VERSION ""

NS_ :

BS_:

BU_: WCM4 WCM3 WCM2 WCM VPM VLM VKM VICM VECM VDM VCU_RTOS_ETH VCU_ENTRY_ETH VCU_AGVM_ETH VCU UVM UPM TIM TEST_TOOL_1 TCP_ETH TCP TCM TCCM SRR_SRR_ETH SRR_SRR SRR_SLR_ETH SRR_SLR SRR_RR SRR_RF_ETH SRR_RF SRR_LR_CR SRR_LF_ETH SRR_LF SIB SDM SCL SBZA_R SBZA_L SBM SAM_RR SAM_RF SAM_LR SAM_LF SAM_BH SADS RadioLow_ETH RadioLow RSI_RTOS_ETH RSI RDCM PTM PLCM PFCM PDR_ETH PDR PCM PA ODS2 ODS NVM MTCM_R MTCM_L MSM_RR MSM_P MSM_LR MSM_D MSB2 MSB1 MRCM_R MRCM_L MFC LRR_RR_ETH LRR_LR_ETH LRR_CF_ETH LRR LRL_CF_ETH LIB_48V LIB1 IPC_INT IPC_GP IPC ICS_Info ICCM HVAC_FP_R HVAC_FP_F HUD_CAN HDLM FPI_RTOS_ETH FPI FOPM FCM_LC FCM EPSb EPS_1 EPSRAb EPSRAa EPS EOCM_HC_Superset EOCM_HCP2 EOCM ELM ECP_X1 ECP_S2 ECP_S ECP_MC ECP_H3 ECP_H2 ECP_H1 ECP_E ECM EBCM DMS DEFC DCM CSM_ETH CSM_AV CSM CGM_OTA_ETH CGM BSM_MH BSM_HEV BSM BCM ARS ARB APA AOS AMP ALC AHS AHL_AFL ADIMb ADIMa ACP2_MCU

BO_ 69 PDU_8065: 20 FCM_LC
 SG_ AdpLgtHstLnLtCrv : 7|16@0- (9.77e-07,0) [-0.0320143|0.0320134] "1/m" Vector__XXX
 SG_ AdpLgtHstLnLtCrvDrvt : 23|16@0- (3.73e-09,0) [-0.000122225|0.000122221] "1/m^2" Vector__XXX
 SG_ AdpLgtHstLnRtCrv : 39|16@0- (9.77e-07,0) [-0.0320143|0.0320134] "1/m" Vector__XXX
 SG_ AdpLgtHstLnRtCrvDrvt : 55|16@0- (3.73e-09,0) [-0.000122225|0.000122221] "1/m^2" Vector__XXX
 SG_ AdpLgtHstLnLtOfst : 71|13@0- (0.003906,0) [-15.999|15.9951] "m" Vector__XXX
 SG_ AdpLgtHstLnRtOfst : 74|13@0- (0.003906,0) [-15.999|15.9951] "m" Vector__XXX
 SG_ AdpLgtHstLnLtHdg : 93|10@0- (0.000977,0) [-0.500224|0.499247] "rad" Vector__XXX
 SG_ AdpLgtHstLnRtHdg : 99|10@0- (0.000977,0) [-0.500224|0.499247] "rad" Vector__XXX
 SG_ AdpLgtHstLnLtVwRngLngDist : 105|7@0+ (1,0) [0|127] "m" Vector__XXX
 SG_ AdpLgtHstLnLtVwStrtLngDist : 114|7@0+ (1,0) [0|127] "m" Vector__XXX
 SG_ AdpLgtHstLnRtVwRngLngDist : 123|7@0+ (1,0) [0|127] "m" Vector__XXX
 SG_ AdpLgtHstLnRtVwStrtLngDist : 132|7@0+ (1,0) [0|127] "m" Vector__XXX
 SG_ AdpLgtHstLnLtWdth : 141|6@0+ (0.01,0) [0|0.63] "m" Vector__XXX
 SG_ AdpLgtHstLnLtTyp : 145|3@0+ (1,0) [0|7] "" Vector__XXX
 SG_ AdpLgtHstLnRtWdth : 151|6@0+ (0.01,0) [0|0.63] "m" Vector__XXX
 SG_ AdpLgtHstLnRtQlty : 153|2@0+ (1,0) [0|3] "" Vector__XXX
 SG_ AdpLgtHstLnLtQlty : 155|2@0+ (1,0) [0|3] "" Vector__XXX
 SG_ AdpLgtHstLnRtTyp : 158|3@0+ (1,0) [0|7] "" Vector__XXX

BO_ 225 PDU_8066: 48 FCM_LC
 SG_ ALOI3_RngTk10 : 7|16@0+ (0.02,0) [0|1310.7] "m" Vector__XXX
 SG_ ALOI3_RngTk11 : 23|16@0+ (0.02,0) [0|1310.7] "m" Vector__XXX
 SG_ ALOI3_RngTk12 : 39|16@0+ (0.02,0) [0|1310.7] "m" Vector__XXX
 SG_ ALOI3_RngTk9 : 55|16@0+ (0.02,0) [0|1310.7] "m" Vector__XXX
 SG_ ALOI3_AcqTmStm : 71|11@0+ (1,0) [0|2047] "ms" Vector__XXX
 SG_ ALOI3_AzmRateTk10 : 76|11@0+ (0.125,-128) [-128|127.875] "deg/s" Vector__XXX
 SG_ ALOI3_AzmRateTk11 : 81|11@0+ (0.125,-128) [-128|127.875] "deg/s" Vector__XXX
 SG_ ALOI3_AzmRateTk12 : 102|11@0+ (0.125,-128) [-128|127.875] "deg/s" Vector__XXX
 SG_ ALOI3_AzmRateTk9 : 107|11@0+ (0.125,-128) [-128|127.875] "deg/s" Vector__XXX
 SG_ ALOI3_AzmTk10 : 112|11@0+ (0.05,-51.2) [-51.2|51.15] "deg" Vector__XXX
 SG_ ALOI3_AzmTk11 : 133|11@0+ (0.05,-51.2) [-51.2|51.15] "deg" Vector__XXX
 SG_ ALOI3_AzmTk12 : 138|11@0+ (0.05,-51.2) [-51.2|51.15] "deg" Vector__XXX
 SG_ ALOI3_AzmTk9 : 159|11@0+ (0.05,-51.2) [-51.2|51.15] "deg" Vector__XXX
 SG_ ALOI3_WdthTk10 : 164|11@0+ (0.1,0) [0|204.7] "deg" Vector__XXX
 SG_ ALOI3_WdthTk11 : 169|11@0+ (0.1,0) [0|204.7] "deg" Vector__XXX
 SG_ ALOI3_WdthTk12 : 190|11@0+ (0.1,0) [0|204.7] "deg" Vector__XXX
 SG_ ALOI3_WdthTk9 : 195|11@0+ (0.1,0) [0|204.7] "deg" Vector__XXX
 SG_ ALOI3_RdSigGlrngTk10 : 200|7@0+ (1,0) [0|127] "%" Vector__XXX
 SG_ ALOI3_RdSigGlrngTk11 : 209|7@0+ (1,0) [0|127] "%" Vector__XXX
 SG_ ALOI3_RdSigGlrngTk12 : 218|7@0+ (1,0) [0|127] "%" Vector__XXX
 SG_ ALOI3_RdSigGlrngTk9 : 227|7@0+ (1,0) [0|127] "%" Vector__XXX
 SG_ ALOI3_IDTk10 : 236|6@0+ (1,0) [0|63] "" Vector__XXX
 SG_ ALOI3_IDTk12 : 240|6@0+ (1,0) [0|63] "" Vector__XXX
 SG_ ALOI3_IDTk11 : 246|6@0+ (1,0) [0|63] "" Vector__XXX
 SG_ ALOI3_IDTk9 : 250|6@0+ (1,0) [0|63] "" Vector__XXX
 SG_ ALOI3_VertPstnTk10 : 260|6@0+ (0.25,-3) [-3|12.75] "deg" Vector__XXX
 SG_ ALOI3_VertPstnTk12 : 264|6@0+ (0.25,-3) [-3|12.75] "deg" Vector__XXX
 SG_ ALOI3_VertPstnTk11 : 270|6@0+ (0.25,-3) [-3|12.75] "deg" Vector__XXX
 SG_ ALOI3_VertPstnTk9 : 274|6@0+ (0.25,-3) [-3|12.75] "deg" Vector__XXX
 SG_ ALOI3_TypTk11 : 280|4@0+ (1,0) [0|12] "" Vector__XXX
 SG_ ALOI3_TypTk10 : 284|4@0+ (1,0) [0|12] "" Vector__XXX
 SG_ ALOI3_TypTk9 : 288|4@0+ (1,0) [0|12] "" Vector__XXX
 SG_ ALOI3_TypTk12 : 292|4@0+ (1,0) [0|12] "" Vector__XXX
 SG_ ALOI3_DirTk11 : 297|3@0+ (1,0) [0|4] "" Vector__XXX
 SG_ ALOI3_DirTk10 : 300|3@0+ (1,0) [0|4] "" Vector__XXX
 SG_ ALOI3_ARC : 304|2@0+ (1,0) [0|3] "" Vector__XXX
 SG_ ALOI3_DirTk9 : 307|3@0+ (1,0) [0|4] "" Vector__XXX
 SG_ ALOI3_DirTk12 : 310|3@0+ (1,0) [0|4] "" Vector__XXX
 SG_ ALOI3_CnfdTk9 : 312|2@0+ (1,0) [0|3] "" Vector__XXX
 SG_ ALOI3_CnfdTk12 : 314|2@0+ (1,0) [0|3] "" Vector__XXX
 SG_ ALOI3_CnfdTk11 : 316|2@0+ (1,0) [0|3] "" Vector__XXX
 SG_ ALOI3_CnfdTk10 : 318|2@0+ (1,0) [0|3] "" Vector__XXX
 SG_ ALOI3_MeasStsTk9 : 320|2@0+ (1,0) [0|3] "" Vector__XXX
 SG_ ALOI3_MeasStsTk12 : 322|2@0+ (1,0) [0|3] "" Vector__XXX
 SG_ ALOI3_MeasStsTk11 : 324|2@0+ (1,0) [0|3] "" Vector__XXX
 SG_ ALOI3_MeasStsTk10 : 326|2@0+ (1,0) [0|3] "" Vector__XXX
 SG_ ALOI3_RltvLnTk9 : 328|2@0+ (1,0) [0|3] "" Vector__XXX
 SG_ ALOI3_RltvLnTk12 : 330|2@0+ (1,0) [0|3] "" Vector__XXX
 SG_ ALOI3_RltvLnTk11 : 332|2@0+ (1,0) [0|3] "" Vector__XXX
 SG_ ALOI3_RltvLnTk10 : 334|2@0+ (1,0) [0|3] "" Vector__XXX
 SG_ TrfcSgnMemFtrSts : 337|2@0+ (1,0) [0|2] "" Vector__XXX
 SG_ ALOI3_RngTk9_Inv : 338|1@0+ (1,0) [0|1] "" Vector__XXX
 SG_ ALOI3_RngTk12_Inv : 339|1@0+ (1,0) [0|1] "" Vector__XXX
 SG_ ALOI3_RngTk11_Inv : 340|1@0+ (1,0) [0|1] "" Vector__XXX
 SG_ ALOI3_RngTk10_Inv : 341|1@0+ (1,0) [0|1] "" Vector__XXX
 SG_ ALOI3_AcqTmStm_Inv : 342|1@0+ (1,0) [0|1] "" Vector__XXX

BO_ 1444 PDU_9064: 2 CGM
 SG_ VehIdNmDig1 : 7|8@0+ (1,0) [0|255] "" HDLM

BO_ 963 NodeStatus_CAN8_PDU01: 8 CGM
 SG_ NodeStsADIMb_CAN_9_LcFA : 0|1@0+ (1,0) [0|1] "" EOCM_HCP2,FCM_LC,HDLM,LRR,SRR_LF,SRR_LR_CR,SRR_RF,SRR_RR,SRR_SLR,SRR_SRR,UPM
 SG_ NodeStsADIMb_CAN_3_LcFA : 1|1@0+ (1,0) [0|1] "" EOCM_HCP2,FCM_LC,HDLM,LRR,SRR_LF,SRR_LR_CR,SRR_RF,SRR_RR,SRR_SLR,SRR_SRR,UPM
 SG_ NodeStsADIMb_CAN_2_LcFA : 2|1@0+ (1,0) [0|1] "" EOCM_HCP2,FCM_LC,HDLM,LRR,SRR_LF,SRR_LR_CR,SRR_RF,SRR_RR,SRR_SLR,SRR_SRR,UPM
 SG_ NodeStsADIMb_CAN_10_LcFA : 3|1@0+ (1,0) [0|1] "" EOCM_HCP2,FCM_LC,HDLM,LRR,SRR_LF,SRR_LR_CR,SRR_RF,SRR_RR,SRR_SLR,SRR_SRR,UPM
 SG_ NodeStsADIMa_CAN_9_LcFA : 4|1@0+ (1,0) [0|1] "" EOCM_HCP2,FCM_LC,HDLM,LRR,SRR_LF,SRR_LR_CR,SRR_RF,SRR_RR,SRR_SLR,SRR_SRR,UPM
 SG_ NodeStsADIMa_CAN_3_LcFA : 5|1@0+ (1,0) [0|1] "" EOCM_HCP2,FCM_LC,HDLM,LRR,SRR_LF,SRR_LR_CR,SRR_RF,SRR_RR,SRR_SLR,SRR_SRR,UPM
 SG_ NodeStsADIMa_CAN_2_LcFA : 6|1@0+ (1,0) [0|1] "" EOCM_HCP2,FCM_LC,HDLM,LRR,SRR_LF,SRR_LR_CR,SRR_RF,SRR_RR,SRR_SLR,SRR_SRR,UPM
 SG_ NodeStsADIMa_CAN_10_LcFA : 7|1@0+ (1,0) [0|1] "" EOCM_HCP2,FCM_LC,HDLM,LRR,SRR_LF,SRR_LR_CR,SRR_RF,SRR_RR,SRR_SLR,SRR_SRR,UPM
 SG_ NodeStsAPA_CAN_1_LcFA : 8|1@0+ (1,0) [0|1] "" EOCM_HCP2,FCM_LC,HDLM,LRR,SRR_LF,SRR_LR_CR,SRR_RF,SRR_RR,SRR_SLR,SRR_SRR,UPM
 SG_ NodeStsAOS_LcFA : 10|1@0+ (1,0) [0|1] "" EOCM_HCP2,FCM_LC,HDLM,LRR,SRR_LF,SRR_LR_CR,SRR_RF,SRR_RR,SRR_SLR,SRR_SRR,UPM
 SG_ NodeStsAMP_LcFA : 11|1@0+ (1,0) [0|1] "" EOCM_HCP2,FCM_LC,HDLM,LRR,SRR_LF,SRR_LR_CR,SRR_RF,SRR_RR,SRR_SLR,SRR_SRR,UPM
 SG_ NodeStsALC_LcFA : 12|1@0+ (1,0) [0|1] "" EOCM_HCP2,FCM_LC,HDLM,LRR,SRR_LF,SRR_LR_CR,SRR_RF,SRR_RR,SRR_SLR,SRR_SRR,UPM
 SG_ NodeStsAHS_LcFA : 13|1@0+ (1,0) [0|1] "" EOCM_HCP2,FCM_LC,HDLM,LRR,SRR_LF,SRR_LR_CR,SRR_RF,SRR_RR,SRR_SLR,SRR_SRR,UPM
 SG_ NodeStsAHL_AFL_CAN_2_LcFA : 14|1@0+ (1,0) [0|1] "" EOCM_HCP2,FCM_LC,HDLM,LRR,SRR_LF,SRR_LR_CR,SRR_RF,SRR_RR,SRR_SLR,SRR_SRR,UPM
 SG_ NodeStsBSM_MH_LcFA : 17|1@0+ (1,0) [0|1] "" EOCM_HCP2,FCM_LC,HDLM,LRR,SRR_LF,SRR_LR_CR,SRR_RF,SRR_RR,SRR_SLR,SRR_SRR,UPM
 SG_ NodeStsBSM_CAN_3_LcFA : 18|1@0+ (1,0) [0|1] "" EOCM_HCP2,FCM_LC,HDLM,LRR,SRR_LF,SRR_LR_CR,SRR_RF,SRR_RR,SRR_SLR,SRR_SRR,UPM
 SG_ NodeStsBSM_CAN_2_LcFA : 19|1@0+ (1,0) [0|1] "" EOCM_HCP2,FCM_LC,HDLM,LRR,SRR_LF,SRR_LR_CR,SRR_RF,SRR_RR,SRR_SLR,SRR_SRR,UPM
 SG_ NodeStsBCM_LcFA : 20|1@0+ (1,0) [0|1] "" EOCM_HCP2,FCM_LC,HDLM,LRR,SRR_LF,SRR_LR_CR,SRR_RF,SRR_RR,SRR_SLR,SRR_SRR,UPM
 SG_ NodeStsARS_LcFA : 21|1@0+ (1,0) [0|1] "" EOCM_HCP2,FCM_LC,HDLM,LRR,SRR_LF,SRR_LR_CR,SRR_RF,SRR_RR,SRR_SLR,SRR_SRR,UPM
 SG_ NodeStsARB_LcFA : 22|1@0+ (1,0) [0|1] "" EOCM_HCP2,FCM_LC,HDLM,LRR,SRR_LF,SRR_LR_CR,SRR_RF,SRR_RR,SRR_SLR,SRR_SRR,UPM
 SG_ NodeStsAPA_CAN_2_LcFA : 23|1@0+ (1,0) [0|1] "" EOCM_HCP2,FCM_LC,HDLM,LRR,SRR_LF,SRR_LR_CR,SRR_RF,SRR_RR,SRR_SLR,SRR_SRR,UPM
 SG_ NodeStsEBCM_AV_CAN_2_LcFA : 24|1@0+ (1,0) [0|1] "" EOCM_HCP2,FCM_LC,HDLM,LRR,SRR_LF,SRR_LR_CR,SRR_RF,SRR_RR,SRR_SLR,SRR_SRR,UPM
 SG_ NodeStsDMS_LcFA : 25|1@0+ (1,0) [0|1] "" EOCM_HCP2,FCM_LC,HDLM,LRR,SRR_LF,SRR_LR_CR,SRR_RF,SRR_RR,SRR_SLR,SRR_SRR,UPM
 SG_ NodeStsDEFC_LcFA : 26|1@0+ (1,0) [0|1] "" EOCM_HCP2,FCM_LC,HDLM,LRR,SRR_LF,SRR_LR_CR,SRR_RF,SRR_RR,SRR_SLR,SRR_SRR,UPM
 SG_ NodeStsDCM_LcFA : 27|1@0+ (1,0) [0|1] "" EOCM_HCP2,FCM_LC,HDLM,LRR,SRR_LF,SRR_LR_CR,SRR_RF,SRR_RR,SRR_SLR,SRR_SRR,UPM
 SG_ NodeStsCSM_CAN_5_LcFA : 28|1@0+ (1,0) [0|1] "" EOCM_HCP2,FCM_LC,HDLM,LRR,SRR_LF,SRR_LR_CR,SRR_RF,SRR_RR,SRR_SLR,SRR_SRR,UPM
 SG_ NodeStsECP_E_CAN_9_LcFA : 32|1@0+ (1,0) [0|1] "" EOCM_HCP2,FCM_LC,HDLM,LRR,SRR_LF,SRR_LR_CR,SRR_RF,SRR_RR,SRR_SLR,SRR_SRR,UPM
 SG_ NodeStsECP_E_CAN_2_LcFA : 33|1@0+ (1,0) [0|1] "" EOCM_HCP2,FCM_LC,HDLM,LRR,SRR_LF,SRR_LR_CR,SRR_RF,SRR_RR,SRR_SLR,SRR_SRR,UPM
 SG_ NodeStsECM_CAN_3_LcFA : 34|1@0+ (1,0) [0|1] "" EOCM_HCP2,FCM_LC,HDLM,LRR,SRR_LF,SRR_LR_CR,SRR_RF,SRR_RR,SRR_SLR,SRR_SRR,UPM
 SG_ NodeStsECM_CAN_2_LcFA : 35|1@0+ (1,0) [0|1] "" EOCM_HCP2,FCM_LC,HDLM,LRR,SRR_LF,SRR_LR_CR,SRR_RF,SRR_RR,SRR_SLR,SRR_SRR,UPM
 SG_ NodeStsEBCM_CAN_3_LcFA : 37|1@0+ (1,0) [0|1] "" EOCM_HCP2,FCM_LC,HDLM,LRR,SRR_LF,SRR_LR_CR,SRR_RF,SRR_RR,SRR_SLR,SRR_SRR,UPM
 SG_ NodeStsEBCM_CAN_2_LcFA : 38|1@0+ (1,0) [0|1] "" EOCM_HCP2,FCM_LC,HDLM,LRR,SRR_LF,SRR_LR_CR,SRR_RF,SRR_RR,SRR_SLR,SRR_SRR,UPM
 SG_ NodeStsEBCM_AV_CAN_3_LcFA : 39|1@0+ (1,0) [0|1] "" EOCM_HCP2,FCM_LC,HDLM,LRR,SRR_LF,SRR_LR_CR,SRR_RF,SRR_RR,SRR_SLR,SRR_SRR,UPM
 SG_ NodeStsEOCM_CAN_3_LcFA : 40|1@0+ (1,0) [0|1] "" EOCM_HCP2,FCM_LC,HDLM,LRR,SRR_LF,SRR_LR_CR,SRR_RF,SRR_RR,SRR_SLR,SRR_SRR,UPM
 SG_ NodeStsEOCM_CAN_2_LcFA : 41|1@0+ (1,0) [0|1] "" EOCM_HCP2,FCM_LC,HDLM,LRR,SRR_LF,SRR_LR_CR,SRR_RF,SRR_RR,SRR_SLR,SRR_SRR,UPM
 SG_ NodeStsELM_LcFA : 42|1@0+ (1,0) [0|1] "" EOCM_HCP2,FCM_LC,HDLM,LRR,SRR_LF,SRR_LR_CR,SRR_RF,SRR_RR,SRR_SLR,SRR_SRR,UPM
 SG_ NodeStsECP_X1_CAN_3_LcFA : 43|1@0+ (1,0) [0|1] "" EOCM_HCP2,FCM_LC,HDLM,LRR,SRR_LF,SRR_LR_CR,SRR_RF,SRR_RR,SRR_SLR,SRR_SRR,UPM
 SG_ NodeStsECP_X1_CAN_2_LcFA : 44|1@0+ (1,0) [0|1] "" EOCM_HCP2,FCM_LC,HDLM,LRR,SRR_LF,SRR_LR_CR,SRR_RF,SRR_RR,SRR_SLR,SRR_SRR,UPM
 SG_ NodeStsECP_S_CAN_9_LcFA : 45|1@0+ (1,0) [0|1] "" EOCM_HCP2,FCM_LC,HDLM,LRR,SRR_LF,SRR_LR_CR,SRR_RF,SRR_RR,SRR_SLR,SRR_SRR,UPM
 SG_ NodeStsECP_S_CAN_2_LcFA : 46|1@0+ (1,0) [0|1] "" EOCM_HCP2,FCM_LC,HDLM,LRR,SRR_LF,SRR_LR_CR,SRR_RF,SRR_RR,SRR_SLR,SRR_SRR,UPM
 SG_ NodeStsECP_MC_LcFA : 47|1@0+ (1,0) [0|1] "" EOCM_HCP2,FCM_LC,HDLM,LRR,SRR_LF,SRR_LR_CR,SRR_RF,SRR_RR,SRR_SLR,SRR_SRR,UPM
 SG_ NodeStsEPSRAa_LcFA : 48|1@0+ (1,0) [0|1] "" EOCM_HCP2,FCM_LC,HDLM,LRR,SRR_LF,SRR_LR_CR,SRR_RF,SRR_RR,SRR_SLR,SRR_SRR,UPM
 SG_ NodeStsEPS_LcFA : 49|1@0+ (1,0) [0|1] "" EOCM_HCP2,FCM_LC,HDLM,LRR,SRR_LF,SRR_LR_CR,SRR_RF,SRR_RR,SRR_SLR,SRR_SRR,UPM
 SG_ NodeStsEPS_1_LcFA : 50|1@0+ (1,0) [0|1] "" EOCM_HCP2,FCM_LC,HDLM,LRR,SRR_LF,SRR_LR_CR,SRR_RF,SRR_RR,SRR_SLR,SRR_SRR,UPM
 SG_ NodeStsEOCM_HCP2_LcFA : 51|1@0+ (1,0) [0|1] "" FCM_LC,HDLM,LRR,SRR_LF,SRR_LR_CR,SRR_RF,SRR_RR,SRR_SLR,SRR_SRR,UPM
 SG_ NodeStsEOCM_HCP1_CAN_8_LcFA : 52|1@0+ (1,0) [0|1] "" EOCM_HCP2,FCM_LC,HDLM,LRR,SRR_LF,SRR_LR_CR,SRR_RF,SRR_RR,SRR_SLR,SRR_SRR,UPM
 SG_ NodeStsEOCM_HCP1_CAN_3_LcFA : 53|1@0+ (1,0) [0|1] "" EOCM_HCP2,FCM_LC,HDLM,LRR,SRR_LF,SRR_LR_CR,SRR_RF,SRR_RR,SRR_SLR,SRR_SRR,UPM
 SG_ NodeStsEOCM_HCP1_CAN_2_LcFA : 54|1@0+ (1,0) [0|1] "" EOCM_HCP2,FCM_LC,HDLM,LRR,SRR_LF,SRR_LR_CR,SRR_RF,SRR_RR,SRR_SLR,SRR_SRR,UPM
 SG_ NodeStsEOCM_CAN_8_LcFA : 55|1@0+ (1,0) [0|1] "" EOCM_HCP2,FCM_LC,HDLM,LRR,SRR_LF,SRR_LR_CR,SRR_RF,SRR_RR,SRR_SLR,SRR_SRR,UPM
 SG_ NodeStsHVAC_FP_F_LcFA : 56|1@0+ (1,0) [0|1] "" EOCM_HCP2,FCM_LC,HDLM,LRR,SRR_LF,SRR_LR_CR,SRR_RF,SRR_RR,SRR_SLR,SRR_SRR,UPM
 SG_ NodeStsHUD_CAN_LcFA : 57|1@0+ (1,0) [0|1] "" EOCM_HCP2,FCM_LC,HDLM,LRR,SRR_LF,SRR_LR_CR,SRR_RF,SRR_RR,SRR_SLR,SRR_SRR,UPM
 SG_ NodeStsHDLM_LcFA : 58|1@0+ (1,0) [0|1] "" EOCM_HCP2,FCM_LC,LRR,SRR_LF,SRR_LR_CR,SRR_RF,SRR_RR,SRR_SLR,SRR_SRR,UPM
 SG_ NodeStsFOPM_CAN_3_LcFA : 59|1@0+ (1,0) [0|1] "" EOCM_HCP2,FCM_LC,HDLM,LRR,SRR_LF,SRR_LR_CR,SRR_RF,SRR_RR,SRR_SLR,SRR_SRR,UPM
 SG_ NodeStsFOPM_CAN_2_LcFA : 60|1@0+ (1,0) [0|1] "" EOCM_HCP2,FCM_LC,HDLM,LRR,SRR_LF,SRR_LR_CR,SRR_RF,SRR_RR,SRR_SLR,SRR_SRR,UPM
 SG_ NodeStsFCM_LcFA : 61|1@0+ (1,0) [0|1] "" EOCM_HCP2,FCM_LC,HDLM,LRR,SRR_LF,SRR_LR_CR,SRR_RF,SRR_RR,SRR_SLR,SRR_SRR,UPM
 SG_ NodeStsFCM_LC_LcFA : 62|1@0+ (1,0) [0|1] "" EOCM_HCP2,HDLM,LRR,SRR_LF,SRR_LR_CR,SRR_RF,SRR_RR,SRR_SLR,SRR_SRR,UPM
 SG_ NodeStsEPSRAb_LcFA : 63|1@0+ (1,0) [0|1] "" EOCM_HCP2,FCM_LC,HDLM,LRR,SRR_LF,SRR_LR_CR,SRR_RF,SRR_RR,SRR_SLR,SRR_SRR,UPM

BO_ 964 NodeStatus_CAN8_PDU02: 8 CGM
 SG_ NodeStsMFC_LcFA : 0|1@0+ (1,0) [0|1] "" EOCM_HCP2,FCM_LC,HDLM,LRR,SRR_LF,SRR_LR_CR,SRR_RF,SRR_RR,SRR_SLR,SRR_SRR,UPM
 SG_ NodeStsLRR_LcFA : 1|1@0+ (1,0) [0|1] "" EOCM_HCP2,FCM_LC,HDLM,SRR_LF,SRR_LR_CR,SRR_RF,SRR_RR,SRR_SLR,SRR_SRR,UPM
 SG_ NodeStsLIB1_LcFA : 3|1@0+ (1,0) [0|1] "" EOCM_HCP2,FCM_LC,HDLM,LRR,SRR_LF,SRR_LR_CR,SRR_RF,SRR_RR,SRR_SLR,SRR_SRR,UPM
 SG_ NodeStsIPC_CAN_5_LcFA : 4|1@0+ (1,0) [0|1] "" EOCM_HCP2,FCM_LC,HDLM,LRR,SRR_LF,SRR_LR_CR,SRR_RF,SRR_RR,SRR_SLR,SRR_SRR,UPM
 SG_ NodeStsICS_Info_LcFA : 5|1@0+ (1,0) [0|1] "" EOCM_HCP2,FCM_LC,HDLM,LRR,SRR_LF,SRR_LR_CR,SRR_RF,SRR_RR,SRR_SLR,SRR_SRR,UPM
 SG_ NodeStsICCM_CAN_3_LcFA : 6|1@0+ (1,0) [0|1] "" EOCM_HCP2,FCM_LC,HDLM,LRR,SRR_LF,SRR_LR_CR,SRR_RF,SRR_RR,SRR_SLR,SRR_SRR,UPM
 SG_ NodeStsHVAC_FP_R_LcFA : 7|1@0+ (1,0) [0|1] "" EOCM_HCP2,FCM_LC,HDLM,LRR,SRR_LF,SRR_LR_CR,SRR_RF,SRR_RR,SRR_SLR,SRR_SRR,UPM
 SG_ NodeStsMSM_RR_LcFA : 8|1@0+ (1,0) [0|1] "" EOCM_HCP2,FCM_LC,HDLM,LRR,SRR_LF,SRR_LR_CR,SRR_RF,SRR_RR,SRR_SLR,SRR_SRR,UPM
 SG_ NodeStsMSM_P_LcFA : 9|1@0+ (1,0) [0|1] "" EOCM_HCP2,FCM_LC,HDLM,LRR,SRR_LF,SRR_LR_CR,SRR_RF,SRR_RR,SRR_SLR,SRR_SRR,UPM
 SG_ NodeStsMSM_LR_LcFA : 10|1@0+ (1,0) [0|1] "" EOCM_HCP2,FCM_LC,HDLM,LRR,SRR_LF,SRR_LR_CR,SRR_RF,SRR_RR,SRR_SLR,SRR_SRR,UPM
 SG_ NodeStsMSM_D_LcFA : 11|1@0+ (1,0) [0|1] "" EOCM_HCP2,FCM_LC,HDLM,LRR,SRR_LF,SRR_LR_CR,SRR_RF,SRR_RR,SRR_SLR,SRR_SRR,UPM
 SG_ NodeStsMSB2_LcFA : 12|1@0+ (1,0) [0|1] "" EOCM_HCP2,FCM_LC,HDLM,LRR,SRR_LF,SRR_LR_CR,SRR_RF,SRR_RR,SRR_SLR,SRR_SRR,UPM
 SG_ NodeStsMSB1_LcFA : 13|1@0+ (1,0) [0|1] "" EOCM_HCP2,FCM_LC,HDLM,LRR,SRR_LF,SRR_LR_CR,SRR_RF,SRR_RR,SRR_SLR,SRR_SRR,UPM
 SG_ NodeStsMRCM_R_LcFA : 14|1@0+ (1,0) [0|1] "" EOCM_HCP2,FCM_LC,HDLM,LRR,SRR_LF,SRR_LR_CR,SRR_RF,SRR_RR,SRR_SLR,SRR_SRR,UPM
 SG_ NodeStsMRCM_L_LcFA : 15|1@0+ (1,0) [0|1] "" EOCM_HCP2,FCM_LC,HDLM,LRR,SRR_LF,SRR_LR_CR,SRR_RF,SRR_RR,SRR_SLR,SRR_SRR,UPM
 SG_ NodeStsRDCM_LcFA : 16|1@0+ (1,0) [0|1] "" EOCM_HCP2,FCM_LC,HDLM,LRR,SRR_LF,SRR_LR_CR,SRR_RF,SRR_RR,SRR_SLR,SRR_SRR,UPM
 SG_ NodeStsRadioLow_LcFA : 17|1@0+ (1,0) [0|1] "" EOCM_HCP2,FCM_LC,HDLM,LRR,SRR_LF,SRR_LR_CR,SRR_RF,SRR_RR,SRR_SLR,SRR_SRR,UPM
 SG_ NodeStsPTM_LcFA : 18|1@0+ (1,0) [0|1] "" EOCM_HCP2,FCM_LC,HDLM,LRR,SRR_LF,SRR_LR_CR,SRR_RF,SRR_RR,SRR_SLR,SRR_SRR,UPM
 SG_ NodeStsPDR_LcFA : 19|1@0+ (1,0) [0|1] "" EOCM_HCP2,FCM_LC,HDLM,LRR,SRR_LF,SRR_LR_CR,SRR_RF,SRR_RR,SRR_SLR,SRR_SRR,UPM
 SG_ NodeStsPA_LcFA : 20|1@0+ (1,0) [0|1] "" EOCM_HCP2,FCM_LC,HDLM,LRR,SRR_LF,SRR_LR_CR,SRR_RF,SRR_RR,SRR_SLR,SRR_SRR,UPM
 SG_ NodeStsNVM_LcFA : 21|1@0+ (1,0) [0|1] "" EOCM_HCP2,FCM_LC,HDLM,LRR,SRR_LF,SRR_LR_CR,SRR_RF,SRR_RR,SRR_SLR,SRR_SRR,UPM
 SG_ NodeStsMTCM_R_LcFA : 22|1@0+ (1,0) [0|1] "" EOCM_HCP2,FCM_LC,HDLM,LRR,SRR_LF,SRR_LR_CR,SRR_RF,SRR_RR,SRR_SLR,SRR_SRR,UPM
 SG_ NodeStsMTCM_L_LcFA : 23|1@0+ (1,0) [0|1] "" EOCM_HCP2,FCM_LC,HDLM,LRR,SRR_LF,SRR_LR_CR,SRR_RF,SRR_RR,SRR_SLR,SRR_SRR,UPM
 SG_ NodeStsSBM_CAN_3_LcFA : 25|1@0+ (1,0) [0|1] "" EOCM_HCP2,FCM_LC,HDLM,LRR,SRR_LF,SRR_LR_CR,SRR_RF,SRR_RR,SRR_SLR,SRR_SRR,UPM
 SG_ NodeStsSAM_RR_LcFA : 26|1@0+ (1,0) [0|1] "" EOCM_HCP2,FCM_LC,HDLM,LRR,SRR_LF,SRR_LR_CR,SRR_RF,SRR_RR,SRR_SLR,SRR_SRR,UPM
 SG_ NodeStsSAM_RF_LcFA : 27|1@0+ (1,0) [0|1] "" EOCM_HCP2,FCM_LC,HDLM,LRR,SRR_LF,SRR_LR_CR,SRR_RF,SRR_RR,SRR_SLR,SRR_SRR,UPM
 SG_ NodeStsSAM_LR_LcFA : 28|1@0+ (1,0) [0|1] "" EOCM_HCP2,FCM_LC,HDLM,LRR,SRR_LF,SRR_LR_CR,SRR_RF,SRR_RR,SRR_SLR,SRR_SRR,UPM
 SG_ NodeStsSAM_LF_LcFA : 29|1@0+ (1,0) [0|1] "" EOCM_HCP2,FCM_LC,HDLM,LRR,SRR_LF,SRR_LR_CR,SRR_RF,SRR_RR,SRR_SLR,SRR_SRR,UPM
 SG_ NodeStsSADS_LcFA : 30|1@0+ (1,0) [0|1] "" EOCM_HCP2,FCM_LC,HDLM,LRR,SRR_LF,SRR_LR_CR,SRR_RF,SRR_RR,SRR_SLR,SRR_SRR,UPM
 SG_ NodeStsSRR_RF_LcFA : 32|1@0+ (1,0) [0|1] "" EOCM_HCP2,FCM_LC,HDLM,LRR,SRR_LF,SRR_LR_CR,SRR_RR,SRR_SLR,SRR_SRR,UPM
 SG_ NodeStsSRR_LR_CR_LcFA : 33|1@0+ (1,0) [0|1] "" EOCM_HCP2,FCM_LC,HDLM,LRR,SRR_LF,SRR_RF,SRR_RR,SRR_SLR,SRR_SRR,UPM
 SG_ NodeStsSRR_LF_LcFA : 34|1@0+ (1,0) [0|1] "" EOCM_HCP2,FCM_LC,HDLM,LRR,SRR_LR_CR,SRR_RF,SRR_RR,SRR_SLR,SRR_SRR,UPM
 SG_ NodeStsSIB_LcFA : 35|1@0+ (1,0) [0|1] "" EOCM_HCP2,FCM_LC,HDLM,LRR,SRR_LF,SRR_LR_CR,SRR_RF,SRR_RR,SRR_SLR,SRR_SRR,UPM
 SG_ NodeStsSDM_LcFA : 36|1@0+ (1,0) [0|1] "" EOCM_HCP2,FCM_LC,HDLM,LRR,SRR_LF,SRR_LR_CR,SRR_RF,SRR_RR,SRR_SLR,SRR_SRR,UPM
 SG_ NodeStsSCL_LcFA : 37|1@0+ (1,0) [0|1] "" EOCM_HCP2,FCM_LC,HDLM,LRR,SRR_LF,SRR_LR_CR,SRR_RF,SRR_RR,SRR_SLR,SRR_SRR,UPM
 SG_ NodeStsSBZA_R_LcFA : 38|1@0+ (1,0) [0|1] "" ACP2_MCU,EOCM_HCP2,FCM_LC,HDLM,LRR,SRR_LF,SRR_LR_CR,SRR_RF,SRR_RR,SRR_SLR,SRR_SRR,UPM
 SG_ NodeStsSBZA_L_LcFA : 39|1@0+ (1,0) [0|1] "" ACP2_MCU,EOCM_HCP2,FCM_LC,HDLM,LRR,SRR_LF,SRR_LR_CR,SRR_RF,SRR_RR,SRR_SLR,SRR_SRR,UPM
 SG_ NodeStsTCP_CAN_5_LcFA : 40|1@0+ (1,0) [0|1] "" EOCM_HCP2,FCM_LC,HDLM,LRR,SRR_LF,SRR_LR_CR,SRR_RF,SRR_RR,SRR_SLR,SRR_SRR,UPM
 SG_ NodeStsTCM_CAN_2_LcFA : 41|1@0+ (1,0) [0|1] "" EOCM_HCP2,FCM_LC,HDLM,LRR,SRR_LF,SRR_LR_CR,SRR_RF,SRR_RR,SRR_SLR,SRR_SRR,UPM
 SG_ NodeStsTCCM_LcFA : 43|1@0+ (1,0) [0|1] "" EOCM_HCP2,FCM_LC,HDLM,LRR,SRR_LF,SRR_LR_CR,SRR_RF,SRR_RR,SRR_SLR,SRR_SRR,UPM
 SG_ NodeStsSRR_SRR_LcFA : 45|1@0+ (1,0) [0|1] "" EOCM_HCP2,FCM_LC,HDLM,LRR,SRR_LF,SRR_LR_CR,SRR_RF,SRR_RR,SRR_SLR,UPM
 SG_ NodeStsSRR_SLR_LcFA : 46|1@0+ (1,0) [0|1] "" EOCM_HCP2,FCM_LC,HDLM,LRR,SRR_LF,SRR_LR_CR,SRR_RF,SRR_RR,SRR_SRR,UPM
 SG_ NodeStsSRR_RR_LcFA : 47|1@0+ (1,0) [0|1] "" EOCM_HCP2,FCM_LC,HDLM,LRR,SRR_LF,SRR_LR_CR,SRR_RF,SRR_SLR,SRR_SRR,UPM
 SG_ NodeStsWCM_LcFA : 48|1@0+ (1,0) [0|1] "" EOCM_HCP2,FCM_LC,HDLM,LRR,SRR_LF,SRR_LR_CR,SRR_RF,SRR_RR,SRR_SLR,SRR_SRR,UPM
 SG_ NodeStsVPM_LcFA : 49|1@0+ (1,0) [0|1] "" EOCM_HCP2,FCM_LC,HDLM,LRR,SRR_LF,SRR_LR_CR,SRR_RF,SRR_RR,SRR_SLR,SRR_SRR,UPM
 SG_ NodeStsVLM_LcFA : 50|1@0+ (1,0) [0|1] "" EOCM_HCP2,FCM_LC,HDLM,LRR,SRR_LF,SRR_LR_CR,SRR_RF,SRR_RR,SRR_SLR,SRR_SRR,UPM
 SG_ NodeStsVKM_LcFA : 51|1@0+ (1,0) [0|1] "" EOCM_HCP2,FCM_LC,HDLM,LRR,SRR_LF,SRR_LR_CR,SRR_RF,SRR_RR,SRR_SLR,SRR_SRR,UPM
 SG_ NodeStsVICM_CAN_9_LcFA : 52|1@0+ (1,0) [0|1] "" EOCM_HCP2,FCM_LC,HDLM,LRR,SRR_LF,SRR_LR_CR,SRR_RF,SRR_RR,SRR_SLR,SRR_SRR,UPM
 SG_ NodeStsVICM_CAN_2_LcFA : 53|1@0+ (1,0) [0|1] "" EOCM_HCP2,FCM_LC,HDLM,LRR,SRR_LF,SRR_LR_CR,SRR_RF,SRR_RR,SRR_SLR,SRR_SRR,UPM
 SG_ NodeStsVCU_CAN_5_LcFA : 54|1@0+ (1,0) [0|1] "" EOCM_HCP2,FCM_LC,HDLM,LRR,SRR_LF,SRR_LR_CR,SRR_RF,SRR_RR,SRR_SLR,SRR_SRR,UPM
 SG_ NodeStsTIM_LcFA : 55|1@0+ (1,0) [0|1] "" EOCM_HCP2,FCM_LC,HDLM,LRR,SRR_LF,SRR_LR_CR,SRR_RF,SRR_RR,SRR_SLR,SRR_SRR,UPM
 SG_ NodeStsECP_S2_CAN_2_LcFA : 56|1@0+ (1,0) [0|1] "" EOCM_HCP2,FCM_LC,HDLM,LRR,SRR_LF,SRR_LR_CR,SRR_RF,SRR_RR,SRR_SLR,SRR_SRR,UPM
 SG_ NodeStsPFCM_LcFA : 57|1@0+ (1,0) [0|1] "" EOCM_HCP2,FCM_LC,HDLM,LRR,SRR_LF,SRR_LR_CR,SRR_RF,SRR_RR,SRR_SLR,SRR_SRR,UPM
 SG_ NodeStsVDM_CAN_2_LcFA : 58|1@0+ (1,0) [0|1] "" EOCM_HCP2,FCM_LC,HDLM,LRR,SRR_LF,SRR_LR_CR,SRR_RF,SRR_RR,SRR_SLR,SRR_SRR,UPM
 SG_ NodeStsPCM_CAN_3_LcFA : 60|1@0+ (1,0) [0|1] "" EOCM_HCP2,FCM_LC,HDLM,LRR,SRR_LF,SRR_LR_CR,SRR_RF,SRR_RR,SRR_SLR,SRR_SRR,UPM
 SG_ NodeStsPCM_CAN_2_LcFA : 61|1@0+ (1,0) [0|1] "" EOCM_HCP2,FCM_LC,HDLM,LRR,SRR_LF,SRR_LR_CR,SRR_RF,SRR_RR,SRR_SLR,SRR_SRR,UPM
 SG_ NodeStsSDM_AV_LcFA : 62|1@0+ (1,0) [0|1] "" EOCM_HCP2,FCM_LC,HDLM,LRR,SRR_LF,SRR_LR_CR,SRR_RF,SRR_RR,SRR_SLR,SRR_SRR,UPM

BO_ 962 NodeStatus_CAN8_PDU03: 8 CGM
 SG_ NodeStsACP4_MCU_CAN_2_LcFA : 0|1@0+ (1,0) [0|1] "" EOCM_HCP2,FCM_LC,HDLM,LRR,SRR_LF,SRR_LR_CR,SRR_RF,SRR_RR,SRR_SLR,SRR_SRR,UPM
 SG_ NodeStsACP2_MCU_CAN_8_LcFA : 1|1@0+ (1,0) [0|1] "" EOCM_HCP2,FCM_LC,HDLM,LRR,SRR_LF,SRR_LR_CR,SRR_RF,SRR_RR,SRR_SLR,SRR_SRR,UPM
 SG_ NodeStsACP2_MCU_CAN_2_LcFA : 2|1@0+ (1,0) [0|1] "" EOCM_HCP2,FCM_LC,HDLM,LRR,SRR_LF,SRR_LR_CR,SRR_RF,SRR_RR,SRR_SLR,SRR_SRR,UPM
 SG_ NodeStsVECM_CAN_2_LcFA : 3|1@0+ (1,0) [0|1] "" EOCM_HCP2,FCM_LC,HDLM,LRR,SRR_LF,SRR_LR_CR,SRR_RF,SRR_RR,SRR_SLR,SRR_SRR,UPM
 SG_ NodeStsVDM_CAN_9_LcFA : 4|1@0+ (1,0) [0|1] "" EOCM_HCP2,FCM_LC,HDLM,LRR,SRR_LF,SRR_LR_CR,SRR_RF,SRR_RR,SRR_SLR,SRR_SRR,UPM
 SG_ NodeStsUVM_CAN_1_LcFA : 5|1@0+ (1,0) [0|1] "" EOCM_HCP2,FCM_LC,HDLM,LRR,SRR_LF,SRR_LR_CR,SRR_RF,SRR_RR,SRR_SLR,SRR_SRR,UPM
 SG_ NodeStsUPM_LcFA : 6|1@0+ (1,0) [0|1] "" EOCM_HCP2,FCM_LC,HDLM,LRR,SRR_LF,SRR_LR_CR,SRR_RF,SRR_RR,SRR_SLR,SRR_SRR
 SG_ NodeStsEPSb_LcFA : 7|1@0+ (1,0) [0|1] "" EOCM_HCP2,FCM_LC,HDLM,LRR,SRR_LF,SRR_LR_CR,SRR_RF,SRR_RR,SRR_SLR,SRR_SRR,UPM
 SG_ NodeStsSBM_CAN_10_LcFA : 8|1@0+ (1,0) [0|1] "" EOCM_HCP2,FCM_LC,HDLM,LRR,SRR_LF,SRR_LR_CR,SRR_RF,SRR_RR,SRR_SLR,SRR_SRR,UPM
 SG_ NodeStsVECM_CAN_9_LcFA : 9|1@0+ (1,0) [0|1] "" EOCM_HCP2,FCM_LC,HDLM,LRR,SRR_LF,SRR_LR_CR,SRR_RF,SRR_RR,SRR_SLR,SRR_SRR,UPM
 SG_ NodeStsECP_S2_CAN_9_LcFA : 11|1@0+ (1,0) [0|1] "" EOCM_HCP2,FCM_LC,HDLM,LRR,SRR_LF,SRR_LR_CR,SRR_RF,SRR_RR,SRR_SLR,SRR_SRR,UPM
 SG_ NodeStsCSM_AV_CAN_5_LcFA : 12|1@0+ (1,0) [0|1] "" EOCM_HCP2,FCM_LC,HDLM,LRR,SRR_LF,SRR_LR_CR,SRR_RF,SRR_RR,SRR_SLR,SRR_SRR,UPM
 SG_ NodeStsACP3_MCU_CAN_3_LcFA : 13|1@0+ (1,0) [0|1] "" EOCM_HCP2,FCM_LC,HDLM,LRR,SRR_LF,SRR_LR_CR,SRR_RF,SRR_RR,SRR_SLR,SRR_SRR,UPM
 SG_ NodeStsACP3_MCU_CAN_8_LcFA : 14|1@0+ (1,0) [0|1] "" EOCM_HCP2,FCM_LC,HDLM,LRR,SRR_LF,SRR_LR_CR,SRR_RF,SRR_RR,SRR_SLR,SRR_SRR,UPM
 SG_ NodeStsACP3_MCU_CAN_2_LcFA : 15|1@0+ (1,0) [0|1] "" EOCM_HCP2,FCM_LC,HDLM,LRR,SRR_LF,SRR_LR_CR,SRR_RF,SRR_RR,SRR_SLR,SRR_SRR,UPM
 SG_ NodeStsWCM4_LcFA : 16|1@0+ (1,0) [0|1] "" EOCM_HCP2,FCM_LC,HDLM,LRR,SRR_LF,SRR_LR_CR,SRR_RF,SRR_RR,SRR_SLR,SRR_SRR,UPM
 SG_ NodeStsWCM3_LcFA : 17|1@0+ (1,0) [0|1] "" EOCM_HCP2,FCM_LC,HDLM,LRR,SRR_LF,SRR_LR_CR,SRR_RF,SRR_RR,SRR_SLR,SRR_SRR,UPM
 SG_ NodeStsWCM2_LcFA : 18|1@0+ (1,0) [0|1] "" EOCM_HCP2,FCM_LC,HDLM,LRR,SRR_LF,SRR_LR_CR,SRR_RF,SRR_RR,SRR_SLR,SRR_SRR,UPM
 SG_ NodeStsRSI_CAN_5_LcFA : 19|1@0+ (1,0) [0|1] "" EOCM_HCP2,FCM_LC,HDLM,LRR,SRR_LF,SRR_LR_CR,SRR_RF,SRR_RR,SRR_SLR,SRR_SRR,UPM
 SG_ NodeStsLIB_48V_LcFA : 20|1@0+ (1,0) [0|1] "" EOCM_HCP2,FCM_LC,HDLM,LRR,SRR_LF,SRR_LR_CR,SRR_RF,SRR_RR,SRR_SLR,SRR_SRR,UPM
 SG_ NodeStsFPI_CAN_5_LcFA : 21|1@0+ (1,0) [0|1] "" EOCM_HCP2,FCM_LC,HDLM,LRR,SRR_LF,SRR_LR_CR,SRR_RF,SRR_RR,SRR_SLR,SRR_SRR,UPM
 SG_ NodeStsACP4_MCU_CAN_3_LcFA : 22|1@0+ (1,0) [0|1] "" EOCM_HCP2,FCM_LC,HDLM,LRR,SRR_LF,SRR_LR_CR,SRR_RF,SRR_RR,SRR_SLR,SRR_SRR,UPM
 SG_ NodeStsACP4_MCU_CAN_8_LcFA : 23|1@0+ (1,0) [0|1] "" EOCM_HCP2,FCM_LC,HDLM,LRR,SRR_LF,SRR_LR_CR,SRR_RF,SRR_RR,SRR_SLR,SRR_SRR,UPM
 SG_ NodeStsBSM_HEV_CAN_2_LcFA : 24|1@0+ (1,0) [0|1] "" EOCM_HCP2,FCM_LC,HDLM,LRR,SRR_LF,SRR_LR_CR,SRR_RF,SRR_RR,SRR_SLR,SRR_SRR,UPM
 SG_ NodeStsECP_H3_CAN_2_LcFA : 25|1@0+ (1,0) [0|1] "" EOCM_HCP2,FCM_LC,HDLM,LRR,SRR_LF,SRR_LR_CR,SRR_RF,SRR_RR,SRR_SLR,SRR_SRR,UPM
 SG_ NodeStsECP_H2_CAN_2_LcFA : 26|1@0+ (1,0) [0|1] "" EOCM_HCP2,FCM_LC,HDLM,LRR,SRR_LF,SRR_LR_CR,SRR_RF,SRR_RR,SRR_SLR,SRR_SRR,UPM
 SG_ NodeStsECP_H2_CAN_9_LcFA : 27|1@0+ (1,0) [0|1] "" EOCM_HCP2,FCM_LC,HDLM,LRR,SRR_LF,SRR_LR_CR,SRR_RF,SRR_RR,SRR_SLR,SRR_SRR,UPM
 SG_ NodeStsECP_H1_CAN_9_LcFA : 28|1@0+ (1,0) [0|1] "" EOCM_HCP2,FCM_LC,HDLM,LRR,SRR_LF,SRR_LR_CR,SRR_RF,SRR_RR,SRR_SLR,SRR_SRR,UPM
 SG_ NodeStsECP_H1_CAN_2_LcFA : 29|1@0+ (1,0) [0|1] "" EOCM_HCP2,FCM_LC,HDLM,LRR,SRR_LF,SRR_LR_CR,SRR_RF,SRR_RR,SRR_SLR,SRR_SRR,UPM
 SG_ NodeStsBSM_HEV_CAN_9_LcFA : 30|1@0+ (1,0) [0|1] "" EOCM_HCP2,FCM_LC,HDLM,LRR,SRR_LF,SRR_LR_CR,SRR_RF,SRR_RR,SRR_SLR,SRR_SRR,UPM
 SG_ NodeStsECP_H3_CAN_9_LcFA : 31|1@0+ (1,0) [0|1] "" EOCM_HCP2,FCM_LC,HDLM,LRR,SRR_LF,SRR_LR_CR,SRR_RF,SRR_RR,SRR_SLR,SRR_SRR,UPM
 SG_ NodeStsSAM_BH_LcFA : 36|1@0+ (1,0) [0|1] "" EOCM_HCP2,FCM_LC,HDLM,LRR,SRR_LF,SRR_LR_CR,SRR_RF,SRR_RR,SRR_SLR,SRR_SRR,UPM
 SG_ NodeStsPLCM_LcFA : 37|1@0+ (1,0) [0|1] "" EOCM_HCP2,FCM_LC,HDLM,LRR,SRR_LF,SRR_LR_CR,SRR_RF,SRR_RR,SRR_SLR,SRR_SRR,UPM
 SG_ NodeStsODS_LcFA : 38|1@0+ (1,0) [0|1] "" EOCM_HCP2,FCM_LC,HDLM,LRR,SRR_LF,SRR_LR_CR,SRR_RF,SRR_RR,SRR_SLR,SRR_SRR,UPM
 SG_ NodeStsODS2_LcFA : 39|1@0+ (1,0) [0|1] "" EOCM_HCP2,FCM_LC,HDLM,LRR,SRR_LF,SRR_LR_CR,SRR_RF,SRR_RR,SRR_SLR,SRR_SRR,UPM

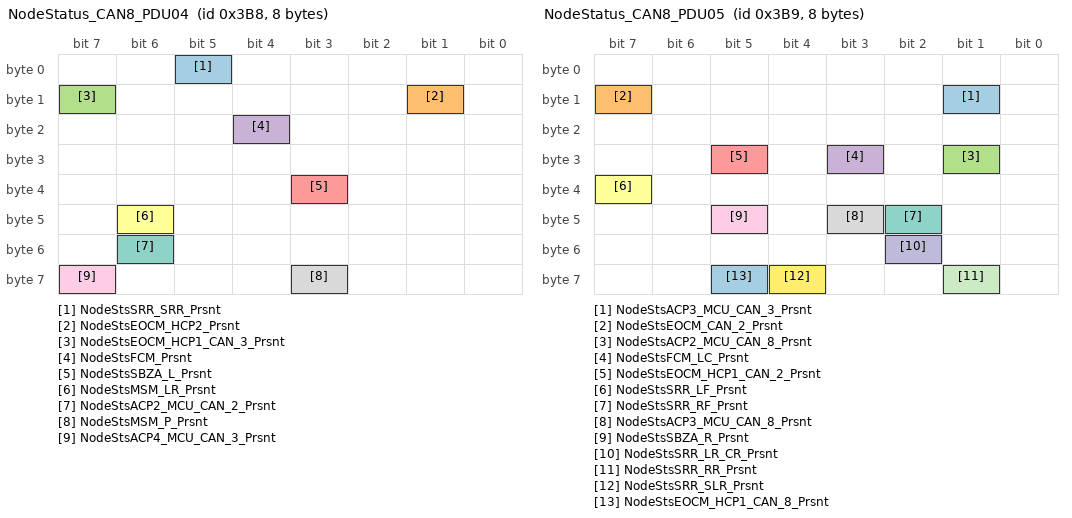
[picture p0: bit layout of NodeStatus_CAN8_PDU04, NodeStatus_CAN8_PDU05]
BO_ 952 NodeStatus_CAN8_PDU04: 8 CGM
 SG_ NodeStsSRR_SRR_Prsnt : 5|1@0+ (1,0) [0|1] "" SRR_LF,SRR_LR_CR,SRR_RF,SRR_RR,SRR_SLR
 SG_ NodeStsEOCM_HCP2_Prsnt : 9|1@0+ (1,0) [0|1] "" SRR_LF,SRR_LR_CR,SRR_RF,SRR_RR,SRR_SLR,SRR_SRR
 SG_ NodeStsEOCM_HCP1_CAN_3_Prsnt : 15|1@0+ (1,0) [0|1] "" SRR_LF,SRR_LR_CR,SRR_RF,SRR_RR,SRR_SLR,SRR_SRR
 SG_ NodeStsFCM_Prsnt : 20|1@0+ (1,0) [0|1] "" SRR_LF,SRR_LR_CR,SRR_RF,SRR_RR,SRR_SLR,SRR_SRR
 SG_ NodeStsSBZA_L_Prsnt : 35|1@0+ (1,0) [0|1] "" SRR_LF,SRR_LR_CR,SRR_RF,SRR_RR,SRR_SLR,SRR_SRR
 SG_ NodeStsMSM_LR_Prsnt : 46|1@0+ (1,0) [0|1] "" SRR_LF,SRR_LR_CR,SRR_RF,SRR_RR,SRR_SLR,SRR_SRR
 SG_ NodeStsACP2_MCU_CAN_2_Prsnt : 54|1@0+ (1,0) [0|1] "" SRR_LF,SRR_LR_CR,SRR_RF,SRR_RR,SRR_SLR,SRR_SRR
 SG_ NodeStsMSM_P_Prsnt : 59|1@0+ (1,0) [0|1] "" SRR_LF,SRR_LR_CR,SRR_RF,SRR_RR,SRR_SLR,SRR_SRR
 SG_ NodeStsACP4_MCU_CAN_3_Prsnt : 63|1@0+ (1,0) [0|1] "" SRR_LF,SRR_LR_CR,SRR_RF,SRR_RR,SRR_SLR,SRR_SRR

BO_ 953 NodeStatus_CAN8_PDU05: 8 CGM
 SG_ NodeStsACP3_MCU_CAN_3_Prsnt : 9|1@0+ (1,0) [0|1] "" SRR_LF,SRR_LR_CR,SRR_RF,SRR_RR,SRR_SLR,SRR_SRR
 SG_ NodeStsEOCM_CAN_2_Prsnt : 15|1@0+ (1,0) [0|1] "" SRR_LF,SRR_LR_CR,SRR_RF,SRR_RR,SRR_SLR,SRR_SRR
 SG_ NodeStsACP2_MCU_CAN_8_Prsnt : 25|1@0+ (1,0) [0|1] "" SRR_LF,SRR_LR_CR,SRR_RF,SRR_RR,SRR_SLR,SRR_SRR
 SG_ NodeStsFCM_LC_Prsnt : 27|1@0+ (1,0) [0|1] "" SRR_LF,SRR_LR_CR,SRR_RF,SRR_RR,SRR_SLR,SRR_SRR
 SG_ NodeStsEOCM_HCP1_CAN_2_Prsnt : 29|1@0+ (1,0) [0|1] "" SRR_LF,SRR_LR_CR,SRR_RF,SRR_RR,SRR_SLR,SRR_SRR
 SG_ NodeStsSRR_LF_Prsnt : 39|1@0+ (1,0) [0|1] "" SRR_LR_CR,SRR_RF,SRR_RR,SRR_SLR,SRR_SRR
 SG_ NodeStsSRR_RF_Prsnt : 42|1@0+ (1,0) [0|1] "" SRR_LF,SRR_LR_CR,SRR_RR,SRR_SLR,SRR_SRR
 SG_ NodeStsACP3_MCU_CAN_8_Prsnt : 43|1@0+ (1,0) [0|1] "" SRR_LF,SRR_LR_CR,SRR_RF,SRR_RR,SRR_SLR,SRR_SRR
 SG_ NodeStsSBZA_R_Prsnt : 45|1@0+ (1,0) [0|1] "" SRR_LF,SRR_LR_CR,SRR_RF,SRR_RR,SRR_SLR,SRR_SRR
 SG_ NodeStsSRR_LR_CR_Prsnt : 50|1@0+ (1,0) [0|1] "" SRR_LF,SRR_RF,SRR_RR,SRR_SLR,SRR_SRR
 SG_ NodeStsSRR_RR_Prsnt : 57|1@0+ (1,0) [0|1] "" SRR_LF,SRR_LR_CR,SRR_RF,SRR_SLR,SRR_SRR
 SG_ NodeStsSRR_SLR_Prsnt : 60|1@0+ (1,0) [0|1] "" SRR_LF,SRR_LR_CR,SRR_RF,SRR_RR,SRR_SRR
 SG_ NodeStsEOCM_HCP1_CAN_8_Prsnt : 61|1@0+ (1,0) [0|1] "" SRR_LF,SRR_LR_CR,SRR_RF,SRR_RR,SRR_SLR,SRR_SRR

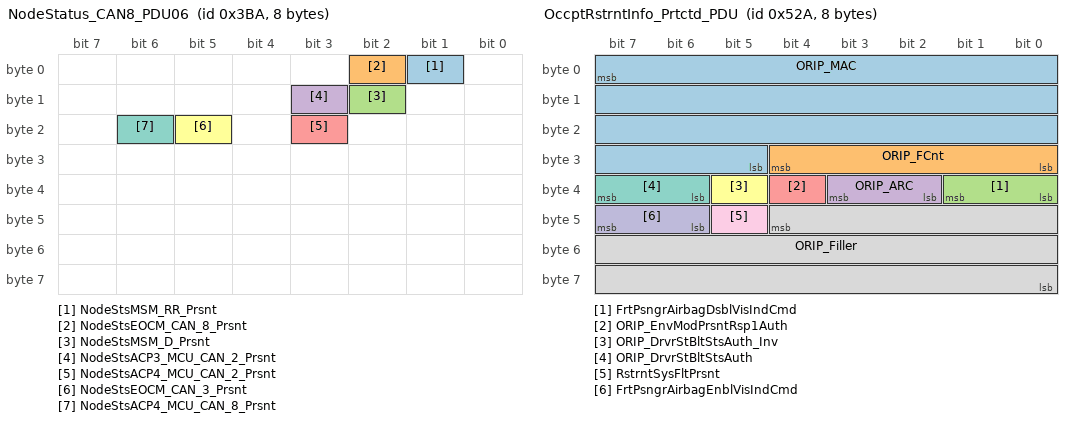
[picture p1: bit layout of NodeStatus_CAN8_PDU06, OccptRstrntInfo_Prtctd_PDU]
BO_ 954 NodeStatus_CAN8_PDU06: 8 CGM
 SG_ NodeStsMSM_RR_Prsnt : 1|1@0+ (1,0) [0|1] "" SRR_LF,SRR_LR_CR,SRR_RF,SRR_RR,SRR_SLR,SRR_SRR
 SG_ NodeStsEOCM_CAN_8_Prsnt : 2|1@0+ (1,0) [0|1] "" SRR_LF,SRR_LR_CR,SRR_RF,SRR_RR,SRR_SLR,SRR_SRR
 SG_ NodeStsMSM_D_Prsnt : 10|1@0+ (1,0) [0|1] "" SRR_LF,SRR_LR_CR,SRR_RF,SRR_RR,SRR_SLR,SRR_SRR
 SG_ NodeStsACP3_MCU_CAN_2_Prsnt : 11|1@0+ (1,0) [0|1] "" SRR_LF,SRR_LR_CR,SRR_RF,SRR_RR,SRR_SLR,SRR_SRR
 SG_ NodeStsACP4_MCU_CAN_2_Prsnt : 19|1@0+ (1,0) [0|1] "" SRR_LF,SRR_LR_CR,SRR_RF,SRR_RR,SRR_SLR,SRR_SRR
 SG_ NodeStsEOCM_CAN_3_Prsnt : 21|1@0+ (1,0) [0|1] "" SRR_LF,SRR_LR_CR,SRR_RF,SRR_RR,SRR_SLR,SRR_SRR
 SG_ NodeStsACP4_MCU_CAN_8_Prsnt : 22|1@0+ (1,0) [0|1] "" SRR_LF,SRR_LR_CR,SRR_RF,SRR_RR,SRR_SLR,SRR_SRR

BO_ 1382 OccptRstrntInfo_PCSM_PDU: 8 CGM
 SG_ OccptRstrntInfo_PCSM : 0|64@1+ (1,0) [0|1.84467e+019] "" ACP2_MCU

BO_ 1322 OccptRstrntInfo_Prtctd_PDU: 8 CGM
 SG_ ORIP_MAC : 7|27@0+ (1,0) [0|1.34218e+008] "" ACP2_MCU
 SG_ ORIP_FCnt : 28|5@0+ (1,0) [0|31] "" ACP2_MCU
 SG_ FrtPsngrAirbagDsblVisIndCmd : 33|2@0+ (1,0) [0|2] "" ACP2_MCU
 SG_ ORIP_ARC : 35|2@0+ (1,0) [0|3] "" ACP2_MCU
 SG_ ORIP_EnvModPrsntRsp1Auth : 36|1@0+ (1,0) [0|1] "" ACP2_MCU
 SG_ ORIP_DrvrStBltStsAuth_Inv : 37|1@0+ (1,0) [0|1] "" ACP2_MCU
 SG_ ORIP_DrvrStBltStsAuth : 39|2@0+ (1,0) [0|2] "" ACP2_MCU
 SG_ ORIP_Filler : 44|21@0+ (1,0) [0|2.09715e+006] "" ACP2_MCU
 SG_ RstrntSysFltPrsnt : 45|1@0+ (1,0) [0|1] "" ACP2_MCU,EOCM
 SG_ FrtPsngrAirbagEnblVisIndCmd : 47|2@0+ (1,0) [0|2] "" ACP2_MCU

BO_ 1381 PstClsnInfo_PCSM_PDU: 8 CGM
 SG_ PstClsnInfo_PCSM : 0|64@1+ (1,0) [0|1.84467e+019] "" ACP2_MCU

BO_ 1320 PstClsnInfo_Prtctd_PDU: 8 CGM
 SG_ PCIP_MAC : 7|27@0+ (1,0) [0|1.34218e+008] "" ACP2_MCU
 SG_ PCIP_FCnt : 28|5@0+ (1,0) [0|31] "" ACP2_MCU
 SG_ PCIP_HzrdLgtsOnReqdAuth : 32|1@0+ (1,0) [0|1] "" ACP2_MCU
 SG_ PCIP_HybVehHiVltgDsblReqdAuth : 33|1@0+ (1,0) [0|1] "" ACP2_MCU
 SG_ PCIP_HVCrshImpSnsSysDsbldAuth : 34|1@0+ (1,0) [0|1] "" ACP2_MCU
 SG_ PCIP_HVACBlwDsblReqdAuth : 35|1@0+ (1,0) [0|1] "" ACP2_MCU
 SG_ PCIP_FuelCutOffReqdAuth : 36|1@0+ (1,0) [0|1] "" ACP2_MCU
 SG_ PCIP_DrUnlckReqdAuth : 37|1@0+ (1,0) [0|1] "" ACP2_MCU
 SG_ PCIP_CruzCtlDsblReqdAuth : 38|1@0+ (1,0) [0|1] "" ACP2_MCU
 SG_ PCIP_BrkActReqdAuth : 39|1@0+ (1,0) [0|1] "" ACP2_MCU
 SG_ PCIP_NtfnEvntCntAuth : 44|8@0+ (1,0) [0|255] "" ACP2_MCU
 SG_ PCIP_NftnFrtImpPrtnsrSevAchAuth : 45|1@0+ (1,0) [0|1] "" ACP2_MCU
 SG_ PCIP_MemStRclDsblReqdAuth : 46|1@0+ (1,0) [0|1] "" ACP2_MCU
 SG_ PCIP_IntrLgtOnReqdAuth : 47|1@0+ (1,0) [0|1] "" ACP2_MCU
 SG_ PCIP_NtfnLtSdSevAchvdAuth : 48|1@0+ (1,0) [0|1] "" ACP2_MCU
 SG_ PCIP_NtfnFrtImpStg2SevAchvdAuth : 49|1@0+ (1,0) [0|1] "" ACP2_MCU
 SG_ PCIP_NtfnFrtImpStg1SevAchvdAuth : 50|1@0+ (1,0) [0|1] "" ACP2_MCU
 SG_ PCIP_NtfnEvntStsAuth : 52|2@0+ (1,0) [0|2] "" ACP2_MCU
 SG_ PCIP_Filler : 56|1@0+ (1,0) [0|1] "" ACP2_MCU
 SG_ PCIP_ARC : 58|2@0+ (1,0) [0|3] "" ACP2_MCU
 SG_ PCIP_eCallReqdAuth : 59|1@0+ (1,0) [0|1] "" ACP2_MCU
 SG_ PCIP_NtfnRtSdSevAchvdAuth : 60|1@0+ (1,0) [0|1] "" ACP2_MCU
 SG_ PCIP_NtfnRrImpSevAchvdAuth : 61|1@0+ (1,0) [0|1] "" ACP2_MCU
 SG_ PCIP_NtfnRlOvrSevAchvdAuth : 62|1@0+ (1,0) [0|1] "" ACP2_MCU
 SG_ PCIP_NtfnPedtrnPrtctnSevAchAuth : 63|1@0+ (1,0) [0|1] "" ACP2_MCU

BO_ 1426 SDS_Width_CAN8_PDU01: 6 SRR_LR_CR
 SG_ RtSdObjDtdAdjTrlr : 7|1@0+ (1,0) [0|1] "" SRR_SRR

BO_ 656 SRRLFODP_BrstGrp_PCSM_PDU: 8 SRR_LF
 SG_ SRRLFODP_BrstGrp1_PCSM : 0|64@1+ (1,0) [0|1.84467e+019] "" EOCM,EOCM_HCP2,EOCM_HC_Superset

BO_ 244 SRRLFODP_BrstGrp_Prtctd_Consecut: 64 SRR_LF
 SG_ SRRLFODPB2P_POTk3IDAuth : 0|7@0+ (1,0) [0|127] "" EOCM,EOCM_HCP2,EOCM_HC_Superset
 SG_ SRRLFODPB2P_POTk3DynPrpAuth : 3|3@0+ (1,0) [0|4] "" EOCM,EOCM_HCP2,EOCM_HC_Superset
 SG_ SRRLFODPB2P_POTk3CnfdStsAuth : 5|2@0+ (1,0) [0|3] "" EOCM,EOCM_HCP2,EOCM_HC_Superset
 SG_ SRRLFODPB2P_BrstID : 7|2@0+ (1,0) [0|3] "" EOCM,EOCM_HCP2,EOCM_HC_Superset
 SG_ SRRLFODPB2P_POTk3InPthPotAuth : 9|6@0+ (2,0) [0|126] "%" EOCM,EOCM_HCP2,EOCM_HC_Superset
 SG_ SRRLFODPB2P_POTk3PoILAAuth : 17|9@0- (0.125,0) [-32|31.875] "m/s^2" EOCM,EOCM_HCP2,EOCM_HC_Superset
 SG_ SRRLFODPB2P_POTk3MStsAuth : 19|2@0+ (1,0) [0|3] "" EOCM,EOCM_HCP2,EOCM_HC_Superset
 SG_ SRRLFODPB2P_POTk3PoILgAAuth : 24|9@0- (0.125,0) [-32|31.875] "m/s^2" EOCM,EOCM_HCP2,EOCM_HC_Superset
 SG_ SRRLFODPB2P_POTk3PoILgPsAuth : 47|11@0- (0.125,0) [-128|127.875] "m" EOCM,EOCM_HCP2,EOCM_HC_Superset
 SG_ SRRLFODPB2P_POTk3PoILgVAuth : 52|10@0- (0.125,0) [-64|63.875] "m/s" EOCM,EOCM_HCP2,EOCM_HC_Superset
 SG_ SRRLFODPB2P_POTk3PoILPsAuth : 58|10@0- (0.125,0) [-64|63.875] "m" EOCM,EOCM_HCP2,EOCM_HC_Superset
 SG_ SRRLFODPB2P_POTk3PoILVAuth : 64|9@0- (0.125,0) [-32|31.875] "m/s" EOCM,EOCM_HCP2,EOCM_HC_Superset
 SG_ SRRLFODPB2P_VOTk2CICOPotAuth : 83|6@0+ (2,0) [0|126] "%" EOCM,EOCM_HCP2,EOCM_HC_Superset
 SG_ SRRLFODPB2P_POTk3TypCnfdAuth : 85|2@0+ (1,0) [0|3] "" EOCM,EOCM_HCP2,EOCM_HC_Superset
 SG_ SRRLFODPB2P_POTk3TypAuth : 87|2@0+ (1,0) [0|2] "" EOCM,EOCM_HCP2,EOCM_HC_Superset
 SG_ SRRLFODPB2P_VOTk2DynPrpStsAuth : 88|1@0+ (1,0) [0|1] "" EOCM,EOCM_HCP2,EOCM_HC_Superset
 SG_ SRRLFODPB2P_VOTk2DynPrpAuth : 91|3@0+ (1,0) [0|4] "" EOCM,EOCM_HCP2,EOCM_HC_Superset
 SG_ SRRLFODPB2P_VOTk2CnfdStsAuth : 93|2@0+ (1,0) [0|3] "" EOCM,EOCM_HCP2,EOCM_HC_Superset
 SG_ SRRLFODPB2P_VOTk2MStsAuth : 96|2@0+ (1,0) [0|3] "" EOCM,EOCM_HCP2,EOCM_HC_Superset
 SG_ SRRLFODPB2P_VOTk2IDAuth : 103|7@0+ (1,0) [0|127] "" EOCM,EOCM_HCP2,EOCM_HC_Superset
 SG_ SRRLFODPB2P_VOTk2PoILAAuth : 110|9@0- (0.125,0) [-32|31.875] "m/s^2" EOCM,EOCM_HCP2,EOCM_HC_Superset
 SG_ SRRLFODPB2P_VOTk2PoILgAAuth : 117|9@0- (0.125,0) [-32|31.875] "m/s^2" EOCM,EOCM_HCP2,EOCM_HC_Superset
 SG_ SRRLFODPB2P_VOTk2PoILgPsAuth : 124|11@0- (0.125,0) [-128|127.875] "m" EOCM,EOCM_HCP2,EOCM_HC_Superset
 SG_ SRRLFODPB2P_VOTk2PoILgPsCAuth : 129|16@0+ (0.01,0) [0|655.35] "m^2" EOCM,EOCM_HCP2,EOCM_HC_Superset
 SG_ SRRLFODPB2P_VOTk2PoILgVAuth : 145|11@0- (0.125,0) [-128|127.875] "m/s" EOCM,EOCM_HCP2,EOCM_HC_Superset
 SG_ SRRLFODPB2P_VOTk2PoILgVCAuth : 166|10@0+ (0.125,0) [0|127.875] "(m/s)^2" EOCM,EOCM_HCP2,EOCM_HC_Superset
 SG_ SRRLFODPB2P_VOTk2PoILPsAuth : 172|10@0- (0.125,0) [-64|63.875] "m" EOCM,EOCM_HCP2,EOCM_HC_Superset
 SG_ SRRLFODPB2P_VOTk2PoILPsCAuth : 178|14@0+ (0.01,0) [0|163.83] "m^2" EOCM,EOCM_HCP2,EOCM_HC_Superset
 SG_ SRRLFODPB2P_VOTk2PoILVAuth : 196|9@0- (0.125,0) [-32|31.875] "m/s" EOCM,EOCM_HCP2,EOCM_HC_Superset
 SG_ SRRLFODPB2P_VOTk2PoILVCAuth : 203|10@0+ (0.125,0) [0|127.875] "(m/s)^2" EOCM,EOCM_HCP2,EOCM_HC_Superset
 SG_ SRRLFODPB2P_VOTk2TypCnfdAuth : 209|2@0+ (1,0) [0|3] "" EOCM,EOCM_HCP2,EOCM_HC_Superset
 SG_ SRRLFODPB2P_VOTk3CnfdStsAuth : 217|2@0+ (1,0) [0|3] "" EOCM,EOCM_HCP2,EOCM_HC_Superset
 SG_ SRRLFODPB2P_VOTk3CICOPotAuth : 223|6@0+ (2,0) [0|126] "%" EOCM,EOCM_HCP2,EOCM_HC_Superset
 SG_ SRRLFODPB2P_VOTk3IDAuth : 227|7@0+ (1,0) [0|127] "" EOCM,EOCM_HCP2,EOCM_HC_Superset
 SG_ SRRLFODPB2P_VOTk3DynPrpStsAuth : 228|1@0+ (1,0) [0|1] "" EOCM,EOCM_HCP2,EOCM_HC_Superset
 SG_ SRRLFODPB2P_VOTk3DynPrpAuth : 231|3@0+ (1,0) [0|4] "" EOCM,EOCM_HCP2,EOCM_HC_Superset
 SG_ SRRLFODPB2P_VOTk3PoILAAuth : 234|9@0- (0.125,0) [-32|31.875] "m/s^2" EOCM,EOCM_HCP2,EOCM_HC_Superset
 SG_ SRRLFODPB2P_VOTk3MStsAuth : 236|2@0+ (1,0) [0|3] "" EOCM,EOCM_HCP2,EOCM_HC_Superset
 SG_ SRRLFODPB2P_VOTk3PoILgAAuth : 241|9@0- (0.125,0) [-32|31.875] "m/s^2" EOCM,EOCM_HCP2,EOCM_HC_Superset
 SG_ SRRLFODPB2P_VOTk3PoILgPsAuth : 248|11@0- (0.125,0) [-128|127.875] "m" EOCM,EOCM_HCP2,EOCM_HC_Superset
 SG_ SRRLFODPB2P_VOTk3PoILgPsCAuth : 269|16@0+ (0.01,0) [0|655.35] "m^2" EOCM,EOCM_HCP2,EOCM_HC_Superset
 SG_ SRRLFODPB2P_VOTk3PoILgthAuth : 285|8@0+ (0.125,0) [0|31.875] "m" EOCM,EOCM_HCP2,EOCM_HC_Superset
 SG_ SRRLFODPB2P_VOTk3PoILgVAuth : 293|11@0- (0.125,0) [-128|127.875] "m/s" EOCM,EOCM_HCP2,EOCM_HC_Superset
 SG_ SRRLFODPB2P_VOTk3PoILgVCAuth : 298|10@0+ (0.125,0) [0|127.875] "(m/s)^2" EOCM,EOCM_HCP2,EOCM_HC_Superset
 SG_ SRRLFODPB2P_VOTk3PoILPsAuth : 304|10@0- (0.125,0) [-64|63.875] "m" EOCM,EOCM_HCP2,EOCM_HC_Superset
 SG_ SRRLFODPB2P_VOTk3PoILPsCAuth : 326|14@0+ (0.01,0) [0|163.83] "m^2" EOCM,EOCM_HCP2,EOCM_HC_Superset
 SG_ SRRLFODPB2P_VOTk3PoILVAuth : 328|9@0- (0.125,0) [-32|31.875] "m/s" EOCM,EOCM_HCP2,EOCM_HC_Superset
 SG_ SRRLFODPB2P_VOTk3PoILVCAuth : 351|10@0+ (0.125,0) [0|127.875] "(m/s)^2" EOCM,EOCM_HCP2,EOCM_HC_Superset
 SG_ SRRLFODPB2P_VOTk4CICOPotAuth : 355|6@0+ (2,0) [0|126] "%" EOCM,EOCM_HCP2,EOCM_HC_Superset
 SG_ SRRLFODPB2P_VOTk3TypCnfdAuth : 357|2@0+ (1,0) [0|3] "" EOCM,EOCM_HCP2,EOCM_HC_Superset
 SG_ SRRLFODPB2P_VOTk4DynPrpStsAuth : 360|1@0+ (1,0) [0|1] "" EOCM,EOCM_HCP2,EOCM_HC_Superset
 SG_ SRRLFODPB2P_VOTk4DynPrpAuth : 363|3@0+ (1,0) [0|4] "" EOCM,EOCM_HCP2,EOCM_HC_Superset
 SG_ SRRLFODPB2P_VOTk4CnfdStsAuth : 365|2@0+ (1,0) [0|3] "" EOCM,EOCM_HCP2,EOCM_HC_Superset
 SG_ SRRLFODPB2P_VOTk4MStsAuth : 368|2@0+ (1,0) [0|3] "" EOCM,EOCM_HCP2,EOCM_HC_Superset
 SG_ SRRLFODPB2P_VOTk4IDAuth : 375|7@0+ (1,0) [0|127] "" EOCM,EOCM_HCP2,EOCM_HC_Superset
 SG_ SRRLFODPB2P_VOTk4PoILAAuth : 382|9@0- (0.125,0) [-32|31.875] "m/s^2" EOCM,EOCM_HCP2,EOCM_HC_Superset
 SG_ SRRLFODPB2P_VOTk4PoILgAAuth : 389|9@0- (0.125,0) [-32|31.875] "m/s^2" EOCM,EOCM_HCP2,EOCM_HC_Superset
 SG_ SRRLFODPB2P_VOTk4PoILgPsAuth : 396|11@0- (0.125,0) [-128|127.875] "m" EOCM,EOCM_HCP2,EOCM_HC_Superset
 SG_ SRRLFODPB2P_VOTk4PoILgPsCAuth : 401|16@0+ (0.01,0) [0|655.35] "m^2" EOCM,EOCM_HCP2,EOCM_HC_Superset
 SG_ SRRLFODPB2P_VOTk4PoILgthAuth : 417|8@0+ (0.125,0) [0|31.875] "m" EOCM,EOCM_HCP2,EOCM_HC_Superset
 SG_ SRRLFODPB2P_VOTk4PoILgVAuth : 425|11@0- (0.125,0) [-128|127.875] "m/s" EOCM,EOCM_HCP2,EOCM_HC_Superset
 SG_ SRRLFODPB2P_VOTk4PoILgVCAuth : 446|10@0+ (0.125,0) [0|127.875] "(m/s)^2" EOCM,EOCM_HCP2,EOCM_HC_Superset
 SG_ SRRLFODPB2P_VOTk4PoILPsAuth : 452|10@0- (0.125,0) [-64|63.875] "m" EOCM,EOCM_HCP2,EOCM_HC_Superset
 SG_ SRRLFODPB2P_VOTk4PoILPsCAuth : 458|14@0+ (0.01,0) [0|163.83] "m^2" EOCM,EOCM_HCP2,EOCM_HC_Superset
 SG_ SRRLFODPB2P_VOTk4PoILVAuth : 476|9@0- (0.125,0) [-32|31.875] "m/s" EOCM,EOCM_HCP2,EOCM_HC_Superset
 SG_ SRRLFODPB2P_VOTk4PoILVCAuth : 483|10@0+ (0.125,0) [0|127.875] "(m/s)^2" EOCM,EOCM_HCP2,EOCM_HC_Superset
 SG_ SRRLFODPB2P_VOTk4TypCnfdAuth : 489|2@0+ (1,0) [0|3] "" EOCM,EOCM_HCP2,EOCM_HC_Superset
 SG_ SRRLFODPB2P_VOTk5LgthdthAuth : 503|8@0+ (0.125,0) [0|31.875] "m" EOCM,EOCM_HCP2,EOCM_HC_Superset
 SG_ SRRLFODPB2P_Filler : 511|8@0+ (1,0) [0|255] "" EOCM,EOCM_HCP2,EOCM_HC_Superset

BO_ 211 SRRLFODP_BrstGrp_Prtctd_Consec01: 64 SRR_LF
 SG_ SRRLFODPB3P_POTk4IDAuth : 0|7@0+ (1,0) [0|127] "" EOCM,EOCM_HCP2,EOCM_HC_Superset
 SG_ SRRLFODPB3P_POTk4DynPrpAuth : 3|3@0+ (1,0) [0|4] "" EOCM,EOCM_HCP2,EOCM_HC_Superset
 SG_ SRRLFODPB3P_POTk4CnfdStsAuth : 5|2@0+ (1,0) [0|3] "" EOCM,EOCM_HCP2,EOCM_HC_Superset
 SG_ SRRLFODPB3P_BrstID : 7|2@0+ (1,0) [0|3] "" EOCM,EOCM_HCP2,EOCM_HC_Superset
 SG_ SRRLFODPB3P_POTk4InPthPotAuth : 9|6@0+ (2,0) [0|126] "%" EOCM,EOCM_HCP2,EOCM_HC_Superset
 SG_ SRRLFODPB3P_POTk4PoILAAuth : 17|9@0- (0.125,0) [-32|31.875] "m/s^2" EOCM,EOCM_HCP2,EOCM_HC_Superset
 SG_ SRRLFODPB3P_POTk4MStsAuth : 19|2@0+ (1,0) [0|3] "" EOCM,EOCM_HCP2,EOCM_HC_Superset
 SG_ SRRLFODPB3P_POTk4PoILgAAuth : 24|9@0- (0.125,0) [-32|31.875] "m/s^2" EOCM,EOCM_HCP2,EOCM_HC_Superset
 SG_ SRRLFODPB3P_POTk4PoILgPsAuth : 47|11@0- (0.125,0) [-128|127.875] "m" EOCM,EOCM_HCP2,EOCM_HC_Superset
 SG_ SRRLFODPB3P_POTk4PoILgVAuth : 52|10@0- (0.125,0) [-64|63.875] "m/s" EOCM,EOCM_HCP2,EOCM_HC_Superset
 SG_ SRRLFODPB3P_POTk4PoILPsAuth : 58|10@0- (0.125,0) [-64|63.875] "m" EOCM,EOCM_HCP2,EOCM_HC_Superset
 SG_ SRRLFODPB3P_POTk4PoILVAuth : 64|9@0- (0.125,0) [-32|31.875] "m/s" EOCM,EOCM_HCP2,EOCM_HC_Superset
 SG_ SRRLFODPB3P_VOTk5CICOPotAuth : 83|6@0+ (2,0) [0|126] "%" EOCM,EOCM_HCP2,EOCM_HC_Superset
 SG_ SRRLFODPB3P_POTk4TypCnfdAuth : 85|2@0+ (1,0) [0|3] "" EOCM,EOCM_HCP2,EOCM_HC_Superset
 SG_ SRRLFODPB3P_POTk4TypAuth : 87|2@0+ (1,0) [0|2] "" EOCM,EOCM_HCP2,EOCM_HC_Superset
 SG_ SRRLFODPB3P_VOTk5DynPrpStsAuth : 88|1@0+ (1,0) [0|1] "" EOCM,EOCM_HCP2,EOCM_HC_Superset
 SG_ SRRLFODPB3P_VOTk5DynPrpAuth : 91|3@0+ (1,0) [0|4] "" EOCM,EOCM_HCP2,EOCM_HC_Superset
 SG_ SRRLFODPB3P_VOTk5CnfdStsAuth : 93|2@0+ (1,0) [0|3] "" EOCM,EOCM_HCP2,EOCM_HC_Superset
 SG_ SRRLFODPB3P_VOTk5MStsAuth : 96|2@0+ (1,0) [0|3] "" EOCM,EOCM_HCP2,EOCM_HC_Superset
 SG_ SRRLFODPB3P_VOTk5IDAuth : 103|7@0+ (1,0) [0|127] "" EOCM,EOCM_HCP2,EOCM_HC_Superset
 SG_ SRRLFODPB3P_VOTk5PoILAAuth : 110|9@0- (0.125,0) [-32|31.875] "m/s^2" EOCM,EOCM_HCP2,EOCM_HC_Superset
 SG_ SRRLFODPB3P_VOTk5PoILgAAuth : 117|9@0- (0.125,0) [-32|31.875] "m/s^2" EOCM,EOCM_HCP2,EOCM_HC_Superset
 SG_ SRRLFODPB3P_VOTk5PoILgPsAuth : 124|11@0- (0.125,0) [-128|127.875] "m" EOCM,EOCM_HCP2,EOCM_HC_Superset
 SG_ SRRLFODPB3P_VOTk5PoILgPsCAuth : 129|16@0+ (0.01,0) [0|655.35] "m^2" EOCM,EOCM_HCP2,EOCM_HC_Superset
 SG_ SRRLFODPB3P_VOTk5PoILgVAuth : 145|11@0- (0.125,0) [-128|127.875] "m/s" EOCM,EOCM_HCP2,EOCM_HC_Superset
 SG_ SRRLFODPB3P_VOTk5PoILgVCAuth : 166|10@0+ (0.125,0) [0|127.875] "(m/s)^2" EOCM,EOCM_HCP2,EOCM_HC_Superset
 SG_ SRRLFODPB3P_VOTk5PoILPsAuth : 172|10@0- (0.125,0) [-64|63.875] "m" EOCM,EOCM_HCP2,EOCM_HC_Superset
 SG_ SRRLFODPB3P_VOTk5PoILPsCAuth : 178|14@0+ (0.01,0) [0|163.83] "m^2" EOCM,EOCM_HCP2,EOCM_HC_Superset
 SG_ SRRLFODPB3P_VOTk5PoILVAuth : 196|9@0- (0.125,0) [-32|31.875] "m/s" EOCM,EOCM_HCP2,EOCM_HC_Superset
 SG_ SRRLFODPB3P_VOTk5PoILVCAuth : 203|10@0+ (0.125,0) [0|127.875] "(m/s)^2" EOCM,EOCM_HCP2,EOCM_HC_Superset
 SG_ SRRLFODPB3P_VOTk5TypCnfdAuth : 209|2@0+ (1,0) [0|3] "" EOCM,EOCM_HCP2,EOCM_HC_Superset
 SG_ SRRLFODPB3P_VOTk6CnfdStsAuth : 217|2@0+ (1,0) [0|3] "" EOCM,EOCM_HCP2,EOCM_HC_Superset
 SG_ SRRLFODPB3P_VOTk6CICOPotAuth : 223|6@0+ (2,0) [0|126] "%" EOCM,EOCM_HCP2,EOCM_HC_Superset
 SG_ SRRLFODPB3P_VOTk6IDAuth : 227|7@0+ (1,0) [0|127] "" EOCM,EOCM_HCP2,EOCM_HC_Superset
 SG_ SRRLFODPB3P_VOTk6DynPrpStsAuth : 228|1@0+ (1,0) [0|1] "" EOCM,EOCM_HCP2,EOCM_HC_Superset
 SG_ SRRLFODPB3P_VOTk6DynPrpAuth : 231|3@0+ (1,0) [0|4] "" EOCM,EOCM_HCP2,EOCM_HC_Superset
 SG_ SRRLFODPB3P_VOTk6PoILAAuth : 234|9@0- (0.125,0) [-32|31.875] "m/s^2" EOCM,EOCM_HCP2,EOCM_HC_Superset
 SG_ SRRLFODPB3P_VOTk6MStsAuth : 236|2@0+ (1,0) [0|3] "" EOCM,EOCM_HCP2,EOCM_HC_Superset
 SG_ SRRLFODPB3P_VOTk6PoILgAAuth : 241|9@0- (0.125,0) [-32|31.875] "m/s^2" EOCM,EOCM_HCP2,EOCM_HC_Superset
 SG_ SRRLFODPB3P_VOTk6PoILgPsAuth : 248|11@0- (0.125,0) [-128|127.875] "m" EOCM,EOCM_HCP2,EOCM_HC_Superset
 SG_ SRRLFODPB3P_VOTk6PoILgPsCAuth : 269|16@0+ (0.01,0) [0|655.35] "m^2" EOCM,EOCM_HCP2,EOCM_HC_Superset
 SG_ SRRLFODPB3P_VOTk6PoILgthAuth : 285|8@0+ (0.125,0) [0|31.875] "m" EOCM,EOCM_HCP2,EOCM_HC_Superset
 SG_ SRRLFODPB3P_VOTk6PoILgVAuth : 293|11@0- (0.125,0) [-128|127.875] "m/s" EOCM,EOCM_HCP2,EOCM_HC_Superset
 SG_ SRRLFODPB3P_VOTk6PoILgVCAuth : 298|10@0+ (0.125,0) [0|127.875] "(m/s)^2" EOCM,EOCM_HCP2,EOCM_HC_Superset
 SG_ SRRLFODPB3P_VOTk6PoILPsAuth : 304|10@0- (0.125,0) [-64|63.875] "m" EOCM,EOCM_HCP2,EOCM_HC_Superset
 SG_ SRRLFODPB3P_VOTk6PoILPsCAuth : 326|14@0+ (0.01,0) [0|163.83] "m^2" EOCM,EOCM_HCP2,EOCM_HC_Superset
 SG_ SRRLFODPB3P_VOTk6PoILVAuth : 328|9@0- (0.125,0) [-32|31.875] "m/s" EOCM,EOCM_HCP2,EOCM_HC_Superset
 SG_ SRRLFODPB3P_VOTk6PoILVCAuth : 351|10@0+ (0.125,0) [0|127.875] "(m/s)^2" EOCM,EOCM_HCP2,EOCM_HC_Superset
 SG_ SRRLFODPB3P_VOTk7CICOPotAuth : 355|6@0+ (2,0) [0|126] "%" EOCM,EOCM_HCP2,EOCM_HC_Superset
 SG_ SRRLFODPB3P_VOTk6TypCnfdAuth : 357|2@0+ (1,0) [0|3] "" EOCM,EOCM_HCP2,EOCM_HC_Superset
 SG_ SRRLFODPB3P_VOTk7DynPrpStsAuth : 360|1@0+ (1,0) [0|1] "" EOCM,EOCM_HCP2,EOCM_HC_Superset
 SG_ SRRLFODPB3P_VOTk7DynPrpAuth : 363|3@0+ (1,0) [0|4] "" EOCM,EOCM_HCP2,EOCM_HC_Superset
 SG_ SRRLFODPB3P_VOTk7CnfdStsAuth : 365|2@0+ (1,0) [0|3] "" EOCM,EOCM_HCP2,EOCM_HC_Superset
 SG_ SRRLFODPB3P_VOTk7MStsAuth : 368|2@0+ (1,0) [0|3] "" EOCM,EOCM_HCP2,EOCM_HC_Superset
 SG_ SRRLFODPB3P_VOTk7IDAuth : 375|7@0+ (1,0) [0|127] "" EOCM,EOCM_HCP2,EOCM_HC_Superset
 SG_ SRRLFODPB3P_VOTk7PoILAAuth : 382|9@0- (0.125,0) [-32|31.875] "m/s^2" EOCM,EOCM_HCP2,EOCM_HC_Superset
 SG_ SRRLFODPB3P_VOTk7PoILgAAuth : 389|9@0- (0.125,0) [-32|31.875] "m/s^2" EOCM,EOCM_HCP2,EOCM_HC_Superset
 SG_ SRRLFODPB3P_VOTk7PoILgPsAuth : 396|11@0- (0.125,0) [-128|127.875] "m" EOCM,EOCM_HCP2,EOCM_HC_Superset
 SG_ SRRLFODPB3P_VOTk7PoILgPsCAuth : 401|16@0+ (0.01,0) [0|655.35] "m^2" EOCM,EOCM_HCP2,EOCM_HC_Superset
 SG_ SRRLFODPB3P_VOTk7PoILgthAuth : 417|8@0+ (0.125,0) [0|31.875] "m" EOCM,EOCM_HCP2,EOCM_HC_Superset
 SG_ SRRLFODPB3P_VOTk7PoILgVAuth : 425|11@0- (0.125,0) [-128|127.875] "m/s" EOCM,EOCM_HCP2,EOCM_HC_Superset
 SG_ SRRLFODPB3P_VOTk7PoILgVCAuth : 446|10@0+ (0.125,0) [0|127.875] "(m/s)^2" EOCM,EOCM_HCP2,EOCM_HC_Superset
 SG_ SRRLFODPB3P_VOTk7PoILPsAuth : 452|10@0- (0.125,0) [-64|63.875] "m" EOCM,EOCM_HCP2,EOCM_HC_Superset
 SG_ SRRLFODPB3P_VOTk7PoILPsCAuth : 458|14@0+ (0.01,0) [0|163.83] "m^2" EOCM,EOCM_HCP2,EOCM_HC_Superset
 SG_ SRRLFODPB3P_VOTk7PoILVAuth : 476|9@0- (0.125,0) [-32|31.875] "m/s" EOCM,EOCM_HCP2,EOCM_HC_Superset
 SG_ SRRLFODPB3P_VOTk7PoILVCAuth : 483|10@0+ (0.125,0) [0|127.875] "(m/s)^2" EOCM,EOCM_HCP2,EOCM_HC_Superset
 SG_ SRRLFODPB3P_VOTk7TypCnfdAuth : 489|2@0+ (1,0) [0|3] "" EOCM,EOCM_HCP2,EOCM_HC_Superset
 SG_ SRRLFODPB3P_VOTk8PoILgthAuth : 503|8@0+ (0.125,0) [0|31.875] "m" EOCM,EOCM_HCP2,EOCM_HC_Superset
 SG_ SRRLFODPB3P_Filler : 511|8@0+ (1,0) [0|255] "" EOCM,EOCM_HCP2,EOCM_HC_Superset

BO_ 245 SRRLFODP_BrstGrp_Prtctd_Consec02: 64 SRR_LF
 SG_ SRRLFODPB4P_POTk5IDAuth : 0|7@0+ (1,0) [0|127] "" EOCM,EOCM_HCP2,EOCM_HC_Superset
 SG_ SRRLFODPB4P_POTk5DynPrpAuth : 3|3@0+ (1,0) [0|4] "" EOCM,EOCM_HCP2,EOCM_HC_Superset
 SG_ SRRLFODPB4P_POTk5CnfdStsAuth : 5|2@0+ (1,0) [0|3] "" EOCM,EOCM_HCP2,EOCM_HC_Superset
 SG_ SRRLFODPB4P_BrstID : 7|2@0+ (1,0) [0|3] "" EOCM,EOCM_HCP2,EOCM_HC_Superset
 SG_ SRRLFODPB4P_POTk5InPthPotAuth : 9|6@0+ (2,0) [0|126] "%" EOCM,EOCM_HCP2,EOCM_HC_Superset
 SG_ SRRLFODPB4P_POTk5PoILAAuth : 17|9@0- (0.125,0) [-32|31.875] "m/s^2" EOCM,EOCM_HCP2,EOCM_HC_Superset
 SG_ SRRLFODPB4P_POTk5MStsAuth : 19|2@0+ (1,0) [0|3] "" EOCM,EOCM_HCP2,EOCM_HC_Superset
 SG_ SRRLFODPB4P_POTk5PoILgAAuth : 24|9@0- (0.125,0) [-32|31.875] "m/s^2" EOCM,EOCM_HCP2,EOCM_HC_Superset
 SG_ SRRLFODPB4P_POTk5PoILgPsAuth : 47|11@0- (0.125,0) [-128|127.875] "m" EOCM,EOCM_HCP2,EOCM_HC_Superset
 SG_ SRRLFODPB4P_POTk5PoILgVAuth : 52|10@0- (0.125,0) [-64|63.875] "m/s" EOCM,EOCM_HCP2,EOCM_HC_Superset
 SG_ SRRLFODPB4P_POTk5PoILPsAuth : 58|10@0- (0.125,0) [-64|63.875] "m" EOCM,EOCM_HCP2,EOCM_HC_Superset
 SG_ SRRLFODPB4P_POTk5PoILVAuth : 64|9@0- (0.125,0) [-32|31.875] "m/s" EOCM,EOCM_HCP2,EOCM_HC_Superset
 SG_ SRRLFODPB4P_VOTk10CICOPotAuth : 83|6@0+ (2,0) [0|126] "%" EOCM,EOCM_HCP2,EOCM_HC_Superset
 SG_ SRRLFODPB4P_POTk5TypCnfdAuth : 85|2@0+ (1,0) [0|3] "" EOCM,EOCM_HCP2,EOCM_HC_Superset
 SG_ SRRLFODPB4P_POTk5TypAuth : 87|2@0+ (1,0) [0|2] "" EOCM,EOCM_HCP2,EOCM_HC_Superset
 SG_ SRRLFODPB4P_VOTk10DynPrpStsAuth : 88|1@0+ (1,0) [0|1] "" EOCM,EOCM_HCP2,EOCM_HC_Superset
 SG_ SRRLFODPB4P_VOTk10DynPrpAuth : 91|3@0+ (1,0) [0|4] "" EOCM,EOCM_HCP2,EOCM_HC_Superset
 SG_ SRRLFODPB4P_VOTk10CnfdStsAuth : 93|2@0+ (1,0) [0|3] "" EOCM,EOCM_HCP2,EOCM_HC_Superset
 SG_ SRRLFODPB4P_VOTk10MStsAuth : 96|2@0+ (1,0) [0|3] "" EOCM,EOCM_HCP2,EOCM_HC_Superset
 SG_ SRRLFODPB4P_VOTk10IDAuth : 103|7@0+ (1,0) [0|127] "" EOCM,EOCM_HCP2,EOCM_HC_Superset
 SG_ SRRLFODPB4P_VOTk10PoILAAuth : 110|9@0- (0.125,0) [-32|31.875] "m/s^2" EOCM,EOCM_HCP2,EOCM_HC_Superset
 SG_ SRRLFODPB4P_VOTk10PoILgAAuth : 117|9@0- (0.125,0) [-32|31.875] "m/s^2" EOCM,EOCM_HCP2,EOCM_HC_Superset
 SG_ SRRLFODPB4P_VOTk10PoILgPsAuth : 124|11@0- (0.125,0) [-128|127.875] "m" EOCM,EOCM_HCP2,EOCM_HC_Superset
 SG_ SRRLFODPB4P_VOTk10PoILgPsCAuth : 129|16@0+ (0.01,0) [0|655.35] "m^2" EOCM,EOCM_HCP2,EOCM_HC_Superset
 SG_ SRRLFODPB4P_VOTk10PoILgthAuth : 145|8@0+ (0.125,0) [0|31.875] "m" EOCM,EOCM_HCP2,EOCM_HC_Superset
 SG_ SRRLFODPB4P_VOTk10PoILgVAuth : 153|11@0- (0.125,0) [-128|127.875] "m/s" EOCM,EOCM_HCP2,EOCM_HC_Superset
 SG_ SRRLFODPB4P_VOTk10PoILgVCAuth : 174|10@0+ (0.125,0) [0|127.875] "(m/s)^2" EOCM,EOCM_HCP2,EOCM_HC_Superset
 SG_ SRRLFODPB4P_VOTk10PoILPsAuth : 180|10@0- (0.125,0) [-64|63.875] "m" EOCM,EOCM_HCP2,EOCM_HC_Superset
 SG_ SRRLFODPB4P_VOTk10PoILPsCAuth : 186|14@0+ (0.01,0) [0|163.83] "m^2" EOCM,EOCM_HCP2,EOCM_HC_Superset
 SG_ SRRLFODPB4P_VOTk10PoILVAuth : 204|9@0- (0.125,0) [-32|31.875] "m/s" EOCM,EOCM_HCP2,EOCM_HC_Superset
 SG_ SRRLFODPB4P_VOTk10PoILVCAuth : 211|10@0+ (0.125,0) [0|127.875] "(m/s)^2" EOCM,EOCM_HCP2,EOCM_HC_Superset
 SG_ SRRLFODPB4P_VOTk10TypCnfdAuth : 217|2@0+ (1,0) [0|3] "" EOCM,EOCM_HCP2,EOCM_HC_Superset
 SG_ SRRLFODPB4P_VOTk8CnfdStsAuth : 225|2@0+ (1,0) [0|3] "" EOCM,EOCM_HCP2,EOCM_HC_Superset
 SG_ SRRLFODPB4P_VOTk8CICOPotAuth : 231|6@0+ (2,0) [0|126] "%" EOCM,EOCM_HCP2,EOCM_HC_Superset
 SG_ SRRLFODPB4P_VOTk8IDAuth : 235|7@0+ (1,0) [0|127] "" EOCM,EOCM_HCP2,EOCM_HC_Superset
 SG_ SRRLFODPB4P_VOTk8DynPrpStsAuth : 236|1@0+ (1,0) [0|1] "" EOCM,EOCM_HCP2,EOCM_HC_Superset
 SG_ SRRLFODPB4P_VOTk8DynPrpAuth : 239|3@0+ (1,0) [0|4] "" EOCM,EOCM_HCP2,EOCM_HC_Superset
 SG_ SRRLFODPB4P_VOTk8PoILAAuth : 242|9@0- (0.125,0) [-32|31.875] "m/s^2" EOCM,EOCM_HCP2,EOCM_HC_Superset
 SG_ SRRLFODPB4P_VOTk8MStsAuth : 244|2@0+ (1,0) [0|3] "" EOCM,EOCM_HCP2,EOCM_HC_Superset
 SG_ SRRLFODPB4P_VOTk8PoILgAAuth : 249|9@0- (0.125,0) [-32|31.875] "m/s^2" EOCM,EOCM_HCP2,EOCM_HC_Superset
 SG_ SRRLFODPB4P_VOTk8PoILgPsAuth : 256|11@0- (0.125,0) [-128|127.875] "m" EOCM,EOCM_HCP2,EOCM_HC_Superset
 SG_ SRRLFODPB4P_VOTk8PoILgPsCAuth : 277|16@0+ (0.01,0) [0|655.35] "m^2" EOCM,EOCM_HCP2,EOCM_HC_Superset
 SG_ SRRLFODPB4P_VOTk8PoILgVAuth : 293|11@0- (0.125,0) [-128|127.875] "m/s" EOCM,EOCM_HCP2,EOCM_HC_Superset
 SG_ SRRLFODPB4P_VOTk8PoILgVCAuth : 298|10@0+ (0.125,0) [0|127.875] "(m/s)^2" EOCM,EOCM_HCP2,EOCM_HC_Superset
 SG_ SRRLFODPB4P_VOTk8PoILPsAuth : 304|10@0- (0.125,0) [-64|63.875] "m" EOCM,EOCM_HCP2,EOCM_HC_Superset
 SG_ SRRLFODPB4P_VOTk8PoILPsCAuth : 326|14@0+ (0.01,0) [0|163.83] "m^2" EOCM,EOCM_HCP2,EOCM_HC_Superset
 SG_ SRRLFODPB4P_VOTk8PoILVAuth : 328|9@0- (0.125,0) [-32|31.875] "m/s" EOCM,EOCM_HCP2,EOCM_HC_Superset
 SG_ SRRLFODPB4P_VOTk8PoILVCAuth : 351|10@0+ (0.125,0) [0|127.875] "(m/s)^2" EOCM,EOCM_HCP2,EOCM_HC_Superset
 SG_ SRRLFODPB4P_VOTk9CICOPotAuth : 355|6@0+ (2,0) [0|126] "%" EOCM,EOCM_HCP2,EOCM_HC_Superset
 SG_ SRRLFODPB4P_VOTk8TypCnfdAuth : 357|2@0+ (1,0) [0|3] "" EOCM,EOCM_HCP2,EOCM_HC_Superset
 SG_ SRRLFODPB4P_VOTk9DynPrpStsAuth : 360|1@0+ (1,0) [0|1] "" EOCM,EOCM_HCP2,EOCM_HC_Superset
 SG_ SRRLFODPB4P_VOTk9DynPrpAuth : 363|3@0+ (1,0) [0|4] "" EOCM,EOCM_HCP2,EOCM_HC_Superset
 SG_ SRRLFODPB4P_VOTk9CnfdStsAuth : 365|2@0+ (1,0) [0|3] "" EOCM,EOCM_HCP2,EOCM_HC_Superset
 SG_ SRRLFODPB4P_VOTk9MStsAuth : 368|2@0+ (1,0) [0|3] "" EOCM,EOCM_HCP2,EOCM_HC_Superset
 SG_ SRRLFODPB4P_VOTk9IDAuth : 375|7@0+ (1,0) [0|127] "" EOCM,EOCM_HCP2,EOCM_HC_Superset
 SG_ SRRLFODPB4P_VOTk9PoILAAuth : 382|9@0- (0.125,0) [-32|31.875] "m/s^2" EOCM,EOCM_HCP2,EOCM_HC_Superset
 SG_ SRRLFODPB4P_VOTk9PoILgAAuth : 389|9@0- (0.125,0) [-32|31.875] "m/s^2" EOCM,EOCM_HCP2,EOCM_HC_Superset
 SG_ SRRLFODPB4P_VOTk9PoILgPsAuth : 396|11@0- (0.125,0) [-128|127.875] "m" EOCM,EOCM_HCP2,EOCM_HC_Superset
 SG_ SRRLFODPB4P_VOTk9PoILgPsCAuth : 401|16@0+ (0.01,0) [0|655.35] "m^2" EOCM,EOCM_HCP2,EOCM_HC_Superset
 SG_ SRRLFODPB4P_VOTk9PoILgthAuth : 417|8@0+ (0.125,0) [0|31.875] "m" EOCM,EOCM_HCP2,EOCM_HC_Superset
 SG_ SRRLFODPB4P_VOTk9PoILgVAuth : 425|11@0- (0.125,0) [-128|127.875] "m/s" EOCM,EOCM_HCP2,EOCM_HC_Superset
 SG_ SRRLFODPB4P_VOTk9PoILgVCAuth : 446|10@0+ (0.125,0) [0|127.875] "(m/s)^2" EOCM,EOCM_HCP2,EOCM_HC_Superset
 SG_ SRRLFODPB4P_VOTk9PoILPsAuth : 452|10@0- (0.125,0) [-64|63.875] "m" EOCM,EOCM_HCP2,EOCM_HC_Superset
 SG_ SRRLFODPB4P_VOTk9PoILPsCAuth : 458|14@0+ (0.01,0) [0|163.83] "m^2" EOCM,EOCM_HCP2,EOCM_HC_Superset
 SG_ SRRLFODPB4P_VOTk9PoILVAuth : 476|9@0- (0.125,0) [-32|31.875] "m/s" EOCM,EOCM_HCP2,EOCM_HC_Superset
 SG_ SRRLFODPB4P_VOTk9PoILVCAuth : 483|10@0+ (0.125,0) [0|127.875] "(m/s)^2" EOCM,EOCM_HCP2,EOCM_HC_Superset
 SG_ SRRLFODPB4P_VOTk9TypCnfdAuth : 489|2@0+ (1,0) [0|3] "" EOCM,EOCM_HCP2,EOCM_HC_Superset
 SG_ SRRLFODPB4P_Filler : 503|16@0+ (1,0) [0|65535] "" EOCM,EOCM_HCP2,EOCM_HC_Superset

BA_DEF_ SG_  "SignalType" STRING ;
BA_DEF_ SG_  "SignalLongName" STRING ;
BA_DEF_ BO_  "GenMsgCycleTime" INT 0 10000;
BA_DEF_ BO_  "GenMsgSendType" ENUM "cyclicX","spontanX","cyclicIfActiveX","spontanWithDelay","cyclicAndSpontanX","cyclicAndSpontanWithDelay","spontanWithRepetition","cyclicIfActiveAndSpontanWD";
BA_DEF_ BO_  "VFrameFormat" ENUM  "StandardCAN","ExtendedCAN","reserved","reserved","reserved","reserved","reserved","reserved","reserved","reserved","reserved","reserved","reserved","reserved","StandardCAN_FD","ExtendedCAN_FD";
BA_DEF_DEF_  "SignalType" "";
BA_DEF_DEF_  "SignalLongName" "";
BA_DEF_DEF_  "GenMsgCycleTime" 0;
BA_DEF_DEF_  "GenMsgSendType" "cyclicX";
BA_DEF_DEF_  "VFrameFormat" "StandardCAN";
BA_ "VFrameFormat" BO_ 69 14;
BA_ "GenMsgCycleTime" BO_ 225 40;
BA_ "VFrameFormat" BO_ 225 14;
BA_ "GenMsgCycleTime" BO_ 1444 1000;
BA_ "VFrameFormat" BO_ 1444 14;
BA_ "GenMsgCycleTime" BO_ 963 1000;
BA_ "VFrameFormat" BO_ 963 14;
BA_ "GenMsgCycleTime" BO_ 964 1000;
BA_ "VFrameFormat" BO_ 964 14;
BA_ "GenMsgCycleTime" BO_ 962 1000;
BA_ "VFrameFormat" BO_ 962 14;
BA_ "GenMsgCycleTime" BO_ 952 500;
BA_ "VFrameFormat" BO_ 952 14;
BA_ "GenMsgCycleTime" BO_ 953 500;
BA_ "VFrameFormat" BO_ 953 14;
BA_ "GenMsgCycleTime" BO_ 954 500;
BA_ "VFrameFormat" BO_ 954 14;
BA_ "GenMsgCycleTime" BO_ 1382 3500;
BA_ "VFrameFormat" BO_ 1382 14;
BA_ "GenMsgCycleTime" BO_ 1322 1000;
BA_ "VFrameFormat" BO_ 1322 14;
BA_ "GenMsgCycleTime" BO_ 1381 3500;
BA_ "VFrameFormat" BO_ 1381 14;
BA_ "GenMsgCycleTime" BO_ 1320 1000;
BA_ "VFrameFormat" BO_ 1320 14;
BA_ "GenMsgCycleTime" BO_ 1426 1000;
BA_ "VFrameFormat" BO_ 1426 14;
BA_ "VFrameFormat" BO_ 656 14;
BA_ "VFrameFormat" BO_ 244 14;
BA_ "VFrameFormat" BO_ 211 14;
BA_ "VFrameFormat" BO_ 245 14;
BA_ "SignalLongName" SG_ 69 AdpLgtHstLnLtCrv "Adaptive Lighting Host Lane Information : Adaptive Lighting Host Lane Left Curvature";
BA_ "SignalLongName" SG_ 69 AdpLgtHstLnLtCrvDrvt "Adaptive Lighting Host Lane Information : Adaptive Lighting Host Lane Left Curvature Derivative";
BA_ "SignalLongName" SG_ 69 AdpLgtHstLnRtCrv "Adaptive Lighting Host Lane Information : Adaptive Lighting Host Lane Right Curvature";
BA_ "SignalLongName" SG_ 69 AdpLgtHstLnRtCrvDrvt "Adaptive Lighting Host Lane Information : Adaptive Lighting Host Lane Right Curvature Derivative";
BA_ "SignalLongName" SG_ 69 AdpLgtHstLnLtOfst "Adaptive Lighting Host Lane Information : Adaptive Lighting Host Lane Left Offset";
BA_ "SignalLongName" SG_ 69 AdpLgtHstLnRtOfst "Adaptive Lighting Host Lane Information : Adaptive Lighting Host Lane Right Offset";
BA_ "SignalLongName" SG_ 69 AdpLgtHstLnLtHdg "Adaptive Lighting Host Lane Information : Adaptive Lighting Host Lane Left Heading";
BA_ "SignalLongName" SG_ 69 AdpLgtHstLnRtHdg "Adaptive Lighting Host Lane Information : Adaptive Lighting Host Lane Right Heading";
BA_ "SignalLongName" SG_ 69 AdpLgtHstLnLtVwRngLngDist "Adaptive Lighting Host Lane Information : Adaptive Lighting Host Lane Left View Range Longitudinal Distance";
BA_ "SignalLongName" SG_ 69 AdpLgtHstLnLtVwStrtLngDist "Adaptive Lighting Host Lane Information : Adaptive Lighting Host Lane Left View Start Longitudinal Distance";
BA_ "SignalLongName" SG_ 69 AdpLgtHstLnRtVwRngLngDist "Adaptive Lighting Host Lane Information : Adaptive Lighting Host Lane Right View Range Longitudinal Distance";
BA_ "SignalLongName" SG_ 69 AdpLgtHstLnRtVwStrtLngDist "Adaptive Lighting Host Lane Information : Adaptive Lighting Host Lane Right View Start Longitudinal Distance";
BA_ "SignalLongName" SG_ 69 AdpLgtHstLnLtWdth "Adaptive Lighting Host Lane Information : Adaptive Lighting Host Lane Left Width";
BA_ "SignalType" SG_ 69 AdpLgtHstLnLtTyp "ENM";
BA_ "SignalLongName" SG_ 69 AdpLgtHstLnLtTyp "Adaptive Lighting Host Lane Information : Adaptive Lighting Host Lane Left Type";
BA_ "SignalLongName" SG_ 69 AdpLgtHstLnRtWdth "Adaptive Lighting Host Lane Information : Adaptive Lighting Host Lane Right Width";
BA_ "SignalType" SG_ 69 AdpLgtHstLnRtQlty "ENM";
BA_ "SignalLongName" SG_ 69 AdpLgtHstLnRtQlty "Adaptive Lighting Host Lane Information : Adaptive Lighting Host Lane Right Quality";
BA_ "SignalType" SG_ 69 AdpLgtHstLnLtQlty "ENM";
BA_ "SignalLongName" SG_ 69 AdpLgtHstLnLtQlty "Adaptive Lighting Host Lane Information : Adaptive Lighting Host Lane Left Quality";
BA_ "SignalType" SG_ 69 AdpLgtHstLnRtTyp "ENM";
BA_ "SignalLongName" SG_ 69 AdpLgtHstLnRtTyp "Adaptive Lighting Host Lane Information : Adaptive Lighting Host Lane Right Type";
BA_ "SignalLongName" SG_ 225 ALOI3_RngTk10 "Adaptive Lighting Objects Information 3 : Range Track 10";
BA_ "SignalLongName" SG_ 225 ALOI3_RngTk11 "Adaptive Lighting Objects Information 3 : Range Track 11";
BA_ "SignalLongName" SG_ 225 ALOI3_RngTk12 "Adaptive Lighting Objects Information 3 : Range Track 12";
BA_ "SignalLongName" SG_ 225 ALOI3_RngTk9 "Adaptive Lighting Objects Information 3 : Range Track 9";
BA_ "SignalLongName" SG_ 225 ALOI3_AcqTmStm "Adaptive Lighting Objects Information 3 : Acquisition Time Stamp";
BA_ "SignalLongName" SG_ 225 ALOI3_AzmRateTk10 "Adaptive Lighting Objects Information 3 : Azimuth Rate Track 10";
BA_ "SignalLongName" SG_ 225 ALOI3_AzmRateTk11 "Adaptive Lighting Objects Information 3 : Azimuth Rate Track 11";
BA_ "SignalLongName" SG_ 225 ALOI3_AzmRateTk12 "Adaptive Lighting Objects Information 3 : Azimuth Rate Track 12";
BA_ "SignalLongName" SG_ 225 ALOI3_AzmRateTk9 "Adaptive Lighting Objects Information 3 : Azimuth Rate Track 9";
BA_ "SignalLongName" SG_ 225 ALOI3_AzmTk10 "Adaptive Lighting Objects Information 3 : Azimuth Track 10";
BA_ "SignalLongName" SG_ 225 ALOI3_AzmTk11 "Adaptive Lighting Objects Information 3 : Azimuth Track 11";
BA_ "SignalLongName" SG_ 225 ALOI3_AzmTk12 "Adaptive Lighting Objects Information 3 : Azimuth Track 12";
BA_ "SignalLongName" SG_ 225 ALOI3_AzmTk9 "Adaptive Lighting Objects Information 3 : Azimuth Track 9";
BA_ "SignalLongName" SG_ 225 ALOI3_WdthTk10 "Adaptive Lighting Objects Information 3 : Width Track 10";
BA_ "SignalLongName" SG_ 225 ALOI3_WdthTk11 "Adaptive Lighting Objects Information 3 : Width Track 11";
BA_ "SignalLongName" SG_ 225 ALOI3_WdthTk12 "Adaptive Lighting Objects Information 3 : Width Track 12";
BA_ "SignalLongName" SG_ 225 ALOI3_WdthTk9 "Adaptive Lighting Objects Information 3 : Width Track 9";
BA_ "SignalLongName" SG_ 225 ALOI3_RdSigGlrngTk10 "Adaptive Lighting Objects Information 3 : Road Signal Glaring Track 10";
BA_ "SignalLongName" SG_ 225 ALOI3_RdSigGlrngTk11 "Adaptive Lighting Objects Information 3 : Road Signal Glaring Track 11";
BA_ "SignalLongName" SG_ 225 ALOI3_RdSigGlrngTk12 "Adaptive Lighting Objects Information 3 : Road Signal Glaring Track 12";
BA_ "SignalLongName" SG_ 225 ALOI3_RdSigGlrngTk9 "Adaptive Lighting Objects Information 3 : Road Signal Glaring Track 9";
BA_ "SignalLongName" SG_ 225 ALOI3_IDTk10 "Adaptive Lighting Objects Information 3 : ID Track 10";
BA_ "SignalLongName" SG_ 225 ALOI3_IDTk12 "Adaptive Lighting Objects Information 3 : ID Track 12";
BA_ "SignalLongName" SG_ 225 ALOI3_IDTk11 "Adaptive Lighting Objects Information 3 : ID Track 11";
BA_ "SignalLongName" SG_ 225 ALOI3_IDTk9 "Adaptive Lighting Objects Information 3 : ID Track 9";
BA_ "SignalLongName" SG_ 225 ALOI3_VertPstnTk10 "Adaptive Lighting Objects Information 3 : Vertical Position Track 10";
BA_ "SignalLongName" SG_ 225 ALOI3_VertPstnTk12 "Adaptive Lighting Objects Information 3 : Vertical Position Track 12";
BA_ "SignalLongName" SG_ 225 ALOI3_VertPstnTk11 "Adaptive Lighting Objects Information 3 : Vertical Position Track 11";
BA_ "SignalLongName" SG_ 225 ALOI3_VertPstnTk9 "Adaptive Lighting Objects Information 3 : Vertical Position Track 9";
BA_ "SignalType" SG_ 225 ALOI3_TypTk11 "ENM";
BA_ "SignalLongName" SG_ 225 ALOI3_TypTk11 "Adaptive Lighting Objects Information 3 : Type Track 11";
BA_ "SignalType" SG_ 225 ALOI3_TypTk10 "ENM";
BA_ "SignalLongName" SG_ 225 ALOI3_TypTk10 "Adaptive Lighting Objects Information 3 : Type Track 10";
BA_ "SignalType" SG_ 225 ALOI3_TypTk9 "ENM";
BA_ "SignalLongName" SG_ 225 ALOI3_TypTk9 "Adaptive Lighting Objects Information 3 : Type Track 9";
BA_ "SignalType" SG_ 225 ALOI3_TypTk12 "ENM";
BA_ "SignalLongName" SG_ 225 ALOI3_TypTk12 "Adaptive Lighting Objects Information 3 : Type Track 12";
BA_ "SignalType" SG_ 225 ALOI3_DirTk11 "ENM";
BA_ "SignalLongName" SG_ 225 ALOI3_DirTk11 "Adaptive Lighting Objects Information 3 : Direction Track 11";
BA_ "SignalType" SG_ 225 ALOI3_DirTk10 "ENM";
BA_ "SignalLongName" SG_ 225 ALOI3_DirTk10 "Adaptive Lighting Objects Information 3 : Direction Track 10";
BA_ "SignalLongName" SG_ 225 ALOI3_ARC "Adaptive Lighting Objects Information 3 : Alive Rolling Count";
BA_ "SignalType" SG_ 225 ALOI3_DirTk9 "ENM";
BA_ "SignalLongName" SG_ 225 ALOI3_DirTk9 "Adaptive Lighting Objects Information 3 : Direction Track 9";
BA_ "SignalType" SG_ 225 ALOI3_DirTk12 "ENM";
BA_ "SignalLongName" SG_ 225 ALOI3_DirTk12 "Adaptive Lighting Objects Information 3 : Direction Track 12";
BA_ "SignalType" SG_ 225 ALOI3_CnfdTk9 "ENM";
BA_ "SignalLongName" SG_ 225 ALOI3_CnfdTk9 "Adaptive Lighting Objects Information 3 : Confidence Track 9";
BA_ "SignalType" SG_ 225 ALOI3_CnfdTk12 "ENM";
BA_ "SignalLongName" SG_ 225 ALOI3_CnfdTk12 "Adaptive Lighting Objects Information 3 : Confidence Track 12";
BA_ "SignalType" SG_ 225 ALOI3_CnfdTk11 "ENM";
BA_ "SignalLongName" SG_ 225 ALOI3_CnfdTk11 "Adaptive Lighting Objects Information 3 : Confidence Track 11";
BA_ "SignalType" SG_ 225 ALOI3_CnfdTk10 "ENM";
BA_ "SignalLongName" SG_ 225 ALOI3_CnfdTk10 "Adaptive Lighting Objects Information 3 : Confidence Track 10";
BA_ "SignalType" SG_ 225 ALOI3_MeasStsTk9 "ENM";
BA_ "SignalLongName" SG_ 225 ALOI3_MeasStsTk9 "Adaptive Lighting Objects Information 3 : Measurement Status Track 9";
BA_ "SignalType" SG_ 225 ALOI3_MeasStsTk12 "ENM";
BA_ "SignalLongName" SG_ 225 ALOI3_MeasStsTk12 "Adaptive Lighting Objects Information 3 : Measurement Status Track 12";
BA_ "SignalType" SG_ 225 ALOI3_MeasStsTk11 "ENM";
BA_ "SignalLongName" SG_ 225 ALOI3_MeasStsTk11 "Adaptive Lighting Objects Information 3 : Measurement Status Track 11";
BA_ "SignalType" SG_ 225 ALOI3_MeasStsTk10 "ENM";
BA_ "SignalLongName" SG_ 225 ALOI3_MeasStsTk10 "Adaptive Lighting Objects Information 3 : Measurement Status Track 10";
BA_ "SignalType" SG_ 225 ALOI3_RltvLnTk9 "ENM";
BA_ "SignalLongName" SG_ 225 ALOI3_RltvLnTk9 "Adaptive Lighting Objects Information 3 : Relative Lane Track 9";
BA_ "SignalType" SG_ 225 ALOI3_RltvLnTk12 "ENM";
BA_ "SignalLongName" SG_ 225 ALOI3_RltvLnTk12 "Adaptive Lighting Objects Information 3 : Relative Lane Track 12";
BA_ "SignalType" SG_ 225 ALOI3_RltvLnTk11 "ENM";
BA_ "SignalLongName" SG_ 225 ALOI3_RltvLnTk11 "Adaptive Lighting Objects Information 3 : Relative Lane Track 11";
BA_ "SignalType" SG_ 225 ALOI3_RltvLnTk10 "ENM";
BA_ "SignalLongName" SG_ 225 ALOI3_RltvLnTk10 "Adaptive Lighting Objects Information 3 : Relative Lane Track 10";
BA_ "SignalType" SG_ 225 TrfcSgnMemFtrSts "ENM";
BA_ "SignalLongName" SG_ 225 TrfcSgnMemFtrSts "Traffic Sign Memory Feature Status";
BA_ "SignalType" SG_ 225 ALOI3_RngTk9_Inv "ENM";
BA_ "SignalLongName" SG_ 225 ALOI3_RngTk9_Inv "Adaptive Lighting Objects Information 3 : Range Track 9 Invalid";
BA_ "SignalType" SG_ 225 ALOI3_RngTk12_Inv "ENM";
BA_ "SignalLongName" SG_ 225 ALOI3_RngTk12_Inv "Adaptive Lighting Objects Information 3 : Range Track 12 Invalid";
BA_ "SignalType" SG_ 225 ALOI3_RngTk11_Inv "ENM";
BA_ "SignalLongName" SG_ 225 ALOI3_RngTk11_Inv "Adaptive Lighting Objects Information 3 : Range Track 11 Invalid";
BA_ "SignalType" SG_ 225 ALOI3_RngTk10_Inv "ENM";
BA_ "SignalLongName" SG_ 225 ALOI3_RngTk10_Inv "Adaptive Lighting Objects Information 3 : Range Track 10 Invalid";
BA_ "SignalType" SG_ 225 ALOI3_AcqTmStm_Inv "ENM";
BA_ "SignalLongName" SG_ 225 ALOI3_AcqTmStm_Inv "Adaptive Lighting Objects Information 3 : Acquisition Time Stamp Invalid";
BA_ "SignalLongName" SG_ 1444 VehIdNmDig1 "Vehicle Identification Number Digit 1";
BA_ "SignalType" SG_ 963 NodeStsADIMb_CAN_9_LcFA "ENM";
BA_ "SignalLongName" SG_ 963 NodeStsADIMb_CAN_9_LcFA "Node Status ADIMb_CAN_9 Loss of Communication Fault Active";
BA_ "SignalType" SG_ 963 NodeStsADIMb_CAN_3_LcFA "ENM";
BA_ "SignalLongName" SG_ 963 NodeStsADIMb_CAN_3_LcFA "Node Status ADIMb_CAN_3 Loss of Communication Fault Active";
BA_ "SignalType" SG_ 963 NodeStsADIMb_CAN_2_LcFA "ENM";
BA_ "SignalLongName" SG_ 963 NodeStsADIMb_CAN_2_LcFA "Node Status ADIMb_CAN_2 Loss of Communication Fault Active";
BA_ "SignalType" SG_ 963 NodeStsADIMb_CAN_10_LcFA "ENM";
BA_ "SignalLongName" SG_ 963 NodeStsADIMb_CAN_10_LcFA "Node Status ADIMb_CAN_10 Loss of Communication Fault Active";
BA_ "SignalType" SG_ 963 NodeStsADIMa_CAN_9_LcFA "ENM";
BA_ "SignalLongName" SG_ 963 NodeStsADIMa_CAN_9_LcFA "Node Status ADIMa_CAN_9 Loss of Communication Fault Active";
BA_ "SignalType" SG_ 963 NodeStsADIMa_CAN_3_LcFA "ENM";
BA_ "SignalLongName" SG_ 963 NodeStsADIMa_CAN_3_LcFA "Node Status ADIMa CAN 3 Loss of Communication Fault Active";
BA_ "SignalType" SG_ 963 NodeStsADIMa_CAN_2_LcFA "ENM";
BA_ "SignalLongName" SG_ 963 NodeStsADIMa_CAN_2_LcFA "Node Status ADIMa_CAN_2 Loss of Communication Fault Active";
BA_ "SignalType" SG_ 963 NodeStsADIMa_CAN_10_LcFA "ENM";
BA_ "SignalLongName" SG_ 963 NodeStsADIMa_CAN_10_LcFA "Node Status ADIMa_CAN_10 Loss of Communication Fault Active";
BA_ "SignalType" SG_ 963 NodeStsAPA_CAN_1_LcFA "ENM";
BA_ "SignalLongName" SG_ 963 NodeStsAPA_CAN_1_LcFA "Node Status APA_CAN_1 Loss of Communication Fault Active";
BA_ "SignalType" SG_ 963 NodeStsAOS_LcFA "ENM";
BA_ "SignalLongName" SG_ 963 NodeStsAOS_LcFA "Node Status AOS Loss of Communication Fault Active";
BA_ "SignalType" SG_ 963 NodeStsAMP_LcFA "ENM";
BA_ "SignalLongName" SG_ 963 NodeStsAMP_LcFA "Node Status AMP Loss of Communication Fault Active";
BA_ "SignalType" SG_ 963 NodeStsALC_LcFA "ENM";
BA_ "SignalLongName" SG_ 963 NodeStsALC_LcFA "Node Status ALC Loss of Communication Fault Active";
BA_ "SignalType" SG_ 963 NodeStsAHS_LcFA "ENM";
BA_ "SignalLongName" SG_ 963 NodeStsAHS_LcFA "Node Status AHS Loss of Communication Fault Active";
BA_ "SignalType" SG_ 963 NodeStsAHL_AFL_CAN_2_LcFA "ENM";
BA_ "SignalLongName" SG_ 963 NodeStsAHL_AFL_CAN_2_LcFA "Node Status AHL_AFL CAN 2 Loss of Communication Fault Active";
BA_ "SignalType" SG_ 963 NodeStsBSM_MH_LcFA "ENM";
BA_ "SignalLongName" SG_ 963 NodeStsBSM_MH_LcFA "Node Status BSM_MH Loss of Communication Fault Active";
BA_ "SignalType" SG_ 963 NodeStsBSM_CAN_3_LcFA "ENM";
BA_ "SignalLongName" SG_ 963 NodeStsBSM_CAN_3_LcFA "Node Status BSM_CAN_3 Loss of Communication Fault Active";
BA_ "SignalType" SG_ 963 NodeStsBSM_CAN_2_LcFA "ENM";
BA_ "SignalLongName" SG_ 963 NodeStsBSM_CAN_2_LcFA "Node Status BSM_CAN_2 Loss of Communication Fault Active";
BA_ "SignalType" SG_ 963 NodeStsBCM_LcFA "ENM";
BA_ "SignalLongName" SG_ 963 NodeStsBCM_LcFA "Node Status BCM Loss of Communication Fault Active";
BA_ "SignalType" SG_ 963 NodeStsARS_LcFA "ENM";
BA_ "SignalLongName" SG_ 963 NodeStsARS_LcFA "Node Status ARS Loss of Communication Fault Active";
BA_ "SignalType" SG_ 963 NodeStsARB_LcFA "ENM";
BA_ "SignalLongName" SG_ 963 NodeStsARB_LcFA "Node Status ARB Loss of Communication Fault Active";
BA_ "SignalType" SG_ 963 NodeStsAPA_CAN_2_LcFA "ENM";
BA_ "SignalLongName" SG_ 963 NodeStsAPA_CAN_2_LcFA "Node Status APA_CAN_2 Loss of Communication Fault Active";
BA_ "SignalType" SG_ 963 NodeStsEBCM_AV_CAN_2_LcFA "ENM";
BA_ "SignalLongName" SG_ 963 NodeStsEBCM_AV_CAN_2_LcFA "Node Status EBCM AV CAN 2 Loss of Communication Fault Active";
BA_ "SignalType" SG_ 963 NodeStsDMS_LcFA "ENM";
BA_ "SignalLongName" SG_ 963 NodeStsDMS_LcFA "Node Status DMS Loss of Communication Fault Active";
BA_ "SignalType" SG_ 963 NodeStsDEFC_LcFA "ENM";
BA_ "SignalLongName" SG_ 963 NodeStsDEFC_LcFA "Node Status DEFC Loss of Communication Fault Active";
BA_ "SignalType" SG_ 963 NodeStsDCM_LcFA "ENM";
BA_ "SignalLongName" SG_ 963 NodeStsDCM_LcFA "Node Status DCM Loss of Communication Fault Active";
BA_ "SignalType" SG_ 963 NodeStsCSM_CAN_5_LcFA "ENM";
BA_ "SignalLongName" SG_ 963 NodeStsCSM_CAN_5_LcFA "Node Status CSM_CAN_5 Loss of Communication Fault Active";
BA_ "SignalType" SG_ 963 NodeStsECP_E_CAN_9_LcFA "ENM";
BA_ "SignalLongName" SG_ 963 NodeStsECP_E_CAN_9_LcFA "Node Status ECP_E CAN 9 Loss of Communication Fault Active";
BA_ "SignalType" SG_ 963 NodeStsECP_E_CAN_2_LcFA "ENM";
BA_ "SignalLongName" SG_ 963 NodeStsECP_E_CAN_2_LcFA "Node Status ECP_E_CAN_2 Loss of Communication Fault Active";
BA_ "SignalType" SG_ 963 NodeStsECM_CAN_3_LcFA "ENM";
BA_ "SignalLongName" SG_ 963 NodeStsECM_CAN_3_LcFA "Node Status ECM_CAN_3 Loss of Communication Fault Active";
BA_ "SignalType" SG_ 963 NodeStsECM_CAN_2_LcFA "ENM";
BA_ "SignalLongName" SG_ 963 NodeStsECM_CAN_2_LcFA "Node Status ECM_CAN_2 Loss of Communication Fault Active";
BA_ "SignalType" SG_ 963 NodeStsEBCM_CAN_3_LcFA "ENM";
BA_ "SignalLongName" SG_ 963 NodeStsEBCM_CAN_3_LcFA "Node Status EBCM CAN 3 Loss of Communication Fault Active";
BA_ "SignalType" SG_ 963 NodeStsEBCM_CAN_2_LcFA "ENM";
BA_ "SignalLongName" SG_ 963 NodeStsEBCM_CAN_2_LcFA "Node Status EBCM_CAN_2 Loss of Communication Fault Active";
BA_ "SignalType" SG_ 963 NodeStsEBCM_AV_CAN_3_LcFA "ENM";
BA_ "SignalLongName" SG_ 963 NodeStsEBCM_AV_CAN_3_LcFA "Node Status EBCM_AV CAN 3 Loss of Communication Fault Active";
BA_ "SignalType" SG_ 963 NodeStsEOCM_CAN_3_LcFA "ENM";
BA_ "SignalLongName" SG_ 963 NodeStsEOCM_CAN_3_LcFA "Node Status EOCM CAN 3 Loss of Communication Fault Active";
BA_ "SignalType" SG_ 963 NodeStsEOCM_CAN_2_LcFA "ENM";
BA_ "SignalLongName" SG_ 963 NodeStsEOCM_CAN_2_LcFA "Node Status EOCM_CAN_2 Loss of Communication Fault Active";
BA_ "SignalType" SG_ 963 NodeStsELM_LcFA "ENM";
BA_ "SignalLongName" SG_ 963 NodeStsELM_LcFA "Node Status ELM Loss of Communication Fault Active";
BA_ "SignalType" SG_ 963 NodeStsECP_X1_CAN_3_LcFA "ENM";
BA_ "SignalLongName" SG_ 963 NodeStsECP_X1_CAN_3_LcFA "Node Status ECP_X1_CAN_3 Loss of Communication Fault Active";
BA_ "SignalType" SG_ 963 NodeStsECP_X1_CAN_2_LcFA "ENM";
BA_ "SignalLongName" SG_ 963 NodeStsECP_X1_CAN_2_LcFA "Node Status ECP_X1_CAN_2 Loss of Communication Fault Active";
BA_ "SignalType" SG_ 963 NodeStsECP_S_CAN_9_LcFA "ENM";
BA_ "SignalLongName" SG_ 963 NodeStsECP_S_CAN_9_LcFA "Node Status ECP_S_CAN_9 Loss of Communication Fault Active";
BA_ "SignalType" SG_ 963 NodeStsECP_S_CAN_2_LcFA "ENM";
BA_ "SignalLongName" SG_ 963 NodeStsECP_S_CAN_2_LcFA "Node Status ECP_S CAN 2 Loss of Communication Fault Active";
BA_ "SignalType" SG_ 963 NodeStsECP_MC_LcFA "ENM";
BA_ "SignalLongName" SG_ 963 NodeStsECP_MC_LcFA "Node Status ECP_MC Loss of Communication Fault Active";
BA_ "SignalType" SG_ 963 NodeStsEPSRAa_LcFA "ENM";
BA_ "SignalLongName" SG_ 963 NodeStsEPSRAa_LcFA "Node Status EPSRAa Loss of Communication Fault Active";
BA_ "SignalType" SG_ 963 NodeStsEPS_LcFA "ENM";
BA_ "SignalLongName" SG_ 963 NodeStsEPS_LcFA "Node Status EPS Loss of Communication Fault Active";
BA_ "SignalType" SG_ 963 NodeStsEPS_1_LcFA "ENM";
BA_ "SignalLongName" SG_ 963 NodeStsEPS_1_LcFA "Node Status EPS_1 Loss of Communication Fault Active";
BA_ "SignalType" SG_ 963 NodeStsEOCM_HCP2_LcFA "ENM";
BA_ "SignalLongName" SG_ 963 NodeStsEOCM_HCP2_LcFA "Node Status EOCM_HCP2 Loss of Communication Fault Active";
BA_ "SignalType" SG_ 963 NodeStsEOCM_HCP1_CAN_8_LcFA "ENM";
BA_ "SignalLongName" SG_ 963 NodeStsEOCM_HCP1_CAN_8_LcFA "Node Status EOCM_HCP1_CAN_8 Loss of Communication Fault Active";
BA_ "SignalType" SG_ 963 NodeStsEOCM_HCP1_CAN_3_LcFA "ENM";
BA_ "SignalLongName" SG_ 963 NodeStsEOCM_HCP1_CAN_3_LcFA "Node Status EOCM_HCP1 CAN 3 Loss of Communication Fault Active";
BA_ "SignalType" SG_ 963 NodeStsEOCM_HCP1_CAN_2_LcFA "ENM";
BA_ "SignalLongName" SG_ 963 NodeStsEOCM_HCP1_CAN_2_LcFA "Node Status EOCM_HCP1_CAN_2 Loss of Communication Fault Active";
BA_ "SignalType" SG_ 963 NodeStsEOCM_CAN_8_LcFA "ENM";
BA_ "SignalLongName" SG_ 963 NodeStsEOCM_CAN_8_LcFA "Node Status EOCM_CAN_8 Loss of Communication Fault Active";
BA_ "SignalType" SG_ 963 NodeStsHVAC_FP_F_LcFA "ENM";
BA_ "SignalLongName" SG_ 963 NodeStsHVAC_FP_F_LcFA "Node Status HVAC_FP_F Loss of Communication Fault Active";
BA_ "SignalType" SG_ 963 NodeStsHUD_CAN_LcFA "ENM";
BA_ "SignalLongName" SG_ 963 NodeStsHUD_CAN_LcFA "Node Status HUD_CAN Loss of Communication Fault Active";
BA_ "SignalType" SG_ 963 NodeStsHDLM_LcFA "ENM";
BA_ "SignalLongName" SG_ 963 NodeStsHDLM_LcFA "Node Status HDLM Loss of Communication Fault Active";
BA_ "SignalType" SG_ 963 NodeStsFOPM_CAN_3_LcFA "ENM";
BA_ "SignalLongName" SG_ 963 NodeStsFOPM_CAN_3_LcFA "Node Status FOPM CAN 3 Loss of Communication Fault Active";
BA_ "SignalType" SG_ 963 NodeStsFOPM_CAN_2_LcFA "ENM";
BA_ "SignalLongName" SG_ 963 NodeStsFOPM_CAN_2_LcFA "Node Status FOPM_CAN_2 Loss of Communication Fault Active";
BA_ "SignalType" SG_ 963 NodeStsFCM_LcFA "ENM";
BA_ "SignalLongName" SG_ 963 NodeStsFCM_LcFA "Node Status FCM Loss of Communication Fault Active";
BA_ "SignalType" SG_ 963 NodeStsFCM_LC_LcFA "ENM";
BA_ "SignalLongName" SG_ 963 NodeStsFCM_LC_LcFA "Node Status FCM LC Loss of Communication Fault Active";
BA_ "SignalType" SG_ 963 NodeStsEPSRAb_LcFA "ENM";
BA_ "SignalLongName" SG_ 963 NodeStsEPSRAb_LcFA "Node Status EPSRAb Loss of Communication Fault Active";
BA_ "SignalType" SG_ 964 NodeStsMFC_LcFA "ENM";
BA_ "SignalLongName" SG_ 964 NodeStsMFC_LcFA "Node Status MFC Loss of Communication Fault Active";
BA_ "SignalType" SG_ 964 NodeStsLRR_LcFA "ENM";
BA_ "SignalLongName" SG_ 964 NodeStsLRR_LcFA "Node Status LRR Loss of Communication Fault Active";
BA_ "SignalType" SG_ 964 NodeStsLIB1_LcFA "ENM";
BA_ "SignalLongName" SG_ 964 NodeStsLIB1_LcFA "Node Status LIB1 Loss of Communication Fault Active";
BA_ "SignalType" SG_ 964 NodeStsIPC_CAN_5_LcFA "ENM";
BA_ "SignalLongName" SG_ 964 NodeStsIPC_CAN_5_LcFA "Node Status IPC CAN 5 Loss of Communication Fault Active";
BA_ "SignalType" SG_ 964 NodeStsICS_Info_LcFA "ENM";
BA_ "SignalLongName" SG_ 964 NodeStsICS_Info_LcFA "Node Status ICS_Info Loss of Communication Fault Active";
BA_ "SignalType" SG_ 964 NodeStsICCM_CAN_3_LcFA "ENM";
BA_ "SignalLongName" SG_ 964 NodeStsICCM_CAN_3_LcFA "Node Status ICCM CAN 3 Loss of Communication Fault Active";
BA_ "SignalType" SG_ 964 NodeStsHVAC_FP_R_LcFA "ENM";
BA_ "SignalLongName" SG_ 964 NodeStsHVAC_FP_R_LcFA "Node Status HVAC_FP_R Loss of Communication Fault Active";
BA_ "SignalType" SG_ 964 NodeStsMSM_RR_LcFA "ENM";
BA_ "SignalLongName" SG_ 964 NodeStsMSM_RR_LcFA "Node Status MSM_RR Loss of Communication Fault Active";
BA_ "SignalType" SG_ 964 NodeStsMSM_P_LcFA "ENM";
BA_ "SignalLongName" SG_ 964 NodeStsMSM_P_LcFA "Node Status MSM_P Loss of Communication Fault Active";
BA_ "SignalType" SG_ 964 NodeStsMSM_LR_LcFA "ENM";
BA_ "SignalLongName" SG_ 964 NodeStsMSM_LR_LcFA "Node Status MSM_LR Loss of Communication Fault Active";
BA_ "SignalType" SG_ 964 NodeStsMSM_D_LcFA "ENM";
BA_ "SignalLongName" SG_ 964 NodeStsMSM_D_LcFA "Node Status MSM_D Loss of Communication Fault Active";
BA_ "SignalType" SG_ 964 NodeStsMSB2_LcFA "ENM";
BA_ "SignalLongName" SG_ 964 NodeStsMSB2_LcFA "Node Status MSB2 Loss of Communication Fault Active";
BA_ "SignalType" SG_ 964 NodeStsMSB1_LcFA "ENM";
BA_ "SignalLongName" SG_ 964 NodeStsMSB1_LcFA "Node Status MSB1 Loss of Communication Fault Active";
BA_ "SignalType" SG_ 964 NodeStsMRCM_R_LcFA "ENM";
BA_ "SignalLongName" SG_ 964 NodeStsMRCM_R_LcFA "Node Status MRCM_R Loss of Communication Fault Active";
BA_ "SignalType" SG_ 964 NodeStsMRCM_L_LcFA "ENM";
BA_ "SignalLongName" SG_ 964 NodeStsMRCM_L_LcFA "Node Status MRCM_L Loss of Communication Fault Active";
BA_ "SignalType" SG_ 964 NodeStsRDCM_LcFA "ENM";
BA_ "SignalLongName" SG_ 964 NodeStsRDCM_LcFA "Node Status RDCM Loss of Communication Fault Active";
BA_ "SignalType" SG_ 964 NodeStsRadioLow_LcFA "ENM";
BA_ "SignalLongName" SG_ 964 NodeStsRadioLow_LcFA "Node Status RadioLow Loss of Communication Fault Active";
BA_ "SignalType" SG_ 964 NodeStsPTM_LcFA "ENM";
BA_ "SignalLongName" SG_ 964 NodeStsPTM_LcFA "Node Status PTM Loss of Communication Fault Active";
BA_ "SignalType" SG_ 964 NodeStsPDR_LcFA "ENM";
BA_ "SignalLongName" SG_ 964 NodeStsPDR_LcFA "Node Status PDR Loss of Communication Fault Active";
BA_ "SignalType" SG_ 964 NodeStsPA_LcFA "ENM";
BA_ "SignalLongName" SG_ 964 NodeStsPA_LcFA "Node Status PA Loss of Communication Fault Active";
BA_ "SignalType" SG_ 964 NodeStsNVM_LcFA "ENM";
BA_ "SignalLongName" SG_ 964 NodeStsNVM_LcFA "Node Status NVM Loss of Communication Fault Active";
BA_ "SignalType" SG_ 964 NodeStsMTCM_R_LcFA "ENM";
BA_ "SignalLongName" SG_ 964 NodeStsMTCM_R_LcFA "Node Status MTCM_R Loss of Communication Fault Active";
BA_ "SignalType" SG_ 964 NodeStsMTCM_L_LcFA "ENM";
BA_ "SignalLongName" SG_ 964 NodeStsMTCM_L_LcFA "Node Status MTCM_L Loss of Communication Fault Active";
BA_ "SignalType" SG_ 964 NodeStsSBM_CAN_3_LcFA "ENM";
BA_ "SignalLongName" SG_ 964 NodeStsSBM_CAN_3_LcFA "Node Status SBM CAN 3 Loss of Communication Fault Active";
BA_ "SignalType" SG_ 964 NodeStsSAM_RR_LcFA "ENM";
BA_ "SignalLongName" SG_ 964 NodeStsSAM_RR_LcFA "Node Status SAM RR Loss of Communication Fault Active";
BA_ "SignalType" SG_ 964 NodeStsSAM_RF_LcFA "ENM";
BA_ "SignalLongName" SG_ 964 NodeStsSAM_RF_LcFA "Node Status SAM RF Loss of Communication Fault Active";
BA_ "SignalType" SG_ 964 NodeStsSAM_LR_LcFA "ENM";
BA_ "SignalLongName" SG_ 964 NodeStsSAM_LR_LcFA "Node Status SAM LR Loss of Communication Fault Active";
BA_ "SignalType" SG_ 964 NodeStsSAM_LF_LcFA "ENM";
BA_ "SignalLongName" SG_ 964 NodeStsSAM_LF_LcFA "Node Status SAM LF Loss of Communication Fault Active";
BA_ "SignalType" SG_ 964 NodeStsSADS_LcFA "ENM";
BA_ "SignalLongName" SG_ 964 NodeStsSADS_LcFA "Node Status SADS Loss of Communication Fault Active";
BA_ "SignalType" SG_ 964 NodeStsSRR_RF_LcFA "ENM";
BA_ "SignalLongName" SG_ 964 NodeStsSRR_RF_LcFA "Node Status SRR_RF Loss of Communication Fault Active";
BA_ "SignalType" SG_ 964 NodeStsSRR_LR_CR_LcFA "ENM";
BA_ "SignalLongName" SG_ 964 NodeStsSRR_LR_CR_LcFA "Node Status SRR_LR_CR Loss of Communication Fault Active";
BA_ "SignalType" SG_ 964 NodeStsSRR_LF_LcFA "ENM";
BA_ "SignalLongName" SG_ 964 NodeStsSRR_LF_LcFA "Node Status SRR_LF Loss of Communication Fault Active";
BA_ "SignalType" SG_ 964 NodeStsSIB_LcFA "ENM";
BA_ "SignalLongName" SG_ 964 NodeStsSIB_LcFA "Node Status SIB Loss of Communication Fault Active";
BA_ "SignalType" SG_ 964 NodeStsSDM_LcFA "ENM";
BA_ "SignalLongName" SG_ 964 NodeStsSDM_LcFA "Node Status SDM Loss of Communication Fault Active";
BA_ "SignalType" SG_ 964 NodeStsSCL_LcFA "ENM";
BA_ "SignalLongName" SG_ 964 NodeStsSCL_LcFA "Node Status SCL Loss of Communication Fault Active";
BA_ "SignalType" SG_ 964 NodeStsSBZA_R_LcFA "ENM";
BA_ "SignalLongName" SG_ 964 NodeStsSBZA_R_LcFA "Node Status SBZA_R Loss of Communication Fault Active";
BA_ "SignalType" SG_ 964 NodeStsSBZA_L_LcFA "ENM";
BA_ "SignalLongName" SG_ 964 NodeStsSBZA_L_LcFA "Node Status SBZA_L Loss of Communication Fault Active";
BA_ "SignalType" SG_ 964 NodeStsTCP_CAN_5_LcFA "ENM";
BA_ "SignalLongName" SG_ 964 NodeStsTCP_CAN_5_LcFA "Node Status TCP_CAN_5 Loss of Communication Fault Active";
BA_ "SignalType" SG_ 964 NodeStsTCM_CAN_2_LcFA "ENM";
BA_ "SignalLongName" SG_ 964 NodeStsTCM_CAN_2_LcFA "Node Status TCM_CAN_2 Loss of Communication Fault Active";
BA_ "SignalType" SG_ 964 NodeStsTCCM_LcFA "ENM";
BA_ "SignalLongName" SG_ 964 NodeStsTCCM_LcFA "Node Status TCCM Loss of Communication Fault Active";
BA_ "SignalType" SG_ 964 NodeStsSRR_SRR_LcFA "ENM";
BA_ "SignalLongName" SG_ 964 NodeStsSRR_SRR_LcFA "Node Status SRR_SRR Loss of Communication Fault Active";
BA_ "SignalType" SG_ 964 NodeStsSRR_SLR_LcFA "ENM";
BA_ "SignalLongName" SG_ 964 NodeStsSRR_SLR_LcFA "Node Status SRR_SLR Loss of Communication Fault Active";
BA_ "SignalType" SG_ 964 NodeStsSRR_RR_LcFA "ENM";
BA_ "SignalLongName" SG_ 964 NodeStsSRR_RR_LcFA "Node Status SRR_RR Loss of Communication Fault Active";
BA_ "SignalType" SG_ 964 NodeStsWCM_LcFA "ENM";
BA_ "SignalLongName" SG_ 964 NodeStsWCM_LcFA "Node Status WCM Loss of Communication Fault Active";
BA_ "SignalType" SG_ 964 NodeStsVPM_LcFA "ENM";
BA_ "SignalLongName" SG_ 964 NodeStsVPM_LcFA "Node Status VPM Loss of Communication Fault Active";
BA_ "SignalType" SG_ 964 NodeStsVLM_LcFA "ENM";
BA_ "SignalLongName" SG_ 964 NodeStsVLM_LcFA "Node Status VLM Loss of Communication Fault Active";
BA_ "SignalType" SG_ 964 NodeStsVKM_LcFA "ENM";
BA_ "SignalLongName" SG_ 964 NodeStsVKM_LcFA "Node StatusVKM Loss of Communication Fault Active";
BA_ "SignalType" SG_ 964 NodeStsVICM_CAN_9_LcFA "ENM";
BA_ "SignalLongName" SG_ 964 NodeStsVICM_CAN_9_LcFA "Node Status VICM_CAN_9 Loss of Communication Fault Active";
BA_ "SignalType" SG_ 964 NodeStsVICM_CAN_2_LcFA "ENM";
BA_ "SignalLongName" SG_ 964 NodeStsVICM_CAN_2_LcFA "Node Status VICM_CAN_2 Loss of Communication Fault Active";
BA_ "SignalType" SG_ 964 NodeStsVCU_CAN_5_LcFA "ENM";
BA_ "SignalLongName" SG_ 964 NodeStsVCU_CAN_5_LcFA "Node Status VCU_CAN_5 Loss of Communication Fault Active";
BA_ "SignalType" SG_ 964 NodeStsTIM_LcFA "ENM";
BA_ "SignalLongName" SG_ 964 NodeStsTIM_LcFA "Node Status TIM Loss of Communication Fault Active";
BA_ "SignalType" SG_ 964 NodeStsECP_S2_CAN_2_LcFA "ENM";
BA_ "SignalLongName" SG_ 964 NodeStsECP_S2_CAN_2_LcFA "Node Status ECP_S2_CAN_2 Loss of Communication Fault Active";
BA_ "SignalType" SG_ 964 NodeStsPFCM_LcFA "ENM";
BA_ "SignalLongName" SG_ 964 NodeStsPFCM_LcFA "Node Status PFCM Loss of Communication Fault Active";
BA_ "SignalType" SG_ 964 NodeStsVDM_CAN_2_LcFA "ENM";
BA_ "SignalLongName" SG_ 964 NodeStsVDM_CAN_2_LcFA "Node Status VDM_CAN_2 Loss of Communication Fault Active";
BA_ "SignalType" SG_ 964 NodeStsPCM_CAN_3_LcFA "ENM";
BA_ "SignalLongName" SG_ 964 NodeStsPCM_CAN_3_LcFA "Node Status PCM_CAN_3 Loss of Communication Fault Active";
BA_ "SignalType" SG_ 964 NodeStsPCM_CAN_2_LcFA "ENM";
BA_ "SignalLongName" SG_ 964 NodeStsPCM_CAN_2_LcFA "Node Status PCM_CAN_2 Loss of Communication Fault Active";
BA_ "SignalType" SG_ 964 NodeStsSDM_AV_LcFA "ENM";
BA_ "SignalLongName" SG_ 964 NodeStsSDM_AV_LcFA "Node Status SDM_AV Loss of Communication Fault Active";
BA_ "SignalType" SG_ 962 NodeStsACP4_MCU_CAN_2_LcFA "ENM";
BA_ "SignalLongName" SG_ 962 NodeStsACP4_MCU_CAN_2_LcFA "Node Status ACP4_MCU_CAN_2 Loss of Communication Fault Active";
BA_ "SignalType" SG_ 962 NodeStsACP2_MCU_CAN_8_LcFA "ENM";
BA_ "SignalLongName" SG_ 962 NodeStsACP2_MCU_CAN_8_LcFA "Node Status ACP2_MCU CAN_8 Loss of Communication Fault Active";
BA_ "SignalType" SG_ 962 NodeStsACP2_MCU_CAN_2_LcFA "ENM";
BA_ "SignalLongName" SG_ 962 NodeStsACP2_MCU_CAN_2_LcFA "Node Status ACP2_MCU CAN_2 Loss of Communication Fault Active";
BA_ "SignalType" SG_ 962 NodeStsVECM_CAN_2_LcFA "ENM";
BA_ "SignalLongName" SG_ 962 NodeStsVECM_CAN_2_LcFA "Node Status VECM_CAN_2 Loss of Communication Fault Active";
BA_ "SignalType" SG_ 962 NodeStsVDM_CAN_9_LcFA "ENM";
BA_ "SignalLongName" SG_ 962 NodeStsVDM_CAN_9_LcFA "Node Status VDM_CAN_9 Loss of Communication Fault Active";
BA_ "SignalType" SG_ 962 NodeStsUVM_CAN_1_LcFA "ENM";
BA_ "SignalLongName" SG_ 962 NodeStsUVM_CAN_1_LcFA "Node Status UVM_CAN_1 Loss of Communication Fault Active";
BA_ "SignalType" SG_ 962 NodeStsUPM_LcFA "ENM";
BA_ "SignalLongName" SG_ 962 NodeStsUPM_LcFA "Node Status UPM Loss of Communication Fault Active";
BA_ "SignalType" SG_ 962 NodeStsEPSb_LcFA "ENM";
BA_ "SignalLongName" SG_ 962 NodeStsEPSb_LcFA "Node Status EPSb Loss of Communication Fault Active";
BA_ "SignalType" SG_ 962 NodeStsSBM_CAN_10_LcFA "ENM";
BA_ "SignalLongName" SG_ 962 NodeStsSBM_CAN_10_LcFA "Node Status SBM_CAN_10 Loss of Communication Fault Active";
BA_ "SignalType" SG_ 962 NodeStsVECM_CAN_9_LcFA "ENM";
BA_ "SignalLongName" SG_ 962 NodeStsVECM_CAN_9_LcFA "Node Status VECM_CAN_9 Loss of Communication Fault Active";
BA_ "SignalType" SG_ 962 NodeStsECP_S2_CAN_9_LcFA "ENM";
BA_ "SignalLongName" SG_ 962 NodeStsECP_S2_CAN_9_LcFA "Node Status ECP_S2_CAN_9 Loss of Communication Fault Active";
BA_ "SignalType" SG_ 962 NodeStsCSM_AV_CAN_5_LcFA "ENM";
BA_ "SignalLongName" SG_ 962 NodeStsCSM_AV_CAN_5_LcFA "Node Status CSM_AV_CAN_5 Loss of Communication Fault Active";
BA_ "SignalType" SG_ 962 NodeStsACP3_MCU_CAN_3_LcFA "ENM";
BA_ "SignalLongName" SG_ 962 NodeStsACP3_MCU_CAN_3_LcFA "Node Status ACP3_MCU CAN_3 Loss of Communication Fault Active";
BA_ "SignalType" SG_ 962 NodeStsACP3_MCU_CAN_8_LcFA "ENM";
BA_ "SignalLongName" SG_ 962 NodeStsACP3_MCU_CAN_8_LcFA "Node Status ACP3_MCU CAN_8 Loss of Communication Fault Active";
BA_ "SignalType" SG_ 962 NodeStsACP3_MCU_CAN_2_LcFA "ENM";
BA_ "SignalLongName" SG_ 962 NodeStsACP3_MCU_CAN_2_LcFA "Node Status ACP3_MCU CAN_2 Loss of Communication Fault Active";
BA_ "SignalType" SG_ 962 NodeStsWCM4_LcFA "ENM";
BA_ "SignalLongName" SG_ 962 NodeStsWCM4_LcFA "Node Status WCM4 Loss of Communication Fault Active";
BA_ "SignalType" SG_ 962 NodeStsWCM3_LcFA "ENM";
BA_ "SignalLongName" SG_ 962 NodeStsWCM3_LcFA "Node Status WCM3 Loss of Communication Fault Active";
BA_ "SignalType" SG_ 962 NodeStsWCM2_LcFA "ENM";
BA_ "SignalLongName" SG_ 962 NodeStsWCM2_LcFA "Node Status WCM2 Loss of Communication Fault Active";
BA_ "SignalType" SG_ 962 NodeStsRSI_CAN_5_LcFA "ENM";
BA_ "SignalLongName" SG_ 962 NodeStsRSI_CAN_5_LcFA "Node Status RSI Loss of Communication Fault Active";
BA_ "SignalType" SG_ 962 NodeStsLIB_48V_LcFA "ENM";
BA_ "SignalLongName" SG_ 962 NodeStsLIB_48V_LcFA "Node Status LIB_48V Loss of Communication Fault Active";
BA_ "SignalType" SG_ 962 NodeStsFPI_CAN_5_LcFA "ENM";
BA_ "SignalLongName" SG_ 962 NodeStsFPI_CAN_5_LcFA "Node Status FPI Loss of Communication Fault Active";
BA_ "SignalType" SG_ 962 NodeStsACP4_MCU_CAN_3_LcFA "ENM";
BA_ "SignalLongName" SG_ 962 NodeStsACP4_MCU_CAN_3_LcFA "Node Status ACP4_MCU_CAN_3 Loss of Communication Fault Active";
BA_ "SignalType" SG_ 962 NodeStsACP4_MCU_CAN_8_LcFA "ENM";
BA_ "SignalLongName" SG_ 962 NodeStsACP4_MCU_CAN_8_LcFA "Node Status ACP4 MCU_CAN_8 Loss of Communication Fault Active";
BA_ "SignalType" SG_ 962 NodeStsBSM_HEV_CAN_2_LcFA "ENM";
BA_ "SignalLongName" SG_ 962 NodeStsBSM_HEV_CAN_2_LcFA "Node Status BSM_HEV_CAN_2 Loss of Communication Fault Active";
BA_ "SignalType" SG_ 962 NodeStsECP_H3_CAN_2_LcFA "ENM";
BA_ "SignalLongName" SG_ 962 NodeStsECP_H3_CAN_2_LcFA "Node Status ECP_H3_CAN_2 Loss of Communication Fault Active";
BA_ "SignalType" SG_ 962 NodeStsECP_H2_CAN_2_LcFA "ENM";
BA_ "SignalLongName" SG_ 962 NodeStsECP_H2_CAN_2_LcFA "Node Status ECP_H2_CAN_2 Loss of Communication Fault Active";
BA_ "SignalType" SG_ 962 NodeStsECP_H2_CAN_9_LcFA "ENM";
BA_ "SignalLongName" SG_ 962 NodeStsECP_H2_CAN_9_LcFA "Node Status ECP_H2_CAN_9 Loss of Communication Fault Active";
BA_ "SignalType" SG_ 962 NodeStsECP_H1_CAN_9_LcFA "ENM";
BA_ "SignalLongName" SG_ 962 NodeStsECP_H1_CAN_9_LcFA "Node Status ECP_H1_CAN_9 Loss of Communication Fault Active";
BA_ "SignalType" SG_ 962 NodeStsECP_H1_CAN_2_LcFA "ENM";
BA_ "SignalLongName" SG_ 962 NodeStsECP_H1_CAN_2_LcFA "Node Status ECP_H1_CAN_2 Loss of Communication Fault Active";
BA_ "SignalType" SG_ 962 NodeStsBSM_HEV_CAN_9_LcFA "ENM";
BA_ "SignalLongName" SG_ 962 NodeStsBSM_HEV_CAN_9_LcFA "Node Status BSM_HEV_CAN_9 Loss of Communication Fault Active";
BA_ "SignalType" SG_ 962 NodeStsECP_H3_CAN_9_LcFA "ENM";
BA_ "SignalLongName" SG_ 962 NodeStsECP_H3_CAN_9_LcFA "Node Status ECP_H3_CAN_9 Loss of Communication Fault Active";
BA_ "SignalType" SG_ 962 NodeStsSAM_BH_LcFA "ENM";
BA_ "SignalLongName" SG_ 962 NodeStsSAM_BH_LcFA "Node Status SAM_BH Loss of Communication Fault Active";
BA_ "SignalType" SG_ 962 NodeStsPLCM_LcFA "ENM";
BA_ "SignalLongName" SG_ 962 NodeStsPLCM_LcFA "Node Status PLCM Loss of Communication Fault Active";
BA_ "SignalType" SG_ 962 NodeStsODS_LcFA "ENM";
BA_ "SignalLongName" SG_ 962 NodeStsODS_LcFA "Node Status ODS Loss of Communication Fault Active";
BA_ "SignalType" SG_ 962 NodeStsODS2_LcFA "ENM";
BA_ "SignalLongName" SG_ 962 NodeStsODS2_LcFA "Node Status ODS2 Loss of Communication Fault Active";
BA_ "SignalType" SG_ 952 NodeStsSRR_SRR_Prsnt "ENM";
BA_ "SignalLongName" SG_ 952 NodeStsSRR_SRR_Prsnt "Node Status SRR_SRR Present";
BA_ "SignalType" SG_ 952 NodeStsEOCM_HCP2_Prsnt "ENM";
BA_ "SignalLongName" SG_ 952 NodeStsEOCM_HCP2_Prsnt "Node Status EOCM_HCP2 Present";
BA_ "SignalType" SG_ 952 NodeStsEOCM_HCP1_CAN_3_Prsnt "ENM";
BA_ "SignalLongName" SG_ 952 NodeStsEOCM_HCP1_CAN_3_Prsnt "Node Status EOCM_HCP1 CAN_3 Present";
BA_ "SignalType" SG_ 952 NodeStsFCM_Prsnt "ENM";
BA_ "SignalLongName" SG_ 952 NodeStsFCM_Prsnt "Node Status FCM Present";
BA_ "SignalType" SG_ 952 NodeStsSBZA_L_Prsnt "ENM";
BA_ "SignalLongName" SG_ 952 NodeStsSBZA_L_Prsnt "Node Status SBZA_L Present";
BA_ "SignalType" SG_ 952 NodeStsMSM_LR_Prsnt "ENM";
BA_ "SignalLongName" SG_ 952 NodeStsMSM_LR_Prsnt "Node Status MSM_LR Present";
BA_ "SignalType" SG_ 952 NodeStsACP2_MCU_CAN_2_Prsnt "ENM";
BA_ "SignalLongName" SG_ 952 NodeStsACP2_MCU_CAN_2_Prsnt "Node Status ACP2_MCU CAN_2 Present";
BA_ "SignalType" SG_ 952 NodeStsMSM_P_Prsnt "ENM";
BA_ "SignalLongName" SG_ 952 NodeStsMSM_P_Prsnt "Node Status MSM_P Present";
BA_ "SignalType" SG_ 952 NodeStsACP4_MCU_CAN_3_Prsnt "ENM";
BA_ "SignalLongName" SG_ 952 NodeStsACP4_MCU_CAN_3_Prsnt "Node Status ACP4_MCU CAN_3 Present";
BA_ "SignalType" SG_ 953 NodeStsACP3_MCU_CAN_3_Prsnt "ENM";
BA_ "SignalLongName" SG_ 953 NodeStsACP3_MCU_CAN_3_Prsnt "Node Status ACP3_MCU CAN_3 Present";
BA_ "SignalType" SG_ 953 NodeStsEOCM_CAN_2_Prsnt "ENM";
BA_ "SignalLongName" SG_ 953 NodeStsEOCM_CAN_2_Prsnt "Node Status EOCM CAN_2 Present";
BA_ "SignalType" SG_ 953 NodeStsACP2_MCU_CAN_8_Prsnt "ENM";
BA_ "SignalLongName" SG_ 953 NodeStsACP2_MCU_CAN_8_Prsnt "Node Status ACP2_MCU CAN_8 Present";
BA_ "SignalType" SG_ 953 NodeStsFCM_LC_Prsnt "ENM";
BA_ "SignalLongName" SG_ 953 NodeStsFCM_LC_Prsnt "Node Status FCM_LC Present";
BA_ "SignalType" SG_ 953 NodeStsEOCM_HCP1_CAN_2_Prsnt "ENM";
BA_ "SignalLongName" SG_ 953 NodeStsEOCM_HCP1_CAN_2_Prsnt "Node Status EOCM_HCP1 CAN_2 Present";
BA_ "SignalType" SG_ 953 NodeStsSRR_LF_Prsnt "ENM";
BA_ "SignalLongName" SG_ 953 NodeStsSRR_LF_Prsnt "Node Status SRR_LF Present";
BA_ "SignalType" SG_ 953 NodeStsSRR_RF_Prsnt "ENM";
BA_ "SignalLongName" SG_ 953 NodeStsSRR_RF_Prsnt "Node Status SRR_RF Present";
BA_ "SignalType" SG_ 953 NodeStsACP3_MCU_CAN_8_Prsnt "ENM";
BA_ "SignalLongName" SG_ 953 NodeStsACP3_MCU_CAN_8_Prsnt "Node Status ACP3_MCU CAN_8 Present";
BA_ "SignalType" SG_ 953 NodeStsSBZA_R_Prsnt "ENM";
BA_ "SignalLongName" SG_ 953 NodeStsSBZA_R_Prsnt "Node Status SBZA_R Present";
BA_ "SignalType" SG_ 953 NodeStsSRR_LR_CR_Prsnt "ENM";
BA_ "SignalLongName" SG_ 953 NodeStsSRR_LR_CR_Prsnt "Node Status SRR_LR_CR Present";
BA_ "SignalType" SG_ 953 NodeStsSRR_RR_Prsnt "ENM";
BA_ "SignalLongName" SG_ 953 NodeStsSRR_RR_Prsnt "Node Status SRR_RR Present";
BA_ "SignalType" SG_ 953 NodeStsSRR_SLR_Prsnt "ENM";
BA_ "SignalLongName" SG_ 953 NodeStsSRR_SLR_Prsnt "Node Status SRR_SLR Present";
BA_ "SignalType" SG_ 953 NodeStsEOCM_HCP1_CAN_8_Prsnt "ENM";
BA_ "SignalLongName" SG_ 953 NodeStsEOCM_HCP1_CAN_8_Prsnt "Node Status EOCM_HCP1 CAN_8 Present";
BA_ "SignalType" SG_ 954 NodeStsMSM_RR_Prsnt "ENM";
BA_ "SignalLongName" SG_ 954 NodeStsMSM_RR_Prsnt "Node Status MSM_RR Present";
BA_ "SignalType" SG_ 954 NodeStsEOCM_CAN_8_Prsnt "ENM";
BA_ "SignalLongName" SG_ 954 NodeStsEOCM_CAN_8_Prsnt "Node Status EOCM CAN_8 Present";
BA_ "SignalType" SG_ 954 NodeStsMSM_D_Prsnt "ENM";
BA_ "SignalLongName" SG_ 954 NodeStsMSM_D_Prsnt "Node Status MSM_D Present";
BA_ "SignalType" SG_ 954 NodeStsACP3_MCU_CAN_2_Prsnt "ENM";
BA_ "SignalLongName" SG_ 954 NodeStsACP3_MCU_CAN_2_Prsnt "Node Status ACP3_MCU CAN_2 Present";
BA_ "SignalType" SG_ 954 NodeStsACP4_MCU_CAN_2_Prsnt "ENM";
BA_ "SignalLongName" SG_ 954 NodeStsACP4_MCU_CAN_2_Prsnt "Node Status ACP4_MCU CAN_2 Present";
BA_ "SignalType" SG_ 954 NodeStsEOCM_CAN_3_Prsnt "ENM";
BA_ "SignalLongName" SG_ 954 NodeStsEOCM_CAN_3_Prsnt "Node Status EOCM CAN_3 Present";
BA_ "SignalType" SG_ 954 NodeStsACP4_MCU_CAN_8_Prsnt "ENM";
BA_ "SignalLongName" SG_ 954 NodeStsACP4_MCU_CAN_8_Prsnt "Node Status ACP4_MCU CAN_8 Present";
BA_ "SignalLongName" SG_ 1382 OccptRstrntInfo_PCSM "Occupant Restraint Information Protected Counter Sync Message";
BA_ "SignalLongName" SG_ 1322 ORIP_MAC "Occupant Restraint Information Protected : MAC";
BA_ "SignalLongName" SG_ 1322 ORIP_FCnt "Occupant Restraint Information Protected : Freshness Counter";
BA_ "SignalType" SG_ 1322 FrtPsngrAirbagDsblVisIndCmd "ENM";
BA_ "SignalLongName" SG_ 1322 FrtPsngrAirbagDsblVisIndCmd "Occupant Restraint Information Protected : Front Passenger Airbag Disable Visual Indication Command";
BA_ "SignalLongName" SG_ 1322 ORIP_ARC "Occupant Restraint Information Protected : Alive Rolling Count";
BA_ "SignalType" SG_ 1322 ORIP_EnvModPrsntRsp1Auth "ENM";
BA_ "SignalLongName" SG_ 1322 ORIP_EnvModPrsntRsp1Auth "Occupant Restraint Information Protected : Environment Module Present - Responder #1 Authenticated";
BA_ "SignalType" SG_ 1322 ORIP_DrvrStBltStsAuth_Inv "ENM";
BA_ "SignalLongName" SG_ 1322 ORIP_DrvrStBltStsAuth_Inv "Occupant Restraint Information Protected : Driver Seat Belt Status Authenticated Invalid";
BA_ "SignalType" SG_ 1322 ORIP_DrvrStBltStsAuth "ENM";
BA_ "SignalLongName" SG_ 1322 ORIP_DrvrStBltStsAuth "Occupant Restraint Information Protected : Driver Seat Belt Status Authenticated";
BA_ "SignalLongName" SG_ 1322 ORIP_Filler "Occupant Restraint Information Protected : Filler";
BA_ "SignalType" SG_ 1322 RstrntSysFltPrsnt "ENM";
BA_ "SignalLongName" SG_ 1322 RstrntSysFltPrsnt "Occupant Restraint Information Protected : Restraint System Fault Present";
BA_ "SignalType" SG_ 1322 FrtPsngrAirbagEnblVisIndCmd "ENM";
BA_ "SignalLongName" SG_ 1322 FrtPsngrAirbagEnblVisIndCmd "Occupant Restraint Information Protected : Front Passenger Airbag Enable Visual Indication Command";
BA_ "SignalLongName" SG_ 1381 PstClsnInfo_PCSM "Post Collision Information Protected Counter Sync Message";
BA_ "SignalLongName" SG_ 1320 PCIP_MAC "Post Collision Information Protected : MAC";
BA_ "SignalLongName" SG_ 1320 PCIP_FCnt "Post Collision Information Protected : Freshness Counter";
BA_ "SignalType" SG_ 1320 PCIP_HzrdLgtsOnReqdAuth "ENM";
BA_ "SignalLongName" SG_ 1320 PCIP_HzrdLgtsOnReqdAuth "Post Collision Information Protected : Hazard Lights On Requested Authenticated";
BA_ "SignalType" SG_ 1320 PCIP_HybVehHiVltgDsblReqdAuth "ENM";
BA_ "SignalLongName" SG_ 1320 PCIP_HybVehHiVltgDsblReqdAuth "Post Collision Information Protected : High Voltage System Disable Requested Authenticated";
BA_ "SignalType" SG_ 1320 PCIP_HVCrshImpSnsSysDsbldAuth "ENM";
BA_ "SignalLongName" SG_ 1320 PCIP_HVCrshImpSnsSysDsbldAuth "Post Collision Information Protected : High Voltage Crash Impact Sensing System Disabled Authenticated";
BA_ "SignalType" SG_ 1320 PCIP_HVACBlwDsblReqdAuth "ENM";
BA_ "SignalLongName" SG_ 1320 PCIP_HVACBlwDsblReqdAuth "Post Collision Information Protected : HVAC Blower Disable Requested Authenticated";
BA_ "SignalType" SG_ 1320 PCIP_FuelCutOffReqdAuth "ENM";
BA_ "SignalLongName" SG_ 1320 PCIP_FuelCutOffReqdAuth "Post Collision Information Protected : Fuel Cut Off Requested Authenticated";
BA_ "SignalType" SG_ 1320 PCIP_DrUnlckReqdAuth "ENM";
BA_ "SignalLongName" SG_ 1320 PCIP_DrUnlckReqdAuth "Post Collision Information Protected : Door Unlock Requested Authenticated";
BA_ "SignalType" SG_ 1320 PCIP_CruzCtlDsblReqdAuth "ENM";
BA_ "SignalLongName" SG_ 1320 PCIP_CruzCtlDsblReqdAuth "Post Collision Information Protected : Cruise Control Disable Requested Authenticated";
BA_ "SignalType" SG_ 1320 PCIP_BrkActReqdAuth "ENM";
BA_ "SignalLongName" SG_ 1320 PCIP_BrkActReqdAuth "Post Collision Information Protected : Brake Actuation Requested Authenticated";
BA_ "SignalLongName" SG_ 1320 PCIP_NtfnEvntCntAuth "Post Collision Information Protected : Notification Event Counter Authenticated";
BA_ "SignalType" SG_ 1320 PCIP_NftnFrtImpPrtnsrSevAchAuth "ENM";
BA_ "SignalLongName" SG_ 1320 PCIP_NftnFrtImpPrtnsrSevAchAuth "Post Collision Information Protected : Notification Frontal Impact Pretensioner Severity Achieved Authenticated";
BA_ "SignalType" SG_ 1320 PCIP_MemStRclDsblReqdAuth "ENM";
BA_ "SignalLongName" SG_ 1320 PCIP_MemStRclDsblReqdAuth "Post Collision Information Protected : Memory Seat Recall Disable Requested Authenticated";
BA_ "SignalType" SG_ 1320 PCIP_IntrLgtOnReqdAuth "ENM";
BA_ "SignalLongName" SG_ 1320 PCIP_IntrLgtOnReqdAuth "Post Collision Information Protected : Interior Light On Requested Authenticated";
BA_ "SignalType" SG_ 1320 PCIP_NtfnLtSdSevAchvdAuth "ENM";
BA_ "SignalLongName" SG_ 1320 PCIP_NtfnLtSdSevAchvdAuth "Post Collision Information Protected : Notification Left Side Severity Achieved Authenticated";
BA_ "SignalType" SG_ 1320 PCIP_NtfnFrtImpStg2SevAchvdAuth "ENM";
BA_ "SignalLongName" SG_ 1320 PCIP_NtfnFrtImpStg2SevAchvdAuth "Post Collision Information Protected : Notification Frontal Impact Stage2 Severity Achieved Authenticated";
BA_ "SignalType" SG_ 1320 PCIP_NtfnFrtImpStg1SevAchvdAuth "ENM";
BA_ "SignalLongName" SG_ 1320 PCIP_NtfnFrtImpStg1SevAchvdAuth "Post Collision Information Protected : Notification Frontal Impact Stage1 Severity Achieved Authenticated";
BA_ "SignalType" SG_ 1320 PCIP_NtfnEvntStsAuth "ENM";
BA_ "SignalLongName" SG_ 1320 PCIP_NtfnEvntStsAuth "Post Collision Information Protected : Notification Event Status Authenticated";
BA_ "SignalLongName" SG_ 1320 PCIP_Filler "Post Collision Information Protected : Filler";
BA_ "SignalLongName" SG_ 1320 PCIP_ARC "Post Collision Information Protected : Alive Rolling Count";
BA_ "SignalType" SG_ 1320 PCIP_eCallReqdAuth "ENM";
BA_ "SignalLongName" SG_ 1320 PCIP_eCallReqdAuth "Post Collision Information Protected : eCall Requested Authenticated";
BA_ "SignalType" SG_ 1320 PCIP_NtfnRtSdSevAchvdAuth "ENM";
BA_ "SignalLongName" SG_ 1320 PCIP_NtfnRtSdSevAchvdAuth "Post Collision Information Protected : Notification Right Side Severity Achieved Authenticated";
BA_ "SignalType" SG_ 1320 PCIP_NtfnRrImpSevAchvdAuth "ENM";
BA_ "SignalLongName" SG_ 1320 PCIP_NtfnRrImpSevAchvdAuth "Post Collision Information Protected : Notification Rear Impact Severity Achieved Authenticated";
BA_ "SignalType" SG_ 1320 PCIP_NtfnRlOvrSevAchvdAuth "ENM";
BA_ "SignalLongName" SG_ 1320 PCIP_NtfnRlOvrSevAchvdAuth "Post Collision Information Protected : Notification Roll Over Severity Achieved Authenticated";
BA_ "SignalType" SG_ 1320 PCIP_NtfnPedtrnPrtctnSevAchAuth "ENM";
BA_ "SignalLongName" SG_ 1320 PCIP_NtfnPedtrnPrtctnSevAchAuth "Post Collision Information Protected : Notification Pedpro Severity Achieved Authenticated";
BA_ "SignalType" SG_ 1426 RtSdObjDtdAdjTrlr "ENM";
BA_ "SignalLongName" SG_ 1426 RtSdObjDtdAdjTrlr "Right Side Object Detected Adjacent Trailer";
BA_ "SignalLongName" SG_ 656 SRRLFODP_BrstGrp1_PCSM "Short Range Radar Left Front Object Detection and Processing Burst 1 Protected Counter Sync Message";
BA_ "SignalLongName" SG_ 244 SRRLFODPB2P_POTk3IDAuth "Short Range Radar Left Front Object Detection and Processing Burst 2 Protected : Pedestrian Object Track 3 ID Authenticated";
BA_ "SignalType" SG_ 244 SRRLFODPB2P_POTk3DynPrpAuth "ENM";
BA_ "SignalLongName" SG_ 244 SRRLFODPB2P_POTk3DynPrpAuth "Short Range Radar Left Front Object Detection and Processing Burst 2 Protected : Pedestrian Object Track 3 Dynamic Property Authenticated";
BA_ "SignalType" SG_ 244 SRRLFODPB2P_POTk3CnfdStsAuth "ENM";
BA_ "SignalLongName" SG_ 244 SRRLFODPB2P_POTk3CnfdStsAuth "Short Range Radar Left Front Object Detection and Processing Burst 2 Protected : Pedestrian Object Track 3 Confidence Status Authenticated";
BA_ "SignalLongName" SG_ 244 SRRLFODPB2P_BrstID "Short Range Radar Left Front Object Detection and Processing Burst 2 Protected : Burst ID";
BA_ "SignalLongName" SG_ 244 SRRLFODPB2P_POTk3InPthPotAuth "Short Range Radar Left Front Object Detection and Processing Burst 2 Protected : Pedestrian Object Track 3 In Path Potential Authenticated";
BA_ "SignalLongName" SG_ 244 SRRLFODPB2P_POTk3PoILAAuth "Short Range Radar Left Front Object Detection and Processing Burst 2 Protected : Pedestrian Object Track 3 Point of Interest Lateral Acceleration Authenticated";
BA_ "SignalType" SG_ 244 SRRLFODPB2P_POTk3MStsAuth "ENM";
BA_ "SignalLongName" SG_ 244 SRRLFODPB2P_POTk3MStsAuth "Short Range Radar Left Front Object Detection and Processing Burst 2 Protected : Pedestrian Object Track 3 Measurement Status Authenticated";
BA_ "SignalLongName" SG_ 244 SRRLFODPB2P_POTk3PoILgAAuth "Short Range Radar Left Front Object Detection and Processing Burst 2 Protected : Pedestrian Object Track 3 Point of Interest Longitudinal Acceleration Authenticated";
BA_ "SignalLongName" SG_ 244 SRRLFODPB2P_POTk3PoILgPsAuth "Short Range Radar Left Front Object Detection and Processing Burst 2 Protected : Pedestrian Object Track 3 Point of Interest Longitudinal Position Authenticated";
BA_ "SignalLongName" SG_ 244 SRRLFODPB2P_POTk3PoILgVAuth "Short Range Radar Left Front Object Detection and Processing Burst 2 Protected : Pedestrian Object Track 3 Point of Interest Longitudinal Velocity Authenticated";
BA_ "SignalLongName" SG_ 244 SRRLFODPB2P_POTk3PoILPsAuth "Short Range Radar Left Front Object Detection and Processing Burst 2 Protected : Pedestrian Object Track 3 Point of Interest Lateral Position Authenticated";
BA_ "SignalLongName" SG_ 244 SRRLFODPB2P_POTk3PoILVAuth "Short Range Radar Left Front Object Detection and Processing Burst 2 Protected : Pedestrian Object Track 3 Point of Interest Lateral Velocity Authenticated";
BA_ "SignalLongName" SG_ 244 SRRLFODPB2P_VOTk2CICOPotAuth "Short Range Radar Left Front Object Detection and Processing Burst 2 Protected : Vehicle Object Track 2 Cut In Cut Out Potential Authenticated";
BA_ "SignalType" SG_ 244 SRRLFODPB2P_POTk3TypCnfdAuth "ENM";
BA_ "SignalLongName" SG_ 244 SRRLFODPB2P_POTk3TypCnfdAuth "Short Range Radar Left Front Object Detection and Processing Burst 2 Protected : Pedestrian Object Track 3 Type Confidence Authenticated";
BA_ "SignalType" SG_ 244 SRRLFODPB2P_POTk3TypAuth "ENM";
BA_ "SignalLongName" SG_ 244 SRRLFODPB2P_POTk3TypAuth "Short Range Radar Left Front Object Detection and Processing Burst 2 Protected : Pedestrian Object Track 3 Type Authenticated";
BA_ "SignalType" SG_ 244 SRRLFODPB2P_VOTk2DynPrpStsAuth "ENM";
BA_ "SignalLongName" SG_ 244 SRRLFODPB2P_VOTk2DynPrpStsAuth "Short Range Radar Left Front Object Detection and Processing Burst 2 Protected : Vehicle Object Track 2 Dynamic Property Status Authenticated";
BA_ "SignalType" SG_ 244 SRRLFODPB2P_VOTk2DynPrpAuth "ENM";
BA_ "SignalLongName" SG_ 244 SRRLFODPB2P_VOTk2DynPrpAuth "Short Range Radar Left Front Object Detection and Processing Burst 2 Protected : Vehicle Object Track 2 Dynamic Property Authenticated";
BA_ "SignalType" SG_ 244 SRRLFODPB2P_VOTk2CnfdStsAuth "ENM";
BA_ "SignalLongName" SG_ 244 SRRLFODPB2P_VOTk2CnfdStsAuth "Short Range Radar Left Front Object Detection and Processing Burst 2 Protected : Vehicle Object Track 2 Confidence Status Authenticated";
BA_ "SignalType" SG_ 244 SRRLFODPB2P_VOTk2MStsAuth "ENM";
BA_ "SignalLongName" SG_ 244 SRRLFODPB2P_VOTk2MStsAuth "Short Range Radar Left Front Object Detection and Processing Burst 2 Protected : Vehicle Object Track 2 Measurement Status Authenticated";
BA_ "SignalLongName" SG_ 244 SRRLFODPB2P_VOTk2IDAuth "Short Range Radar Left Front Object Detection and Processing Burst 2 Protected : Vehicle Object Track 2 ID Authenticated";
BA_ "SignalLongName" SG_ 244 SRRLFODPB2P_VOTk2PoILAAuth "Short Range Radar Left Front Object Detection and Processing Burst 2 Protected : Vehicle Object Track 2 Point of Interest Lateral Acceleration Authenticated";
BA_ "SignalLongName" SG_ 244 SRRLFODPB2P_VOTk2PoILgAAuth "Short Range Radar Left Front Object Detection and Processing Burst 2 Protected : Vehicle Object Track 2 Point of Interest Longitudinal Acceleration Authenticated";
BA_ "SignalLongName" SG_ 244 SRRLFODPB2P_VOTk2PoILgPsAuth "Short Range Radar Left Front Object Detection and Processing Burst 2 Protected : Vehicle Object Track 2 Point of Interest Longitudinal Position Authenticated";
BA_ "SignalLongName" SG_ 244 SRRLFODPB2P_VOTk2PoILgPsCAuth "Short Range Radar Left Front Object Detection and Processing Burst 2 Protected : Vehicle Object Track 2 Point of Interest Longitudinal Position Covariance Authenticated";
BA_ "SignalLongName" SG_ 244 SRRLFODPB2P_VOTk2PoILgVAuth "Short Range Radar Left Front Object Detection and Processing Burst 2 Protected : Vehicle Object Track 2 Point of Interest Longitudinal Velocity Authenticated";
BA_ "SignalLongName" SG_ 244 SRRLFODPB2P_VOTk2PoILgVCAuth "Short Range Radar Left Front Object Detection and Processing Burst 2 Protected : Vehicle Object Track 2 Point of Interest Longitudinal Velocity Covariance Authenticated";
BA_ "SignalLongName" SG_ 244 SRRLFODPB2P_VOTk2PoILPsAuth "Short Range Radar Left Front Object Detection and Processing Burst 2 Protected : Vehicle Object Track 2 Point of Interest Lateral Position Authenticated";
BA_ "SignalLongName" SG_ 244 SRRLFODPB2P_VOTk2PoILPsCAuth "Short Range Radar Left Front Object Detection and Processing Burst 2 Protected : Vehicle Object Track 2 Point of Interest Lateral Position Covariance Authenticated";
BA_ "SignalLongName" SG_ 244 SRRLFODPB2P_VOTk2PoILVAuth "Short Range Radar Left Front Object Detection and Processing Burst 2 Protected : Vehicle Object Track 2 Point of Interest Lateral Velocity Authenticated";
BA_ "SignalLongName" SG_ 244 SRRLFODPB2P_VOTk2PoILVCAuth "Short Range Radar Left Front Object Detection and Processing Burst 2 Protected : Vehicle Object Track 2 Point of Interest Lateral Velocity Covariance Authenticated";
BA_ "SignalType" SG_ 244 SRRLFODPB2P_VOTk2TypCnfdAuth "ENM";
BA_ "SignalLongName" SG_ 244 SRRLFODPB2P_VOTk2TypCnfdAuth "Short Range Radar Left Front Object Detection and Processing Burst 2 Protected : Vehicle Object Track 2 Type Confidence Authenticated";
BA_ "SignalType" SG_ 244 SRRLFODPB2P_VOTk3CnfdStsAuth "ENM";
BA_ "SignalLongName" SG_ 244 SRRLFODPB2P_VOTk3CnfdStsAuth "Short Range Radar Left Front Object Detection and Processing Burst 2 Protected : Vehicle Object Track 3 Confidence Status Authenticated";
BA_ "SignalLongName" SG_ 244 SRRLFODPB2P_VOTk3CICOPotAuth "Short Range Radar Left Front Object Detection and Processing Burst 2 Protected : Vehicle Object Track 3 Cut In Cut Out Potential Authenticated";
BA_ "SignalLongName" SG_ 244 SRRLFODPB2P_VOTk3IDAuth "Short Range Radar Left Front Object Detection and Processing Burst 2 Protected : Vehicle Object Track 3 ID Authenticated";
BA_ "SignalType" SG_ 244 SRRLFODPB2P_VOTk3DynPrpStsAuth "ENM";
BA_ "SignalLongName" SG_ 244 SRRLFODPB2P_VOTk3DynPrpStsAuth "Short Range Radar Left Front Object Detection and Processing Burst 2 Protected : Vehicle Object Track 3 Dynamic Property Status Authenticated";
BA_ "SignalType" SG_ 244 SRRLFODPB2P_VOTk3DynPrpAuth "ENM";
BA_ "SignalLongName" SG_ 244 SRRLFODPB2P_VOTk3DynPrpAuth "Short Range Radar Left Front Object Detection and Processing Burst 2 Protected : Vehicle Object Track 3 Dynamic Property Authenticated";
BA_ "SignalLongName" SG_ 244 SRRLFODPB2P_VOTk3PoILAAuth "Short Range Radar Left Front Object Detection and Processing Burst 2 Protected : Vehicle Object Track 3 Point of Interest Lateral Acceleration Authenticated";
BA_ "SignalType" SG_ 244 SRRLFODPB2P_VOTk3MStsAuth "ENM";
BA_ "SignalLongName" SG_ 244 SRRLFODPB2P_VOTk3MStsAuth "Short Range Radar Left Front Object Detection and Processing Burst 2 Protected : Vehicle Object Track 3 Measurement Status Authenticated";
BA_ "SignalLongName" SG_ 244 SRRLFODPB2P_VOTk3PoILgAAuth "Short Range Radar Left Front Object Detection and Processing Burst 2 Protected : Vehicle Object Track 3 Point of Interest Longitudinal Acceleration Authenticated";
BA_ "SignalLongName" SG_ 244 SRRLFODPB2P_VOTk3PoILgPsAuth "Short Range Radar Left Front Object Detection and Processing Burst 2 Protected : Vehicle Object Track 3 Point of Interest Longitudinal Position Authenticated";
BA_ "SignalLongName" SG_ 244 SRRLFODPB2P_VOTk3PoILgPsCAuth "Short Range Radar Left Front Object Detection and Processing Burst 2 Protected : Vehicle Object Track 3 Point of Interest Longitudinal Position Covariance Authenticated";
BA_ "SignalLongName" SG_ 244 SRRLFODPB2P_VOTk3PoILgthAuth "Short Range Radar Left Front Object Detection and Processing Burst 2 Protected : Vehicle Object Track 3 Point of Interest Length Authenticated";
BA_ "SignalLongName" SG_ 244 SRRLFODPB2P_VOTk3PoILgVAuth "Short Range Radar Left Front Object Detection and Processing Burst 2 Protected : Vehicle Object Track 3 Point of Interest Longitudinal Velocity Authenticated";
BA_ "SignalLongName" SG_ 244 SRRLFODPB2P_VOTk3PoILgVCAuth "Short Range Radar Left Front Object Detection and Processing Burst 2 Protected : Vehicle Object Track 3 Point of Interest Longitudinal Velocity Covariance Authenticated";
BA_ "SignalLongName" SG_ 244 SRRLFODPB2P_VOTk3PoILPsAuth "Short Range Radar Left Front Object Detection and Processing Burst 2 Protected : Vehicle Object Track 3 Point of Interest Lateral Position Authenticated";
BA_ "SignalLongName" SG_ 244 SRRLFODPB2P_VOTk3PoILPsCAuth "Short Range Radar Left Front Object Detection and Processing Burst 2 Protected : Vehicle Object Track 3 Point of Interest Lateral Position Covariance Authenticated";
BA_ "SignalLongName" SG_ 244 SRRLFODPB2P_VOTk3PoILVAuth "Short Range Radar Left Front Object Detection and Processing Burst 2 Protected : Vehicle Object Track 3 Point of Interest Lateral Velocity Authenticated";
BA_ "SignalLongName" SG_ 244 SRRLFODPB2P_VOTk3PoILVCAuth "Short Range Radar Left Front Object Detection and Processing Burst 2 Protected : Vehicle Object Track 3 Point of Interest Lateral Velocity Covariance Authenticated";
BA_ "SignalLongName" SG_ 244 SRRLFODPB2P_VOTk4CICOPotAuth "Short Range Radar Left Front Object Detection and Processing Burst 2 Protected : Vehicle Object Track 4 Cut In Cut Out Potential Authenticated";
BA_ "SignalType" SG_ 244 SRRLFODPB2P_VOTk3TypCnfdAuth "ENM";
BA_ "SignalLongName" SG_ 244 SRRLFODPB2P_VOTk3TypCnfdAuth "Short Range Radar Left Front Object Detection and Processing Burst 2 Protected : Vehicle Object Track 3 Type Confidence Authenticated";
BA_ "SignalType" SG_ 244 SRRLFODPB2P_VOTk4DynPrpStsAuth "ENM";
BA_ "SignalLongName" SG_ 244 SRRLFODPB2P_VOTk4DynPrpStsAuth "Short Range Radar Left Front Object Detection and Processing Burst 2 Protected : Vehicle Object Track 4 Dynamic Property Status Authenticated";
BA_ "SignalType" SG_ 244 SRRLFODPB2P_VOTk4DynPrpAuth "ENM";
BA_ "SignalLongName" SG_ 244 SRRLFODPB2P_VOTk4DynPrpAuth "Short Range Radar Left Front Object Detection and Processing Burst 2 Protected : Vehicle Object Track 4 Dynamic Property Authenticated";
BA_ "SignalType" SG_ 244 SRRLFODPB2P_VOTk4CnfdStsAuth "ENM";
BA_ "SignalLongName" SG_ 244 SRRLFODPB2P_VOTk4CnfdStsAuth "Short Range Radar Left Front Object Detection and Processing Burst 2 Protected : Vehicle Object Track 4 Confidence Status Authenticated";
BA_ "SignalType" SG_ 244 SRRLFODPB2P_VOTk4MStsAuth "ENM";
BA_ "SignalLongName" SG_ 244 SRRLFODPB2P_VOTk4MStsAuth "Short Range Radar Left Front Object Detection and Processing Burst 2 Protected : Vehicle Object Track 4 Measurement Status Authenticated";
BA_ "SignalLongName" SG_ 244 SRRLFODPB2P_VOTk4IDAuth "Short Range Radar Left Front Object Detection and Processing Burst 2 Protected : Vehicle Object Track 4 ID Authenticated";
BA_ "SignalLongName" SG_ 244 SRRLFODPB2P_VOTk4PoILAAuth "Short Range Radar Left Front Object Detection and Processing Burst 2 Protected : Vehicle Object Track 4 Point of Interest Lateral Acceleration Authenticated";
BA_ "SignalLongName" SG_ 244 SRRLFODPB2P_VOTk4PoILgAAuth "Short Range Radar Left Front Object Detection and Processing Burst 2 Protected : Vehicle Object Track 4 Point of Interest Longitudinal Acceleration Authenticated";
BA_ "SignalLongName" SG_ 244 SRRLFODPB2P_VOTk4PoILgPsAuth "Short Range Radar Left Front Object Detection and Processing Burst 2 Protected : Vehicle Object Track 4 Point of Interest Longitudinal Position Authenticated";
BA_ "SignalLongName" SG_ 244 SRRLFODPB2P_VOTk4PoILgPsCAuth "Short Range Radar Left Front Object Detection and Processing Burst 2 Protected : Vehicle Object Track 4 Point of Interest Longitudinal Position Covariance Authenticated";
BA_ "SignalLongName" SG_ 244 SRRLFODPB2P_VOTk4PoILgthAuth "Short Range Radar Left Front Object Detection and Processing Burst 2 Protected : Vehicle Object Track 4 Point of Interest Length Authenticated";
BA_ "SignalLongName" SG_ 244 SRRLFODPB2P_VOTk4PoILgVAuth "Short Range Radar Left Front Object Detection and Processing Burst 2 Protected : Vehicle Object Track 4 Point of Interest Longitudinal Velocity Authenticated";
BA_ "SignalLongName" SG_ 244 SRRLFODPB2P_VOTk4PoILgVCAuth "Short Range Radar Left Front Object Detection and Processing Burst 2 Protected : Vehicle Object Track 4 Point of Interest Longitudinal Velocity Covariance Authenticated";
BA_ "SignalLongName" SG_ 244 SRRLFODPB2P_VOTk4PoILPsAuth "Short Range Radar Left Front Object Detection and Processing Burst 2 Protected : Vehicle Object Track 4 Point of Interest Lateral Position Authenticated";
BA_ "SignalLongName" SG_ 244 SRRLFODPB2P_VOTk4PoILPsCAuth "Short Range Radar Left Front Object Detection and Processing Burst 2 Protected : Vehicle Object Track 4 Point of Interest Lateral Position Covariance Authenticated";
BA_ "SignalLongName" SG_ 244 SRRLFODPB2P_VOTk4PoILVAuth "Short Range Radar Left Front Object Detection and Processing Burst 2 Protected : Vehicle Object Track 4 Point of Interest Lateral Velocity Authenticated";
BA_ "SignalLongName" SG_ 244 SRRLFODPB2P_VOTk4PoILVCAuth "Short Range Radar Left Front Object Detection and Processing Burst 2 Protected : Vehicle Object Track 4 Point of Interest Lateral Velocity Covariance Authenticated";
BA_ "SignalType" SG_ 244 SRRLFODPB2P_VOTk4TypCnfdAuth "ENM";
BA_ "SignalLongName" SG_ 244 SRRLFODPB2P_VOTk4TypCnfdAuth "Short Range Radar Left Front Object Detection and Processing Burst 2 Protected : Vehicle Object Track 4 Type Confidence Authenticated";
BA_ "SignalLongName" SG_ 244 SRRLFODPB2P_VOTk5LgthdthAuth "Short Range Radar Left Front Object Detection and Processing Burst 2 Protected : Vehicle Object Track 5 Point of Interest Length Authenticated";
BA_ "SignalLongName" SG_ 244 SRRLFODPB2P_Filler "Short Range Radar Left Front Object Detection and Processing Burst 2 Protected : Filler";
BA_ "SignalLongName" SG_ 211 SRRLFODPB3P_POTk4IDAuth "Short Range Radar Left Front Object Detection and Processing Burst 3 Protected : Pedestrian Object Track 4 ID Authenticated";
BA_ "SignalType" SG_ 211 SRRLFODPB3P_POTk4DynPrpAuth "ENM";
BA_ "SignalLongName" SG_ 211 SRRLFODPB3P_POTk4DynPrpAuth "Short Range Radar Left Front Object Detection and Processing Burst 3 Protected : Pedestrian Object Track 4 Dynamic Property Authenticated";
BA_ "SignalType" SG_ 211 SRRLFODPB3P_POTk4CnfdStsAuth "ENM";
BA_ "SignalLongName" SG_ 211 SRRLFODPB3P_POTk4CnfdStsAuth "Short Range Radar Left Front Object Detection and Processing Burst 3 Protected : Pedestrian Object Track 4 Confidence Status Authenticated";
BA_ "SignalLongName" SG_ 211 SRRLFODPB3P_BrstID "Short Range Radar Left Front Object Detection and Processing Burst 3 Protected : Burst ID";
BA_ "SignalLongName" SG_ 211 SRRLFODPB3P_POTk4InPthPotAuth "Short Range Radar Left Front Object Detection and Processing Burst 3 Protected : Pedestrian Object Track 4 In Path Potential Authenticated";
BA_ "SignalLongName" SG_ 211 SRRLFODPB3P_POTk4PoILAAuth "Short Range Radar Left Front Object Detection and Processing Burst 3 Protected : Pedestrian Object Track 4 Point of Interest Lateral Acceleration Authenticated";
BA_ "SignalType" SG_ 211 SRRLFODPB3P_POTk4MStsAuth "ENM";
BA_ "SignalLongName" SG_ 211 SRRLFODPB3P_POTk4MStsAuth "Short Range Radar Left Front Object Detection and Processing Burst 3 Protected : Pedestrian Object Track 4 Measurement Status Authenticated";
BA_ "SignalLongName" SG_ 211 SRRLFODPB3P_POTk4PoILgAAuth "Short Range Radar Left Front Object Detection and Processing Burst 3 Protected : Pedestrian Object Track 4 Point of Interest Longitudinal Acceleration Authenticated";
BA_ "SignalLongName" SG_ 211 SRRLFODPB3P_POTk4PoILgPsAuth "Short Range Radar Left Front Object Detection and Processing Burst 3 Protected : Pedestrian Object Track 4 Point of Interest Longitudinal Position Authenticated";
BA_ "SignalLongName" SG_ 211 SRRLFODPB3P_POTk4PoILgVAuth "Short Range Radar Left Front Object Detection and Processing Burst 3 Protected : Pedestrian Object Track 4 Point of Interest Longitudinal Velocity Authenticated";
BA_ "SignalLongName" SG_ 211 SRRLFODPB3P_POTk4PoILPsAuth "Short Range Radar Left Front Object Detection and Processing Burst 3 Protected : Pedestrian Object Track 4 Point of Interest Lateral Position Authenticated";
BA_ "SignalLongName" SG_ 211 SRRLFODPB3P_POTk4PoILVAuth "Short Range Radar Left Front Object Detection and Processing Burst 3 Protected : Pedestrian Object Track 4 Point of Interest Lateral Velocity Authenticated";
BA_ "SignalLongName" SG_ 211 SRRLFODPB3P_VOTk5CICOPotAuth "Short Range Radar Left Front Object Detection and Processing Burst 3 Protected : Vehicle Object Track 5 Cut In Cut Out Potential Authenticated";
BA_ "SignalType" SG_ 211 SRRLFODPB3P_POTk4TypCnfdAuth "ENM";
BA_ "SignalLongName" SG_ 211 SRRLFODPB3P_POTk4TypCnfdAuth "Short Range Radar Left Front Object Detection and Processing Burst 3 Protected : Pedestrian Object Track 4 Type Confidence Authenticated";
BA_ "SignalType" SG_ 211 SRRLFODPB3P_POTk4TypAuth "ENM";
BA_ "SignalLongName" SG_ 211 SRRLFODPB3P_POTk4TypAuth "Short Range Radar Left Front Object Detection and Processing Burst 3 Protected : Pedestrian Object Track 4 Type Authenticated";
BA_ "SignalType" SG_ 211 SRRLFODPB3P_VOTk5DynPrpStsAuth "ENM";
BA_ "SignalLongName" SG_ 211 SRRLFODPB3P_VOTk5DynPrpStsAuth "Short Range Radar Left Front Object Detection and Processing Burst 3 Protected : Vehicle Object Track 5 Dynamic Property Status Authenticated";
BA_ "SignalType" SG_ 211 SRRLFODPB3P_VOTk5DynPrpAuth "ENM";
BA_ "SignalLongName" SG_ 211 SRRLFODPB3P_VOTk5DynPrpAuth "Short Range Radar Left Front Object Detection and Processing Burst 3 Protected : Vehicle Object Track 5 Dynamic Property Authenticated";
BA_ "SignalType" SG_ 211 SRRLFODPB3P_VOTk5CnfdStsAuth "ENM";
BA_ "SignalLongName" SG_ 211 SRRLFODPB3P_VOTk5CnfdStsAuth "Short Range Radar Left Front Object Detection and Processing Burst 3 Protected : Vehicle Object Track 5 Confidence Status Authenticated";
BA_ "SignalType" SG_ 211 SRRLFODPB3P_VOTk5MStsAuth "ENM";
BA_ "SignalLongName" SG_ 211 SRRLFODPB3P_VOTk5MStsAuth "Short Range Radar Left Front Object Detection and Processing Burst 3 Protected : Vehicle Object Track 5 Measurement Status Authenticated";
BA_ "SignalLongName" SG_ 211 SRRLFODPB3P_VOTk5IDAuth "Short Range Radar Left Front Object Detection and Processing Burst 3 Protected : Vehicle Object Track 5 ID Authenticated";
BA_ "SignalLongName" SG_ 211 SRRLFODPB3P_VOTk5PoILAAuth "Short Range Radar Left Front Object Detection and Processing Burst 3 Protected : Vehicle Object Track 5 Point of Interest Lateral Acceleration Authenticated";
BA_ "SignalLongName" SG_ 211 SRRLFODPB3P_VOTk5PoILgAAuth "Short Range Radar Left Front Object Detection and Processing Burst 3 Protected : Vehicle Object Track 5 Point of Interest Longitudinal Acceleration Authenticated";
BA_ "SignalLongName" SG_ 211 SRRLFODPB3P_VOTk5PoILgPsAuth "Short Range Radar Left Front Object Detection and Processing Burst 3 Protected : Vehicle Object Track 5 Point of Interest Longitudinal Position Authenticated";
BA_ "SignalLongName" SG_ 211 SRRLFODPB3P_VOTk5PoILgPsCAuth "Short Range Radar Left Front Object Detection and Processing Burst 3 Protected : Vehicle Object Track 5 Point of Interest Longitudinal Position Covariance Authenticated";
BA_ "SignalLongName" SG_ 211 SRRLFODPB3P_VOTk5PoILgVAuth "Short Range Radar Left Front Object Detection and Processing Burst 3 Protected : Vehicle Object Track 5 Point of Interest Longitudinal Velocity Authenticated";
BA_ "SignalLongName" SG_ 211 SRRLFODPB3P_VOTk5PoILgVCAuth "Short Range Radar Left Front Object Detection and Processing Burst 3 Protected : Vehicle Object Track 5 Point of Interest Longitudinal Velocity Covariance Authenticated";
BA_ "SignalLongName" SG_ 211 SRRLFODPB3P_VOTk5PoILPsAuth "Short Range Radar Left Front Object Detection and Processing Burst 3 Protected : Vehicle Object Track 5 Point of Interest Lateral Position Authenticated";
BA_ "SignalLongName" SG_ 211 SRRLFODPB3P_VOTk5PoILPsCAuth "Short Range Radar Left Front Object Detection and Processing Burst 3 Protected : Vehicle Object Track 5 Point of Interest Lateral Position Covariance Authenticated";
BA_ "SignalLongName" SG_ 211 SRRLFODPB3P_VOTk5PoILVAuth "Short Range Radar Left Front Object Detection and Processing Burst 3 Protected : Vehicle Object Track 5 Point of Interest Lateral Velocity Authenticated";
BA_ "SignalLongName" SG_ 211 SRRLFODPB3P_VOTk5PoILVCAuth "Short Range Radar Left Front Object Detection and Processing Burst 3 Protected : Vehicle Object Track 5 Point of Interest Lateral Velocity Covariance Authenticated";
BA_ "SignalType" SG_ 211 SRRLFODPB3P_VOTk5TypCnfdAuth "ENM";
BA_ "SignalLongName" SG_ 211 SRRLFODPB3P_VOTk5TypCnfdAuth "Short Range Radar Left Front Object Detection and Processing Burst 3 Protected : Vehicle Object Track 5 Type Confidence Authenticated";
BA_ "SignalType" SG_ 211 SRRLFODPB3P_VOTk6CnfdStsAuth "ENM";
BA_ "SignalLongName" SG_ 211 SRRLFODPB3P_VOTk6CnfdStsAuth "Short Range Radar Left Front Object Detection and Processing Burst 3 Protected : Vehicle Object Track 6 Confidence Status Authenticated";
BA_ "SignalLongName" SG_ 211 SRRLFODPB3P_VOTk6CICOPotAuth "Short Range Radar Left Front Object Detection and Processing Burst 3 Protected : Vehicle Object Track 6 Cut In Cut Out Potential Authenticated";
BA_ "SignalLongName" SG_ 211 SRRLFODPB3P_VOTk6IDAuth "Short Range Radar Left Front Object Detection and Processing Burst 3 Protected : Vehicle Object Track 6 ID Authenticated";
BA_ "SignalType" SG_ 211 SRRLFODPB3P_VOTk6DynPrpStsAuth "ENM";
BA_ "SignalLongName" SG_ 211 SRRLFODPB3P_VOTk6DynPrpStsAuth "Short Range Radar Left Front Object Detection and Processing Burst 3 Protected : Vehicle Object Track 6 Dynamic Property Status Authenticated";
BA_ "SignalType" SG_ 211 SRRLFODPB3P_VOTk6DynPrpAuth "ENM";
BA_ "SignalLongName" SG_ 211 SRRLFODPB3P_VOTk6DynPrpAuth "Short Range Radar Left Front Object Detection and Processing Burst 3 Protected : Vehicle Object Track 6 Dynamic Property Authenticated";
BA_ "SignalLongName" SG_ 211 SRRLFODPB3P_VOTk6PoILAAuth "Short Range Radar Left Front Object Detection and Processing Burst 3 Protected : Vehicle Object Track 6 Point of Interest Lateral Acceleration Authenticated";
BA_ "SignalType" SG_ 211 SRRLFODPB3P_VOTk6MStsAuth "ENM";
BA_ "SignalLongName" SG_ 211 SRRLFODPB3P_VOTk6MStsAuth "Short Range Radar Left Front Object Detection and Processing Burst 3 Protected : Vehicle Object Track 6 Measurement Status Authenticated";
BA_ "SignalLongName" SG_ 211 SRRLFODPB3P_VOTk6PoILgAAuth "Short Range Radar Left Front Object Detection and Processing Burst 3 Protected : Vehicle Object Track 6 Point of Interest Longitudinal Acceleration Authenticated";
BA_ "SignalLongName" SG_ 211 SRRLFODPB3P_VOTk6PoILgPsAuth "Short Range Radar Left Front Object Detection and Processing Burst 3 Protected : Vehicle Object Track 6 Point of Interest Longitudinal Position Authenticated";
BA_ "SignalLongName" SG_ 211 SRRLFODPB3P_VOTk6PoILgPsCAuth "Short Range Radar Left Front Object Detection and Processing Burst 3 Protected : Vehicle Object Track 6 Point of Interest Longitudinal Position Covariance Authenticated";
BA_ "SignalLongName" SG_ 211 SRRLFODPB3P_VOTk6PoILgthAuth "Short Range Radar Left Front Object Detection and Processing Burst 3 Protected : Vehicle Object Track 6 Point of Interest Length Authenticated";
BA_ "SignalLongName" SG_ 211 SRRLFODPB3P_VOTk6PoILgVAuth "Short Range Radar Left Front Object Detection and Processing Burst 3 Protected : Vehicle Object Track 6 Point of Interest Longitudinal Velocity Authenticated";
BA_ "SignalLongName" SG_ 211 SRRLFODPB3P_VOTk6PoILgVCAuth "Short Range Radar Left Front Object Detection and Processing Burst 3 Protected : Vehicle Object Track 6 Point of Interest Longitudinal Velocity Covariance Authenticated";
BA_ "SignalLongName" SG_ 211 SRRLFODPB3P_VOTk6PoILPsAuth "Short Range Radar Left Front Object Detection and Processing Burst 3 Protected : Vehicle Object Track 6 Point of Interest Lateral Position Authenticated";
BA_ "SignalLongName" SG_ 211 SRRLFODPB3P_VOTk6PoILPsCAuth "Short Range Radar Left Front Object Detection and Processing Burst 3 Protected : Vehicle Object Track 6 Point of Interest Lateral Position Covariance Authenticated";
BA_ "SignalLongName" SG_ 211 SRRLFODPB3P_VOTk6PoILVAuth "Short Range Radar Left Front Object Detection and Processing Burst 3 Protected : Vehicle Object Track 6 Point of Interest Lateral Velocity Authenticated";
BA_ "SignalLongName" SG_ 211 SRRLFODPB3P_VOTk6PoILVCAuth "Short Range Radar Left Front Object Detection and Processing Burst 3 Protected : Vehicle Object Track 6 Point of Interest Lateral Velocity Covariance Authenticated";
BA_ "SignalLongName" SG_ 211 SRRLFODPB3P_VOTk7CICOPotAuth "Short Range Radar Left Front Object Detection and Processing Burst 3 Protected : Vehicle Object Track 7 Cut In Cut Out Potential Authenticated";
BA_ "SignalType" SG_ 211 SRRLFODPB3P_VOTk6TypCnfdAuth "ENM";
BA_ "SignalLongName" SG_ 211 SRRLFODPB3P_VOTk6TypCnfdAuth "Short Range Radar Left Front Object Detection and Processing Burst 3 Protected : Vehicle Object Track 6 Type Confidence Authenticated";
BA_ "SignalType" SG_ 211 SRRLFODPB3P_VOTk7DynPrpStsAuth "ENM";
BA_ "SignalLongName" SG_ 211 SRRLFODPB3P_VOTk7DynPrpStsAuth "Short Range Radar Left Front Object Detection and Processing Burst 3 Protected : Vehicle Object Track 7 Dynamic Property Status Authenticated";
BA_ "SignalType" SG_ 211 SRRLFODPB3P_VOTk7DynPrpAuth "ENM";
BA_ "SignalLongName" SG_ 211 SRRLFODPB3P_VOTk7DynPrpAuth "Short Range Radar Left Front Object Detection and Processing Burst 3 Protected : Vehicle Object Track 7 Dynamic Property Authenticated";
BA_ "SignalType" SG_ 211 SRRLFODPB3P_VOTk7CnfdStsAuth "ENM";
BA_ "SignalLongName" SG_ 211 SRRLFODPB3P_VOTk7CnfdStsAuth "Short Range Radar Left Front Object Detection and Processing Burst 3 Protected : Vehicle Object Track 7 Confidence Status Authenticated";
BA_ "SignalType" SG_ 211 SRRLFODPB3P_VOTk7MStsAuth "ENM";
BA_ "SignalLongName" SG_ 211 SRRLFODPB3P_VOTk7MStsAuth "Short Range Radar Left Front Object Detection and Processing Burst 3 Protected : Vehicle Object Track 7 Measurement Status Authenticated";
BA_ "SignalLongName" SG_ 211 SRRLFODPB3P_VOTk7IDAuth "Short Range Radar Left Front Object Detection and Processing Burst 3 Protected : Vehicle Object Track 7 ID Authenticated";
BA_ "SignalLongName" SG_ 211 SRRLFODPB3P_VOTk7PoILAAuth "Short Range Radar Left Front Object Detection and Processing Burst 3 Protected : Vehicle Object Track 7 Point of Interest Lateral Acceleration Authenticated";
BA_ "SignalLongName" SG_ 211 SRRLFODPB3P_VOTk7PoILgAAuth "Short Range Radar Left Front Object Detection and Processing Burst 3 Protected : Vehicle Object Track 7 Point of Interest Longitudinal Acceleration Authenticated";
BA_ "SignalLongName" SG_ 211 SRRLFODPB3P_VOTk7PoILgPsAuth "Short Range Radar Left Front Object Detection and Processing Burst 3 Protected : Vehicle Object Track 7 Point of Interest Longitudinal Position Authenticated";
BA_ "SignalLongName" SG_ 211 SRRLFODPB3P_VOTk7PoILgPsCAuth "Short Range Radar Left Front Object Detection and Processing Burst 3 Protected : Vehicle Object Track 7 Point of Interest Longitudinal Position Covariance Authenticated";
BA_ "SignalLongName" SG_ 211 SRRLFODPB3P_VOTk7PoILgthAuth "Short Range Radar Left Front Object Detection and Processing Burst 3 Protected : Vehicle Object Track 7 Point of Interest Length Authenticated";
BA_ "SignalLongName" SG_ 211 SRRLFODPB3P_VOTk7PoILgVAuth "Short Range Radar Left Front Object Detection and Processing Burst 3 Protected : Vehicle Object Track 7 Point of Interest Longitudinal Velocity Authenticated";
BA_ "SignalLongName" SG_ 211 SRRLFODPB3P_VOTk7PoILgVCAuth "Short Range Radar Left Front Object Detection and Processing Burst 3 Protected : Vehicle Object Track 7 Point of Interest Longitudinal Velocity Covariance Authenticated";
BA_ "SignalLongName" SG_ 211 SRRLFODPB3P_VOTk7PoILPsAuth "Short Range Radar Left Front Object Detection and Processing Burst 3 Protected : Vehicle Object Track 7 Point of Interest Lateral Position Authenticated";
BA_ "SignalLongName" SG_ 211 SRRLFODPB3P_VOTk7PoILPsCAuth "Short Range Radar Left Front Object Detection and Processing Burst 3 Protected : Vehicle Object Track 7 Point of Interest Lateral Position Covariance Authenticated";
BA_ "SignalLongName" SG_ 211 SRRLFODPB3P_VOTk7PoILVAuth "Short Range Radar Left Front Object Detection and Processing Burst 3 Protected : Vehicle Object Track 7 Point of Interest Lateral Velocity Authenticated";
BA_ "SignalLongName" SG_ 211 SRRLFODPB3P_VOTk7PoILVCAuth "Short Range Radar Left Front Object Detection and Processing Burst 3 Protected : Vehicle Object Track 7 Point of Interest Lateral Velocity Covariance Authenticated";
BA_ "SignalType" SG_ 211 SRRLFODPB3P_VOTk7TypCnfdAuth "ENM";
BA_ "SignalLongName" SG_ 211 SRRLFODPB3P_VOTk7TypCnfdAuth "Short Range Radar Left Front Object Detection and Processing Burst 3 Protected : Vehicle Object Track 7 Type Confidence Authenticated";
BA_ "SignalLongName" SG_ 211 SRRLFODPB3P_VOTk8PoILgthAuth "Short Range Radar Left Front Object Detection and Processing Burst 3 Protected : Vehicle Object Track 8 Point of Interest Length Authenticated";
BA_ "SignalLongName" SG_ 211 SRRLFODPB3P_Filler "Short Range Radar Left Front Object Detection and Processing Burst 3 Protected : Filler";
BA_ "SignalLongName" SG_ 245 SRRLFODPB4P_POTk5IDAuth "Short Range Radar Left Front Object Detection and Processing Burst 4 Protected : Pedestrian Object Track 5 ID Authenticated";
BA_ "SignalType" SG_ 245 SRRLFODPB4P_POTk5DynPrpAuth "ENM";
BA_ "SignalLongName" SG_ 245 SRRLFODPB4P_POTk5DynPrpAuth "Short Range Radar Left Front Object Detection and Processing Burst 4 Protected : Pedestrian Object Track 5 Dynamic Property Authenticated";
BA_ "SignalType" SG_ 245 SRRLFODPB4P_POTk5CnfdStsAuth "ENM";
BA_ "SignalLongName" SG_ 245 SRRLFODPB4P_POTk5CnfdStsAuth "Short Range Radar Left Front Object Detection and Processing Burst 4 Protected : Pedestrian Object Track 5 Confidence Status Authenticated";
BA_ "SignalLongName" SG_ 245 SRRLFODPB4P_BrstID "Short Range Radar Left Front Object Detection and Processing Burst 4 Protected : Burst ID";
BA_ "SignalLongName" SG_ 245 SRRLFODPB4P_POTk5InPthPotAuth "Short Range Radar Left Front Object Detection and Processing Burst 4 Protected : Pedestrian Object Track 5 In Path Potential Authenticated";
BA_ "SignalLongName" SG_ 245 SRRLFODPB4P_POTk5PoILAAuth "Short Range Radar Left Front Object Detection and Processing Burst 4 Protected : Pedestrian Object Track 5 Point of Interest Lateral Acceleration Authenticated";
BA_ "SignalType" SG_ 245 SRRLFODPB4P_POTk5MStsAuth "ENM";
BA_ "SignalLongName" SG_ 245 SRRLFODPB4P_POTk5MStsAuth "Short Range Radar Left Front Object Detection and Processing Burst 4 Protected : Pedestrian Object Track 5 Measurement Status Authenticated";
BA_ "SignalLongName" SG_ 245 SRRLFODPB4P_POTk5PoILgAAuth "Short Range Radar Left Front Object Detection and Processing Burst 4 Protected : Pedestrian Object Track 5 Point of Interest Longitudinal Acceleration Authenticated";
BA_ "SignalLongName" SG_ 245 SRRLFODPB4P_POTk5PoILgPsAuth "Short Range Radar Left Front Object Detection and Processing Burst 4 Protected : Pedestrian Object Track 5 Point of Interest Longitudinal Position Authenticated";
BA_ "SignalLongName" SG_ 245 SRRLFODPB4P_POTk5PoILgVAuth "Short Range Radar Left Front Object Detection and Processing Burst 4 Protected : Pedestrian Object Track 5 Point of Interest Longitudinal Velocity Authenticated";
BA_ "SignalLongName" SG_ 245 SRRLFODPB4P_POTk5PoILPsAuth "Short Range Radar Left Front Object Detection and Processing Burst 4 Protected : Pedestrian Object Track 5 Point of Interest Lateral Position Authenticated";
BA_ "SignalLongName" SG_ 245 SRRLFODPB4P_POTk5PoILVAuth "Short Range Radar Left Front Object Detection and Processing Burst 4 Protected : Pedestrian Object Track 5 Point of Interest Lateral Velocity Authenticated";
BA_ "SignalLongName" SG_ 245 SRRLFODPB4P_VOTk10CICOPotAuth "Short Range Radar Left Front Object Detection and Processing Burst 4 Protected : Vehicle Object Track 10 Cut In Cut Out Potential Authenticated";
BA_ "SignalType" SG_ 245 SRRLFODPB4P_POTk5TypCnfdAuth "ENM";
BA_ "SignalLongName" SG_ 245 SRRLFODPB4P_POTk5TypCnfdAuth "Short Range Radar Left Front Object Detection and Processing Burst 4 Protected : Pedestrian Object Track 5 Type Confidence Authenticated";
BA_ "SignalType" SG_ 245 SRRLFODPB4P_POTk5TypAuth "ENM";
BA_ "SignalLongName" SG_ 245 SRRLFODPB4P_POTk5TypAuth "Short Range Radar Left Front Object Detection and Processing Burst 4 Protected : Pedestrian Object Track 5 Type Authenticated";
BA_ "SignalType" SG_ 245 SRRLFODPB4P_VOTk10DynPrpStsAuth "ENM";
BA_ "SignalLongName" SG_ 245 SRRLFODPB4P_VOTk10DynPrpStsAuth "Short Range Radar Left Front Object Detection and Processing Burst 4 Protected : Vehicle Object Track 10 Dynamic Property Status Authenticated";
BA_ "SignalType" SG_ 245 SRRLFODPB4P_VOTk10DynPrpAuth "ENM";
BA_ "SignalLongName" SG_ 245 SRRLFODPB4P_VOTk10DynPrpAuth "Short Range Radar Left Front Object Detection and Processing Burst 4 Protected : Vehicle Object Track 10 Dynamic Property Authenticated";
BA_ "SignalType" SG_ 245 SRRLFODPB4P_VOTk10CnfdStsAuth "ENM";
BA_ "SignalLongName" SG_ 245 SRRLFODPB4P_VOTk10CnfdStsAuth "Short Range Radar Left Front Object Detection and Processing Burst 4 Protected : Vehicle Object Track 10 Confidence Status Authenticated";
BA_ "SignalType" SG_ 245 SRRLFODPB4P_VOTk10MStsAuth "ENM";
BA_ "SignalLongName" SG_ 245 SRRLFODPB4P_VOTk10MStsAuth "Short Range Radar Left Front Object Detection and Processing Burst 4 Protected : Vehicle Object Track 10 Measurement Status Authenticated";
BA_ "SignalLongName" SG_ 245 SRRLFODPB4P_VOTk10IDAuth "Short Range Radar Left Front Object Detection and Processing Burst 4 Protected : Vehicle Object Track 10 ID Authenticated";
BA_ "SignalLongName" SG_ 245 SRRLFODPB4P_VOTk10PoILAAuth "Short Range Radar Left Front Object Detection and Processing Burst 4 Protected : Vehicle Object Track 10 Point of Interest Lateral Acceleration Authenticated";
BA_ "SignalLongName" SG_ 245 SRRLFODPB4P_VOTk10PoILgAAuth "Short Range Radar Left Front Object Detection and Processing Burst 4 Protected : Vehicle Object Track 10 Point of Interest Longitudinal Acceleration Authenticated";
BA_ "SignalLongName" SG_ 245 SRRLFODPB4P_VOTk10PoILgPsAuth "Short Range Radar Left Front Object Detection and Processing Burst 4 Protected : Vehicle Object Track 10 Point of Interest Longitudinal Position Authenticated";
BA_ "SignalLongName" SG_ 245 SRRLFODPB4P_VOTk10PoILgPsCAuth "Short Range Radar Left Front Object Detection and Processing Burst 4 Protected : Vehicle Object Track 10 Point of Interest Longitudinal Position Covariance Authenticated";
BA_ "SignalLongName" SG_ 245 SRRLFODPB4P_VOTk10PoILgthAuth "Short Range Radar Left Front Object Detection and Processing Burst 4 Protected : Vehicle Object Track 10 Point of Interest Length Authenticated";
BA_ "SignalLongName" SG_ 245 SRRLFODPB4P_VOTk10PoILgVAuth "Short Range Radar Left Front Object Detection and Processing Burst 4 Protected : Vehicle Object Track 10 Point of Interest Longitudinal Velocity Authenticated";
BA_ "SignalLongName" SG_ 245 SRRLFODPB4P_VOTk10PoILgVCAuth "Short Range Radar Left Front Object Detection and Processing Burst 4 Protected : Vehicle Object Track 10 Point of Interest Longitudinal Velocity Covariance Authenticated";
BA_ "SignalLongName" SG_ 245 SRRLFODPB4P_VOTk10PoILPsAuth "Short Range Radar Left Front Object Detection and Processing Burst 4 Protected : Vehicle Object Track 10 Point of Interest Lateral Position Authenticated";
BA_ "SignalLongName" SG_ 245 SRRLFODPB4P_VOTk10PoILPsCAuth "Short Range Radar Left Front Object Detection and Processing Burst 4 Protected : Vehicle Object Track 10 Point of Interest Lateral Position Covariance Authenticated";
BA_ "SignalLongName" SG_ 245 SRRLFODPB4P_VOTk10PoILVAuth "Short Range Radar Left Front Object Detection and Processing Burst 4 Protected : Vehicle Object Track 10 Point of Interest Lateral Velocity Authenticated";
BA_ "SignalLongName" SG_ 245 SRRLFODPB4P_VOTk10PoILVCAuth "Short Range Radar Left Front Object Detection and Processing Burst 4 Protected : Vehicle Object Track 10 Point of Interest Lateral Velocity Covariance Authenticated";
BA_ "SignalType" SG_ 245 SRRLFODPB4P_VOTk10TypCnfdAuth "ENM";
BA_ "SignalLongName" SG_ 245 SRRLFODPB4P_VOTk10TypCnfdAuth "Short Range Radar Left Front Object Detection and Processing Burst 4 Protected : Vehicle Object Track 10 Type Confidence Authenticated";
BA_ "SignalType" SG_ 245 SRRLFODPB4P_VOTk8CnfdStsAuth "ENM";
BA_ "SignalLongName" SG_ 245 SRRLFODPB4P_VOTk8CnfdStsAuth "Short Range Radar Left Front Object Detection and Processing Burst 4 Protected : Vehicle Object Track 8 Confidence Status Authenticated";
BA_ "SignalLongName" SG_ 245 SRRLFODPB4P_VOTk8CICOPotAuth "Short Range Radar Left Front Object Detection and Processing Burst 4 Protected : Vehicle Object Track 8 Cut In Cut Out Potential Authenticated";
BA_ "SignalLongName" SG_ 245 SRRLFODPB4P_VOTk8IDAuth "Short Range Radar Left Front Object Detection and Processing Burst 4 Protected : Vehicle Object Track 8 ID Authenticated";
BA_ "SignalType" SG_ 245 SRRLFODPB4P_VOTk8DynPrpStsAuth "ENM";
BA_ "SignalLongName" SG_ 245 SRRLFODPB4P_VOTk8DynPrpStsAuth "Short Range Radar Left Front Object Detection and Processing Burst 4 Protected : Vehicle Object Track 8 Dynamic Property Status Authenticated";
BA_ "SignalType" SG_ 245 SRRLFODPB4P_VOTk8DynPrpAuth "ENM";
BA_ "SignalLongName" SG_ 245 SRRLFODPB4P_VOTk8DynPrpAuth "Short Range Radar Left Front Object Detection and Processing Burst 4 Protected : Vehicle Object Track 8 Dynamic Property Authenticated";
BA_ "SignalLongName" SG_ 245 SRRLFODPB4P_VOTk8PoILAAuth "Short Range Radar Left Front Object Detection and Processing Burst 4 Protected : Vehicle Object Track 8 Point of Interest Lateral Acceleration Authenticated";
BA_ "SignalType" SG_ 245 SRRLFODPB4P_VOTk8MStsAuth "ENM";
BA_ "SignalLongName" SG_ 245 SRRLFODPB4P_VOTk8MStsAuth "Short Range Radar Left Front Object Detection and Processing Burst 4 Protected : Vehicle Object Track 8 Measurement Status Authenticated";
BA_ "SignalLongName" SG_ 245 SRRLFODPB4P_VOTk8PoILgAAuth "Short Range Radar Left Front Object Detection and Processing Burst 4 Protected : Vehicle Object Track 8 Point of Interest Longitudinal Acceleration Authenticated";
BA_ "SignalLongName" SG_ 245 SRRLFODPB4P_VOTk8PoILgPsAuth "Short Range Radar Left Front Object Detection and Processing Burst 4 Protected : Vehicle Object Track 8 Point of Interest Longitudinal Position Authenticated";
BA_ "SignalLongName" SG_ 245 SRRLFODPB4P_VOTk8PoILgPsCAuth "Short Range Radar Left Front Object Detection and Processing Burst 4 Protected : Vehicle Object Track 8 Point of Interest Longitudinal Position Covariance Authenticated";
BA_ "SignalLongName" SG_ 245 SRRLFODPB4P_VOTk8PoILgVAuth "Short Range Radar Left Front Object Detection and Processing Burst 4 Protected : Vehicle Object Track 8 Point of Interest Longitudinal Velocity Authenticated";
BA_ "SignalLongName" SG_ 245 SRRLFODPB4P_VOTk8PoILgVCAuth "Short Range Radar Left Front Object Detection and Processing Burst 4 Protected : Vehicle Object Track 8 Point of Interest Longitudinal Velocity Covariance Authenticated";
BA_ "SignalLongName" SG_ 245 SRRLFODPB4P_VOTk8PoILPsAuth "Short Range Radar Left Front Object Detection and Processing Burst 4 Protected : Vehicle Object Track 8 Point of Interest Lateral Position Authenticated";
BA_ "SignalLongName" SG_ 245 SRRLFODPB4P_VOTk8PoILPsCAuth "Short Range Radar Left Front Object Detection and Processing Burst 4 Protected : Vehicle Object Track 8 Point of Interest Lateral Position Covariance Authenticated";
BA_ "SignalLongName" SG_ 245 SRRLFODPB4P_VOTk8PoILVAuth "Short Range Radar Left Front Object Detection and Processing Burst 4 Protected : Vehicle Object Track 8 Point of Interest Lateral Velocity Authenticated";
BA_ "SignalLongName" SG_ 245 SRRLFODPB4P_VOTk8PoILVCAuth "Short Range Radar Left Front Object Detection and Processing Burst 4 Protected : Vehicle Object Track 8 Point of Interest Lateral Velocity Covariance Authenticated";
BA_ "SignalLongName" SG_ 245 SRRLFODPB4P_VOTk9CICOPotAuth "Short Range Radar Left Front Object Detection and Processing Burst 4 Protected : Vehicle Object Track 9 Cut In Cut Out Potential Authenticated";
BA_ "SignalType" SG_ 245 SRRLFODPB4P_VOTk8TypCnfdAuth "ENM";
BA_ "SignalLongName" SG_ 245 SRRLFODPB4P_VOTk8TypCnfdAuth "Short Range Radar Left Front Object Detection and Processing Burst 4 Protected : Vehicle Object Track 8 Type Confidence Authenticated";
BA_ "SignalType" SG_ 245 SRRLFODPB4P_VOTk9DynPrpStsAuth "ENM";
BA_ "SignalLongName" SG_ 245 SRRLFODPB4P_VOTk9DynPrpStsAuth "Short Range Radar Left Front Object Detection and Processing Burst 4 Protected : Vehicle Object Track 9 Dynamic Property Status Authenticated";
BA_ "SignalType" SG_ 245 SRRLFODPB4P_VOTk9DynPrpAuth "ENM";
BA_ "SignalLongName" SG_ 245 SRRLFODPB4P_VOTk9DynPrpAuth "Short Range Radar Left Front Object Detection and Processing Burst 4 Protected : Vehicle Object Track 9 Dynamic Property Authenticated";
BA_ "SignalType" SG_ 245 SRRLFODPB4P_VOTk9CnfdStsAuth "ENM";
BA_ "SignalLongName" SG_ 245 SRRLFODPB4P_VOTk9CnfdStsAuth "Short Range Radar Left Front Object Detection and Processing Burst 4 Protected : Vehicle Object Track 9 Confidence Status Authenticated";
BA_ "SignalType" SG_ 245 SRRLFODPB4P_VOTk9MStsAuth "ENM";
BA_ "SignalLongName" SG_ 245 SRRLFODPB4P_VOTk9MStsAuth "Short Range Radar Left Front Object Detection and Processing Burst 4 Protected : Vehicle Object Track 9 Measurement Status Authenticated";
BA_ "SignalLongName" SG_ 245 SRRLFODPB4P_VOTk9IDAuth "Short Range Radar Left Front Object Detection and Processing Burst 4 Protected : Vehicle Object Track 9 ID Authenticated";
BA_ "SignalLongName" SG_ 245 SRRLFODPB4P_VOTk9PoILAAuth "Short Range Radar Left Front Object Detection and Processing Burst 4 Protected : Vehicle Object Track 9 Point of Interest Lateral Acceleration Authenticated";
BA_ "SignalLongName" SG_ 245 SRRLFODPB4P_VOTk9PoILgAAuth "Short Range Radar Left Front Object Detection and Processing Burst 4 Protected : Vehicle Object Track 9 Point of Interest Longitudinal Acceleration Authenticated";
BA_ "SignalLongName" SG_ 245 SRRLFODPB4P_VOTk9PoILgPsAuth "Short Range Radar Left Front Object Detection and Processing Burst 4 Protected : Vehicle Object Track 9 Point of Interest Longitudinal Position Authenticated";
BA_ "SignalLongName" SG_ 245 SRRLFODPB4P_VOTk9PoILgPsCAuth "Short Range Radar Left Front Object Detection and Processing Burst 4 Protected : Vehicle Object Track 9 Point of Interest Longitudinal Position Covariance Authenticated";
BA_ "SignalLongName" SG_ 245 SRRLFODPB4P_VOTk9PoILgthAuth "Short Range Radar Left Front Object Detection and Processing Burst 4 Protected : Vehicle Object Track 9 Point of Interest Length Authenticated";
BA_ "SignalLongName" SG_ 245 SRRLFODPB4P_VOTk9PoILgVAuth "Short Range Radar Left Front Object Detection and Processing Burst 4 Protected : Vehicle Object Track 9 Point of Interest Longitudinal Velocity Authenticated";
BA_ "SignalLongName" SG_ 245 SRRLFODPB4P_VOTk9PoILgVCAuth "Short Range Radar Left Front Object Detection and Processing Burst 4 Protected : Vehicle Object Track 9 Point of Interest Longitudinal Velocity Covariance Authenticated";
BA_ "SignalLongName" SG_ 245 SRRLFODPB4P_VOTk9PoILPsAuth "Short Range Radar Left Front Object Detection and Processing Burst 4 Protected : Vehicle Object Track 9 Point of Interest Lateral Position Authenticated";
BA_ "SignalLongName" SG_ 245 SRRLFODPB4P_VOTk9PoILPsCAuth "Short Range Radar Left Front Object Detection and Processing Burst 4 Protected : Vehicle Object Track 9 Point of Interest Lateral Position Covariance Authenticated";
BA_ "SignalLongName" SG_ 245 SRRLFODPB4P_VOTk9PoILVAuth "Short Range Radar Left Front Object Detection and Processing Burst 4 Protected : Vehicle Object Track 9 Point of Interest Lateral Velocity Authenticated";
BA_ "SignalLongName" SG_ 245 SRRLFODPB4P_VOTk9PoILVCAuth "Short Range Radar Left Front Object Detection and Processing Burst 4 Protected : Vehicle Object Track 9 Point of Interest Lateral Velocity Covariance Authenticated";
BA_ "SignalType" SG_ 245 SRRLFODPB4P_VOTk9TypCnfdAuth "ENM";
BA_ "SignalLongName" SG_ 245 SRRLFODPB4P_VOTk9TypCnfdAuth "Short Range Radar Left Front Object Detection and Processing Burst 4 Protected : Vehicle Object Track 9 Type Confidence Authenticated";
BA_ "SignalLongName" SG_ 245 SRRLFODPB4P_Filler "Short Range Radar Left Front Object Detection and Processing Burst 4 Protected : Filler";
VAL_ 69 AdpLgtHstLnLtTyp 0 "Undecided" 1 "Solid" 2 "Dashed" 3 "Road Edge" 4 "Double Line" 5 "Botts Dots" 6 "Virtual" 7 "Triple Line" ;
VAL_ 69 AdpLgtHstLnRtQlty 0 "Very Low Quality" 1 "Low Quality" 2 "Prediction" 3 "High Quality" ;
VAL_ 69 AdpLgtHstLnLtQlty 0 "Very Low Quality" 1 "Low Quality" 2 "Prediction" 3 "High Quality" ;
VAL_ 69 AdpLgtHstLnRtTyp 0 "Undecided" 1 "Solid" 2 "Dashed" 3 "Road Edge" 4 "Double Line" 5 "Botts Dots" 6 "Virtual" 7 "Triple Line" ;
VAL_ 225 ALOI3_TypTk11 0 "UNKNOWN" 1 "4 WHEEL VEHICLE" 2 "LARGE VEHICLE" 3 "MOTORCYCLE/BICYCLE" 4 "PEDESTRIAN" 5 "FIXED OVERHEAD OBJECT" 6 "FIXED ROADSIDE OBJECT" 7 "NO OBJECT PRESENT" 8 "PEDESTRIAN STANDING OUTSIDE DANGER ZONE" 9 "PEDESTRIAN MOVING OUT OF DANGER ZONE" 10 "PEDESTRIAN MOVING INTO DANGER ZONE" 11 "CHILD CLOSE TO DANGER ZONE" 12 "CLUSTER OBJECT" ;
VAL_ 225 ALOI3_TypTk10 0 "UNKNOWN" 1 "4 WHEEL VEHICLE" 2 "LARGE VEHICLE" 3 "MOTORCYCLE/BICYCLE" 4 "PEDESTRIAN" 5 "FIXED OVERHEAD OBJECT" 6 "FIXED ROADSIDE OBJECT" 7 "NO OBJECT PRESENT" 8 "PEDESTRIAN STANDING OUTSIDE DANGER ZONE" 9 "PEDESTRIAN MOVING OUT OF DANGER ZONE" 10 "PEDESTRIAN MOVING INTO DANGER ZONE" 11 "CHILD CLOSE TO DANGER ZONE" 12 "CLUSTER OBJECT" ;
VAL_ 225 ALOI3_TypTk9 0 "UNKNOWN" 1 "4 WHEEL VEHICLE" 2 "LARGE VEHICLE" 3 "MOTORCYCLE/BICYCLE" 4 "PEDESTRIAN" 5 "FIXED OVERHEAD OBJECT" 6 "FIXED ROADSIDE OBJECT" 7 "NO OBJECT PRESENT" 8 "PEDESTRIAN STANDING OUTSIDE DANGER ZONE" 9 "PEDESTRIAN MOVING OUT OF DANGER ZONE" 10 "PEDESTRIAN MOVING INTO DANGER ZONE" 11 "CHILD CLOSE TO DANGER ZONE" 12 "CLUSTER OBJECT" ;
VAL_ 225 ALOI3_TypTk12 0 "UNKNOWN" 1 "4 WHEEL VEHICLE" 2 "LARGE VEHICLE" 3 "MOTORCYCLE/BICYCLE" 4 "PEDESTRIAN" 5 "FIXED OVERHEAD OBJECT" 6 "FIXED ROADSIDE OBJECT" 7 "NO OBJECT PRESENT" 8 "PEDESTRIAN STANDING OUTSIDE DANGER ZONE" 9 "PEDESTRIAN MOVING OUT OF DANGER ZONE" 10 "PEDESTRIAN MOVING INTO DANGER ZONE" 11 "CHILD CLOSE TO DANGER ZONE" 12 "CLUSTER OBJECT" ;
VAL_ 225 ALOI3_DirTk11 0 "Following" 1 "Oncoming" 2 "Following Goup" 3 "Oncoming Group" 4 "Unknown" ;
VAL_ 225 ALOI3_DirTk10 0 "Following" 1 "Oncoming" 2 "Following Goup" 3 "Oncoming Group" 4 "Unknown" ;
VAL_ 225 ALOI3_DirTk9 0 "Following" 1 "Oncoming" 2 "Following Goup" 3 "Oncoming Group" 4 "Unknown" ;
VAL_ 225 ALOI3_DirTk12 0 "Following" 1 "Oncoming" 2 "Following Goup" 3 "Oncoming Group" 4 "Unknown" ;
VAL_ 225 ALOI3_CnfdTk9 0 "Highly Speculative" 1 "Speculative" 2 "Confident" 3 "Highly Confident" ;
VAL_ 225 ALOI3_CnfdTk12 0 "Highly Speculative" 1 "Speculative" 2 "Confident" 3 "Highly Confident" ;
VAL_ 225 ALOI3_CnfdTk11 0 "Highly Speculative" 1 "Speculative" 2 "Confident" 3 "Highly Confident" ;
VAL_ 225 ALOI3_CnfdTk10 0 "Highly Speculative" 1 "Speculative" 2 "Confident" 3 "Highly Confident" ;
VAL_ 225 ALOI3_MeasStsTk9 0 "No Object" 1 "New Object" 2 "Latent Track Not Detected This Cycle" 3 "Measured This Cycle" ;
VAL_ 225 ALOI3_MeasStsTk12 0 "No Object" 1 "New Object" 2 "Latent Track Not Detected This Cycle" 3 "Measured This Cycle" ;
VAL_ 225 ALOI3_MeasStsTk11 0 "No Object" 1 "New Object" 2 "Latent Track Not Detected This Cycle" 3 "Measured This Cycle" ;
VAL_ 225 ALOI3_MeasStsTk10 0 "No Object" 1 "New Object" 2 "Latent Track Not Detected This Cycle" 3 "Measured This Cycle" ;
VAL_ 225 ALOI3_RltvLnTk9 0 "Unknown" 1 "Host Lane" 2 "Right Lane" 3 "Left Lane" ;
VAL_ 225 ALOI3_RltvLnTk12 0 "Unknown" 1 "Host Lane" 2 "Right Lane" 3 "Left Lane" ;
VAL_ 225 ALOI3_RltvLnTk11 0 "Unknown" 1 "Host Lane" 2 "Right Lane" 3 "Left Lane" ;
VAL_ 225 ALOI3_RltvLnTk10 0 "Unknown" 1 "Host Lane" 2 "Right Lane" 3 "Left Lane" ;
VAL_ 225 TrfcSgnMemFtrSts 0 "OFF" 1 "ACTIVE" 2 "FAILED" ;
VAL_ 225 ALOI3_RngTk9_Inv 0 "FALSE" 1 "TRUE" ;
VAL_ 225 ALOI3_RngTk12_Inv 0 "FALSE" 1 "TRUE" ;
VAL_ 225 ALOI3_RngTk11_Inv 0 "FALSE" 1 "TRUE" ;
VAL_ 225 ALOI3_RngTk10_Inv 0 "FALSE" 1 "TRUE" ;
VAL_ 225 ALOI3_AcqTmStm_Inv 0 "FALSE" 1 "TRUE" ;
VAL_ 963 NodeStsADIMb_CAN_9_LcFA 0 "FALSE" 1 "TRUE" ;
VAL_ 963 NodeStsADIMb_CAN_3_LcFA 0 "FALSE" 1 "TRUE" ;
VAL_ 963 NodeStsADIMb_CAN_2_LcFA 0 "FALSE" 1 "TRUE" ;
VAL_ 963 NodeStsADIMb_CAN_10_LcFA 0 "FALSE" 1 "TRUE" ;
VAL_ 963 NodeStsADIMa_CAN_9_LcFA 0 "FALSE" 1 "TRUE" ;
VAL_ 963 NodeStsADIMa_CAN_3_LcFA 0 "FALSE" 1 "TRUE" ;
VAL_ 963 NodeStsADIMa_CAN_2_LcFA 0 "FALSE" 1 "TRUE" ;
VAL_ 963 NodeStsADIMa_CAN_10_LcFA 0 "FALSE" 1 "TRUE" ;
VAL_ 963 NodeStsAPA_CAN_1_LcFA 0 "FALSE" 1 "TRUE" ;
VAL_ 963 NodeStsAOS_LcFA 0 "FALSE" 1 "TRUE" ;
VAL_ 963 NodeStsAMP_LcFA 0 "FALSE" 1 "TRUE" ;
VAL_ 963 NodeStsALC_LcFA 0 "FALSE" 1 "TRUE" ;
VAL_ 963 NodeStsAHS_LcFA 0 "FALSE" 1 "TRUE" ;
VAL_ 963 NodeStsAHL_AFL_CAN_2_LcFA 0 "FALSE" 1 "TRUE" ;
VAL_ 963 NodeStsBSM_MH_LcFA 0 "FALSE" 1 "TRUE" ;
VAL_ 963 NodeStsBSM_CAN_3_LcFA 0 "FALSE" 1 "TRUE" ;
VAL_ 963 NodeStsBSM_CAN_2_LcFA 0 "FALSE" 1 "TRUE" ;
VAL_ 963 NodeStsBCM_LcFA 0 "FALSE" 1 "TRUE" ;
VAL_ 963 NodeStsARS_LcFA 0 "FALSE" 1 "TRUE" ;
VAL_ 963 NodeStsARB_LcFA 0 "FALSE" 1 "TRUE" ;
VAL_ 963 NodeStsAPA_CAN_2_LcFA 0 "FALSE" 1 "TRUE" ;
VAL_ 963 NodeStsEBCM_AV_CAN_2_LcFA 0 "FALSE" 1 "TRUE" ;
VAL_ 963 NodeStsDMS_LcFA 0 "FALSE" 1 "TRUE" ;
VAL_ 963 NodeStsDEFC_LcFA 0 "FALSE" 1 "TRUE" ;
VAL_ 963 NodeStsDCM_LcFA 0 "FALSE" 1 "TRUE" ;
VAL_ 963 NodeStsCSM_CAN_5_LcFA 0 "FALSE" 1 "TRUE" ;
VAL_ 963 NodeStsECP_E_CAN_9_LcFA 0 "FALSE" 1 "TRUE" ;
VAL_ 963 NodeStsECP_E_CAN_2_LcFA 0 "FALSE" 1 "TRUE" ;
VAL_ 963 NodeStsECM_CAN_3_LcFA 0 "FALSE" 1 "TRUE" ;
VAL_ 963 NodeStsECM_CAN_2_LcFA 0 "FALSE" 1 "TRUE" ;
VAL_ 963 NodeStsEBCM_CAN_3_LcFA 0 "FALSE" 1 "TRUE" ;
VAL_ 963 NodeStsEBCM_CAN_2_LcFA 0 "FALSE" 1 "TRUE" ;
VAL_ 963 NodeStsEBCM_AV_CAN_3_LcFA 0 "FALSE" 1 "TRUE" ;
VAL_ 963 NodeStsEOCM_CAN_3_LcFA 0 "FALSE" 1 "TRUE" ;
VAL_ 963 NodeStsEOCM_CAN_2_LcFA 0 "FALSE" 1 "TRUE" ;
VAL_ 963 NodeStsELM_LcFA 0 "FALSE" 1 "TRUE" ;
VAL_ 963 NodeStsECP_X1_CAN_3_LcFA 0 "FALSE" 1 "TRUE" ;
VAL_ 963 NodeStsECP_X1_CAN_2_LcFA 0 "FALSE" 1 "TRUE" ;
VAL_ 963 NodeStsECP_S_CAN_9_LcFA 0 "FALSE" 1 "TRUE" ;
VAL_ 963 NodeStsECP_S_CAN_2_LcFA 0 "FALSE" 1 "TRUE" ;
VAL_ 963 NodeStsECP_MC_LcFA 0 "FALSE" 1 "TRUE" ;
VAL_ 963 NodeStsEPSRAa_LcFA 0 "FALSE" 1 "TRUE" ;
VAL_ 963 NodeStsEPS_LcFA 0 "FALSE" 1 "TRUE" ;
VAL_ 963 NodeStsEPS_1_LcFA 0 "FALSE" 1 "TRUE" ;
VAL_ 963 NodeStsEOCM_HCP2_LcFA 0 "FALSE" 1 "TRUE" ;
VAL_ 963 NodeStsEOCM_HCP1_CAN_8_LcFA 0 "FALSE" 1 "TRUE" ;
VAL_ 963 NodeStsEOCM_HCP1_CAN_3_LcFA 0 "FALSE" 1 "TRUE" ;
VAL_ 963 NodeStsEOCM_HCP1_CAN_2_LcFA 0 "FALSE" 1 "TRUE" ;
VAL_ 963 NodeStsEOCM_CAN_8_LcFA 0 "FALSE" 1 "TRUE" ;
VAL_ 963 NodeStsHVAC_FP_F_LcFA 0 "FALSE" 1 "TRUE" ;
VAL_ 963 NodeStsHUD_CAN_LcFA 0 "FALSE" 1 "TRUE" ;
VAL_ 963 NodeStsHDLM_LcFA 0 "FALSE" 1 "TRUE" ;
VAL_ 963 NodeStsFOPM_CAN_3_LcFA 0 "FALSE" 1 "TRUE" ;
VAL_ 963 NodeStsFOPM_CAN_2_LcFA 0 "FALSE" 1 "TRUE" ;
VAL_ 963 NodeStsFCM_LcFA 0 "FALSE" 1 "TRUE" ;
VAL_ 963 NodeStsFCM_LC_LcFA 0 "FALSE" 1 "TRUE" ;
VAL_ 963 NodeStsEPSRAb_LcFA 0 "FALSE" 1 "TRUE" ;
VAL_ 964 NodeStsMFC_LcFA 0 "FALSE" 1 "TRUE" ;
VAL_ 964 NodeStsLRR_LcFA 0 "FALSE" 1 "TRUE" ;
VAL_ 964 NodeStsLIB1_LcFA 0 "FALSE" 1 "TRUE" ;
VAL_ 964 NodeStsIPC_CAN_5_LcFA 0 "FALSE" 1 "TRUE" ;
VAL_ 964 NodeStsICS_Info_LcFA 0 "FALSE" 1 "TRUE" ;
VAL_ 964 NodeStsICCM_CAN_3_LcFA 0 "FALSE" 1 "TRUE" ;
VAL_ 964 NodeStsHVAC_FP_R_LcFA 0 "FALSE" 1 "TRUE" ;
VAL_ 964 NodeStsMSM_RR_LcFA 0 "FALSE" 1 "TRUE" ;
VAL_ 964 NodeStsMSM_P_LcFA 0 "FALSE" 1 "TRUE" ;
VAL_ 964 NodeStsMSM_LR_LcFA 0 "FALSE" 1 "TRUE" ;
VAL_ 964 NodeStsMSM_D_LcFA 0 "FALSE" 1 "TRUE" ;
VAL_ 964 NodeStsMSB2_LcFA 0 "FALSE" 1 "TRUE" ;
VAL_ 964 NodeStsMSB1_LcFA 0 "FALSE" 1 "TRUE" ;
VAL_ 964 NodeStsMRCM_R_LcFA 0 "FALSE" 1 "TRUE" ;
VAL_ 964 NodeStsMRCM_L_LcFA 0 "FALSE" 1 "TRUE" ;
VAL_ 964 NodeStsRDCM_LcFA 0 "FALSE" 1 "TRUE" ;
VAL_ 964 NodeStsRadioLow_LcFA 0 "FALSE" 1 "TRUE" ;
VAL_ 964 NodeStsPTM_LcFA 0 "FALSE" 1 "TRUE" ;
VAL_ 964 NodeStsPDR_LcFA 0 "FALSE" 1 "TRUE" ;
VAL_ 964 NodeStsPA_LcFA 0 "FALSE" 1 "TRUE" ;
VAL_ 964 NodeStsNVM_LcFA 0 "FALSE" 1 "TRUE" ;
VAL_ 964 NodeStsMTCM_R_LcFA 0 "FALSE" 1 "TRUE" ;
VAL_ 964 NodeStsMTCM_L_LcFA 0 "FALSE" 1 "TRUE" ;
VAL_ 964 NodeStsSBM_CAN_3_LcFA 0 "FALSE" 1 "TRUE" ;
VAL_ 964 NodeStsSAM_RR_LcFA 0 "FALSE" 1 "TRUE" ;
VAL_ 964 NodeStsSAM_RF_LcFA 0 "FALSE" 1 "TRUE" ;
VAL_ 964 NodeStsSAM_LR_LcFA 0 "FALSE" 1 "TRUE" ;
VAL_ 964 NodeStsSAM_LF_LcFA 0 "FALSE" 1 "TRUE" ;
VAL_ 964 NodeStsSADS_LcFA 0 "FALSE" 1 "TRUE" ;
VAL_ 964 NodeStsSRR_RF_LcFA 0 "FALSE" 1 "TRUE" ;
VAL_ 964 NodeStsSRR_LR_CR_LcFA 0 "FALSE" 1 "TRUE" ;
VAL_ 964 NodeStsSRR_LF_LcFA 0 "FALSE" 1 "TRUE" ;
VAL_ 964 NodeStsSIB_LcFA 0 "FALSE" 1 "TRUE" ;
VAL_ 964 NodeStsSDM_LcFA 0 "FALSE" 1 "TRUE" ;
VAL_ 964 NodeStsSCL_LcFA 0 "FALSE" 1 "TRUE" ;
VAL_ 964 NodeStsSBZA_R_LcFA 0 "FALSE" 1 "TRUE" ;
VAL_ 964 NodeStsSBZA_L_LcFA 0 "FALSE" 1 "TRUE" ;
VAL_ 964 NodeStsTCP_CAN_5_LcFA 0 "FALSE" 1 "TRUE" ;
VAL_ 964 NodeStsTCM_CAN_2_LcFA 0 "FALSE" 1 "TRUE" ;
VAL_ 964 NodeStsTCCM_LcFA 0 "FALSE" 1 "TRUE" ;
VAL_ 964 NodeStsSRR_SRR_LcFA 0 "FALSE" 1 "TRUE" ;
VAL_ 964 NodeStsSRR_SLR_LcFA 0 "FALSE" 1 "TRUE" ;
VAL_ 964 NodeStsSRR_RR_LcFA 0 "FALSE" 1 "TRUE" ;
VAL_ 964 NodeStsWCM_LcFA 0 "FALSE" 1 "TRUE" ;
VAL_ 964 NodeStsVPM_LcFA 0 "FALSE" 1 "TRUE" ;
VAL_ 964 NodeStsVLM_LcFA 0 "FALSE" 1 "TRUE" ;
VAL_ 964 NodeStsVKM_LcFA 0 "FALSE" 1 "TRUE" ;
VAL_ 964 NodeStsVICM_CAN_9_LcFA 0 "FALSE" 1 "TRUE" ;
VAL_ 964 NodeStsVICM_CAN_2_LcFA 0 "FALSE" 1 "TRUE" ;
VAL_ 964 NodeStsVCU_CAN_5_LcFA 0 "FALSE" 1 "TRUE" ;
VAL_ 964 NodeStsTIM_LcFA 0 "FALSE" 1 "TRUE" ;
VAL_ 964 NodeStsECP_S2_CAN_2_LcFA 0 "FALSE" 1 "TRUE" ;
VAL_ 964 NodeStsPFCM_LcFA 0 "FALSE" 1 "TRUE" ;
VAL_ 964 NodeStsVDM_CAN_2_LcFA 0 "FALSE" 1 "TRUE" ;
VAL_ 964 NodeStsPCM_CAN_3_LcFA 0 "FALSE" 1 "TRUE" ;
VAL_ 964 NodeStsPCM_CAN_2_LcFA 0 "FALSE" 1 "TRUE" ;
VAL_ 964 NodeStsSDM_AV_LcFA 0 "FALSE" 1 "TRUE" ;
VAL_ 962 NodeStsACP4_MCU_CAN_2_LcFA 0 "FALSE" 1 "TRUE" ;
VAL_ 962 NodeStsACP2_MCU_CAN_8_LcFA 0 "FALSE" 1 "TRUE" ;
VAL_ 962 NodeStsACP2_MCU_CAN_2_LcFA 0 "FALSE" 1 "TRUE" ;
VAL_ 962 NodeStsVECM_CAN_2_LcFA 0 "FALSE" 1 "TRUE" ;
VAL_ 962 NodeStsVDM_CAN_9_LcFA 0 "FALSE" 1 "TRUE" ;
VAL_ 962 NodeStsUVM_CAN_1_LcFA 0 "FALSE" 1 "TRUE" ;
VAL_ 962 NodeStsUPM_LcFA 0 "FALSE" 1 "TRUE" ;
VAL_ 962 NodeStsEPSb_LcFA 0 "FALSE" 1 "TRUE" ;
VAL_ 962 NodeStsSBM_CAN_10_LcFA 0 "FALSE" 1 "TRUE" ;
VAL_ 962 NodeStsVECM_CAN_9_LcFA 0 "FALSE" 1 "TRUE" ;
VAL_ 962 NodeStsECP_S2_CAN_9_LcFA 0 "FALSE" 1 "TRUE" ;
VAL_ 962 NodeStsCSM_AV_CAN_5_LcFA 0 "FALSE" 1 "TRUE" ;
VAL_ 962 NodeStsACP3_MCU_CAN_3_LcFA 0 "FALSE" 1 "TRUE" ;
VAL_ 962 NodeStsACP3_MCU_CAN_8_LcFA 0 "FALSE" 1 "TRUE" ;
VAL_ 962 NodeStsACP3_MCU_CAN_2_LcFA 0 "FALSE" 1 "TRUE" ;
VAL_ 962 NodeStsWCM4_LcFA 0 "FALSE" 1 "TRUE" ;
VAL_ 962 NodeStsWCM3_LcFA 0 "FALSE" 1 "TRUE" ;
VAL_ 962 NodeStsWCM2_LcFA 0 "FALSE" 1 "TRUE" ;
VAL_ 962 NodeStsRSI_CAN_5_LcFA 0 "FALSE" 1 "TRUE" ;
VAL_ 962 NodeStsLIB_48V_LcFA 0 "FALSE" 1 "TRUE" ;
VAL_ 962 NodeStsFPI_CAN_5_LcFA 0 "FALSE" 1 "TRUE" ;
VAL_ 962 NodeStsACP4_MCU_CAN_3_LcFA 0 "FALSE" 1 "TRUE" ;
VAL_ 962 NodeStsACP4_MCU_CAN_8_LcFA 0 "FALSE" 1 "TRUE" ;
VAL_ 962 NodeStsBSM_HEV_CAN_2_LcFA 0 "FALSE" 1 "TRUE" ;
VAL_ 962 NodeStsECP_H3_CAN_2_LcFA 0 "FALSE" 1 "TRUE" ;
VAL_ 962 NodeStsECP_H2_CAN_2_LcFA 0 "FALSE" 1 "TRUE" ;
VAL_ 962 NodeStsECP_H2_CAN_9_LcFA 0 "FALSE" 1 "TRUE" ;
VAL_ 962 NodeStsECP_H1_CAN_9_LcFA 0 "FALSE" 1 "TRUE" ;
VAL_ 962 NodeStsECP_H1_CAN_2_LcFA 0 "FALSE" 1 "TRUE" ;
VAL_ 962 NodeStsBSM_HEV_CAN_9_LcFA 0 "FALSE" 1 "TRUE" ;
VAL_ 962 NodeStsECP_H3_CAN_9_LcFA 0 "FALSE" 1 "TRUE" ;
VAL_ 962 NodeStsSAM_BH_LcFA 0 "FALSE" 1 "TRUE" ;
VAL_ 962 NodeStsPLCM_LcFA 0 "FALSE" 1 "TRUE" ;
VAL_ 962 NodeStsODS_LcFA 0 "FALSE" 1 "TRUE" ;
VAL_ 962 NodeStsODS2_LcFA 0 "FALSE" 1 "TRUE" ;
VAL_ 952 NodeStsSRR_SRR_Prsnt 0 "FALSE" 1 "TRUE" ;
VAL_ 952 NodeStsEOCM_HCP2_Prsnt 0 "FALSE" 1 "TRUE" ;
VAL_ 952 NodeStsEOCM_HCP1_CAN_3_Prsnt 0 "FALSE" 1 "TRUE" ;
VAL_ 952 NodeStsFCM_Prsnt 0 "FALSE" 1 "TRUE" ;
VAL_ 952 NodeStsSBZA_L_Prsnt 0 "FALSE" 1 "TRUE" ;
VAL_ 952 NodeStsMSM_LR_Prsnt 0 "FALSE" 1 "TRUE" ;
VAL_ 952 NodeStsACP2_MCU_CAN_2_Prsnt 0 "FALSE" 1 "TRUE" ;
VAL_ 952 NodeStsMSM_P_Prsnt 0 "FALSE" 1 "TRUE" ;
VAL_ 952 NodeStsACP4_MCU_CAN_3_Prsnt 0 "FALSE" 1 "TRUE" ;
VAL_ 953 NodeStsACP3_MCU_CAN_3_Prsnt 0 "FALSE" 1 "TRUE" ;
VAL_ 953 NodeStsEOCM_CAN_2_Prsnt 0 "FALSE" 1 "TRUE" ;
VAL_ 953 NodeStsACP2_MCU_CAN_8_Prsnt 0 "FALSE" 1 "TRUE" ;
VAL_ 953 NodeStsFCM_LC_Prsnt 0 "FALSE" 1 "TRUE" ;
VAL_ 953 NodeStsEOCM_HCP1_CAN_2_Prsnt 0 "FALSE" 1 "TRUE" ;
VAL_ 953 NodeStsSRR_LF_Prsnt 0 "FALSE" 1 "TRUE" ;
VAL_ 953 NodeStsSRR_RF_Prsnt 0 "FALSE" 1 "TRUE" ;
VAL_ 953 NodeStsACP3_MCU_CAN_8_Prsnt 0 "FALSE" 1 "TRUE" ;
VAL_ 953 NodeStsSBZA_R_Prsnt 0 "FALSE" 1 "TRUE" ;
VAL_ 953 NodeStsSRR_LR_CR_Prsnt 0 "FALSE" 1 "TRUE" ;
VAL_ 953 NodeStsSRR_RR_Prsnt 0 "FALSE" 1 "TRUE" ;
VAL_ 953 NodeStsSRR_SLR_Prsnt 0 "FALSE" 1 "TRUE" ;
VAL_ 953 NodeStsEOCM_HCP1_CAN_8_Prsnt 0 "FALSE" 1 "TRUE" ;
VAL_ 954 NodeStsMSM_RR_Prsnt 0 "FALSE" 1 "TRUE" ;
VAL_ 954 NodeStsEOCM_CAN_8_Prsnt 0 "FALSE" 1 "TRUE" ;
VAL_ 954 NodeStsMSM_D_Prsnt 0 "FALSE" 1 "TRUE" ;
VAL_ 954 NodeStsACP3_MCU_CAN_2_Prsnt 0 "FALSE" 1 "TRUE" ;
VAL_ 954 NodeStsACP4_MCU_CAN_2_Prsnt 0 "FALSE" 1 "TRUE" ;
VAL_ 954 NodeStsEOCM_CAN_3_Prsnt 0 "FALSE" 1 "TRUE" ;
VAL_ 954 NodeStsACP4_MCU_CAN_8_Prsnt 0 "FALSE" 1 "TRUE" ;
VAL_ 1322 FrtPsngrAirbagDsblVisIndCmd 0 "On" 1 "Off" 2 "Flash" ;
VAL_ 1322 ORIP_EnvModPrsntRsp1Auth 0 "FALSE" 1 "TRUE" ;
VAL_ 1322 ORIP_DrvrStBltStsAuth_Inv 0 "FALSE" 1 "TRUE" ;
VAL_ 1322 ORIP_DrvrStBltStsAuth 0 "Unknown" 1 "UnFastened" 2 "Fastened" ;
VAL_ 1322 RstrntSysFltPrsnt 0 "FALSE" 1 "TRUE" ;
VAL_ 1322 FrtPsngrAirbagEnblVisIndCmd 0 "On" 1 "Off" 2 "Flash" ;
VAL_ 1320 PCIP_HzrdLgtsOnReqdAuth 0 "FALSE" 1 "TRUE" ;
VAL_ 1320 PCIP_HybVehHiVltgDsblReqdAuth 0 "FALSE" 1 "TRUE" ;
VAL_ 1320 PCIP_HVCrshImpSnsSysDsbldAuth 0 "FALSE" 1 "TRUE" ;
VAL_ 1320 PCIP_HVACBlwDsblReqdAuth 0 "FALSE" 1 "TRUE" ;
VAL_ 1320 PCIP_FuelCutOffReqdAuth 0 "FALSE" 1 "TRUE" ;
VAL_ 1320 PCIP_DrUnlckReqdAuth 0 "FALSE" 1 "TRUE" ;
VAL_ 1320 PCIP_CruzCtlDsblReqdAuth 0 "FALSE" 1 "TRUE" ;
VAL_ 1320 PCIP_BrkActReqdAuth 0 "FALSE" 1 "TRUE" ;
VAL_ 1320 PCIP_NftnFrtImpPrtnsrSevAchAuth 0 "FALSE" 1 "TRUE" ;
VAL_ 1320 PCIP_MemStRclDsblReqdAuth 0 "FALSE" 1 "TRUE" ;
VAL_ 1320 PCIP_IntrLgtOnReqdAuth 0 "FALSE" 1 "TRUE" ;
VAL_ 1320 PCIP_NtfnLtSdSevAchvdAuth 0 "FALSE" 1 "TRUE" ;
VAL_ 1320 PCIP_NtfnFrtImpStg2SevAchvdAuth 0 "FALSE" 1 "TRUE" ;
VAL_ 1320 PCIP_NtfnFrtImpStg1SevAchvdAuth 0 "FALSE" 1 "TRUE" ;
VAL_ 1320 PCIP_NtfnEvntStsAuth 0 "No Event" 1 "Near Deploy Event" 2 "Deployment Event" ;
VAL_ 1320 PCIP_eCallReqdAuth 0 "FALSE" 1 "TRUE" ;
VAL_ 1320 PCIP_NtfnRtSdSevAchvdAuth 0 "FALSE" 1 "TRUE" ;
VAL_ 1320 PCIP_NtfnRrImpSevAchvdAuth 0 "FALSE" 1 "TRUE" ;
VAL_ 1320 PCIP_NtfnRlOvrSevAchvdAuth 0 "FALSE" 1 "TRUE" ;
VAL_ 1320 PCIP_NtfnPedtrnPrtctnSevAchAuth 0 "FALSE" 1 "TRUE" ;
VAL_ 1426 RtSdObjDtdAdjTrlr 0 "FALSE" 1 "TRUE" ;
VAL_ 244 SRRLFODPB2P_POTk3DynPrpAuth 0 "Has Never Moved" 1 "Has Moved But Currently Stopped" 2 "Moving In Same Direction As Host" 3 "Moving In Opposite Direction As Host" 4 "Crossing Path" ;
VAL_ 244 SRRLFODPB2P_POTk3CnfdStsAuth 0 "Highly Speculative" 1 "Speculative" 2 "Confident" 3 "Highly Confident" ;
VAL_ 244 SRRLFODPB2P_POTk3MStsAuth 0 "No Object" 1 "New Object" 2 "Latent Track Not Detected this Cycle" 3 "Measured this Cycle" ;
VAL_ 244 SRRLFODPB2P_POTk3TypCnfdAuth 0 "Highly Speculative" 1 "Speculative" 2 "Confident" 3 "Highly Confident" ;
VAL_ 244 SRRLFODPB2P_POTk3TypAuth 0 "Unknown" 1 "Pedestrian" 2 "Bicycle" ;
VAL_ 244 SRRLFODPB2P_VOTk2DynPrpStsAuth 0 "Stopped" 1 "Not Stopped" ;
VAL_ 244 SRRLFODPB2P_VOTk2DynPrpAuth 0 "Has Never Moved" 1 "Moving In Same Direction As Host" 2 "Moving In Opposite Direction As Host" 3 "Crossing From Left To Right" 4 "Crossing From Right To Left" ;
VAL_ 244 SRRLFODPB2P_VOTk2CnfdStsAuth 0 "Highly Speculative" 1 "Speculative" 2 "Confident" 3 "Highly Confident" ;
VAL_ 244 SRRLFODPB2P_VOTk2MStsAuth 0 "No Object" 1 "New Object" 2 "Latent Track Not Detected this Cycle" 3 "Measured this Cycle" ;
VAL_ 244 SRRLFODPB2P_VOTk2TypCnfdAuth 0 "Highly Speculative" 1 "Speculative" 2 "Confident" 3 "Highly Confident" ;
VAL_ 244 SRRLFODPB2P_VOTk3CnfdStsAuth 0 "Highly Speculative" 1 "Speculative" 2 "Confident" 3 "Highly Confident" ;
VAL_ 244 SRRLFODPB2P_VOTk3DynPrpStsAuth 0 "Stopped" 1 "Not Stopped" ;
VAL_ 244 SRRLFODPB2P_VOTk3DynPrpAuth 0 "Has Never Moved" 1 "Moving In Same Direction As Host" 2 "Moving In Opposite Direction As Host" 3 "Crossing From Left To Right" 4 "Crossing From Right To Left" ;
VAL_ 244 SRRLFODPB2P_VOTk3MStsAuth 0 "No Object" 1 "New Object" 2 "Latent Track Not Detected this Cycle" 3 "Measured this Cycle" ;
VAL_ 244 SRRLFODPB2P_VOTk3TypCnfdAuth 0 "Highly Speculative" 1 "Speculative" 2 "Confident" 3 "Highly Confident" ;
VAL_ 244 SRRLFODPB2P_VOTk4DynPrpStsAuth 0 "Stopped" 1 "Not Stopped" ;
VAL_ 244 SRRLFODPB2P_VOTk4DynPrpAuth 0 "Has Never Moved" 1 "Moving In Same Direction As Host" 2 "Moving In Opposite Direction As Host" 3 "Crossing From Left To Right" 4 "Crossing From Right To Left" ;
VAL_ 244 SRRLFODPB2P_VOTk4CnfdStsAuth 0 "Highly Speculative" 1 "Speculative" 2 "Confident" 3 "Highly Confident" ;
VAL_ 244 SRRLFODPB2P_VOTk4MStsAuth 0 "No Object" 1 "New Object" 2 "Latent Track Not Detected this Cycle" 3 "Measured this Cycle" ;
VAL_ 244 SRRLFODPB2P_VOTk4TypCnfdAuth 0 "Highly Speculative" 1 "Speculative" 2 "Confident" 3 "Highly Confident" ;
VAL_ 211 SRRLFODPB3P_POTk4DynPrpAuth 0 "Has Never Moved" 1 "Has Moved But Currently Stopped" 2 "Moving In Same Direction As Host" 3 "Moving In Opposite Direction As Host" 4 "Crossing Path" ;
VAL_ 211 SRRLFODPB3P_POTk4CnfdStsAuth 0 "Highly Speculative" 1 "Speculative" 2 "Confident" 3 "Highly Confident" ;
VAL_ 211 SRRLFODPB3P_POTk4MStsAuth 0 "No Object" 1 "New Object" 2 "Latent Track Not Detected this Cycle" 3 "Measured this Cycle" ;
VAL_ 211 SRRLFODPB3P_POTk4TypCnfdAuth 0 "Highly Speculative" 1 "Speculative" 2 "Confident" 3 "Highly Confident" ;
VAL_ 211 SRRLFODPB3P_POTk4TypAuth 0 "Unknown" 1 "Pedestrian" 2 "Bicycle" ;
VAL_ 211 SRRLFODPB3P_VOTk5DynPrpStsAuth 0 "Stopped" 1 "Not Stopped" ;
VAL_ 211 SRRLFODPB3P_VOTk5DynPrpAuth 0 "Has Never Moved" 1 "Moving In Same Direction As Host" 2 "Moving In Opposite Direction As Host" 3 "Crossing From Left To Right" 4 "Crossing From Right To Left" ;
VAL_ 211 SRRLFODPB3P_VOTk5CnfdStsAuth 0 "Highly Speculative" 1 "Speculative" 2 "Confident" 3 "Highly Confident" ;
VAL_ 211 SRRLFODPB3P_VOTk5MStsAuth 0 "No Object" 1 "New Object" 2 "Latent Track Not Detected this Cycle" 3 "Measured this Cycle" ;
VAL_ 211 SRRLFODPB3P_VOTk5TypCnfdAuth 0 "Highly Speculative" 1 "Speculative" 2 "Confident" 3 "Highly Confident" ;
VAL_ 211 SRRLFODPB3P_VOTk6CnfdStsAuth 0 "Highly Speculative" 1 "Speculative" 2 "Confident" 3 "Highly Confident" ;
VAL_ 211 SRRLFODPB3P_VOTk6DynPrpStsAuth 0 "Stopped" 1 "Not Stopped" ;
VAL_ 211 SRRLFODPB3P_VOTk6DynPrpAuth 0 "Has Never Moved" 1 "Moving In Same Direction As Host" 2 "Moving In Opposite Direction As Host" 3 "Crossing From Left To Right" 4 "Crossing From Right To Left" ;
VAL_ 211 SRRLFODPB3P_VOTk6MStsAuth 0 "No Object" 1 "New Object" 2 "Latent Track Not Detected this Cycle" 3 "Measured this Cycle" ;
VAL_ 211 SRRLFODPB3P_VOTk6TypCnfdAuth 0 "Highly Speculative" 1 "Speculative" 2 "Confident" 3 "Highly Confident" ;
VAL_ 211 SRRLFODPB3P_VOTk7DynPrpStsAuth 0 "Stopped" 1 "Not Stopped" ;
VAL_ 211 SRRLFODPB3P_VOTk7DynPrpAuth 0 "Has Never Moved" 1 "Moving In Same Direction As Host" 2 "Moving In Opposite Direction As Host" 3 "Crossing From Left To Right" 4 "Crossing From Right To Left" ;
VAL_ 211 SRRLFODPB3P_VOTk7CnfdStsAuth 0 "Highly Speculative" 1 "Speculative" 2 "Confident" 3 "Highly Confident" ;
VAL_ 211 SRRLFODPB3P_VOTk7MStsAuth 0 "No Object" 1 "New Object" 2 "Latent Track Not Detected this Cycle" 3 "Measured this Cycle" ;
VAL_ 211 SRRLFODPB3P_VOTk7TypCnfdAuth 0 "Highly Speculative" 1 "Speculative" 2 "Confident" 3 "Highly Confident" ;
VAL_ 245 SRRLFODPB4P_POTk5DynPrpAuth 0 "Has Never Moved" 1 "Has Moved But Currently Stopped" 2 "Moving In Same Direction As Host" 3 "Moving In Opposite Direction As Host" 4 "Crossing Path" ;
VAL_ 245 SRRLFODPB4P_POTk5CnfdStsAuth 0 "Highly Speculative" 1 "Speculative" 2 "Confident" 3 "Highly Confident" ;
VAL_ 245 SRRLFODPB4P_POTk5MStsAuth 0 "No Object" 1 "New Object" 2 "Latent Track Not Detected this Cycle" 3 "Measured this Cycle" ;
VAL_ 245 SRRLFODPB4P_POTk5TypCnfdAuth 0 "Highly Speculative" 1 "Speculative" 2 "Confident" 3 "Highly Confident" ;
VAL_ 245 SRRLFODPB4P_POTk5TypAuth 0 "Unknown" 1 "Pedestrian" 2 "Bicycle" ;
VAL_ 245 SRRLFODPB4P_VOTk10DynPrpStsAuth 0 "Stopped" 1 "Not Stopped" ;
VAL_ 245 SRRLFODPB4P_VOTk10DynPrpAuth 0 "Has Never Moved" 1 "Moving In Same Direction As Host" 2 "Moving In Opposite Direction As Host" 3 "Crossing From Left To Right" 4 "Crossing From Right To Left" ;
VAL_ 245 SRRLFODPB4P_VOTk10CnfdStsAuth 0 "Highly Speculative" 1 "Speculative" 2 "Confident" 3 "Highly Confident" ;
VAL_ 245 SRRLFODPB4P_VOTk10MStsAuth 0 "No Object" 1 "New Object" 2 "Latent Track Not Detected this Cycle" 3 "Measured this Cycle" ;
VAL_ 245 SRRLFODPB4P_VOTk10TypCnfdAuth 0 "Highly Speculative" 1 "Speculative" 2 "Confident" 3 "Highly Confident" ;
VAL_ 245 SRRLFODPB4P_VOTk8CnfdStsAuth 0 "Highly Speculative" 1 "Speculative" 2 "Confident" 3 "Highly Confident" ;
VAL_ 245 SRRLFODPB4P_VOTk8DynPrpStsAuth 0 "Stopped" 1 "Not Stopped" ;
VAL_ 245 SRRLFODPB4P_VOTk8DynPrpAuth 0 "Has Never Moved" 1 "Moving In Same Direction As Host" 2 "Moving In Opposite Direction As Host" 3 "Crossing From Left To Right" 4 "Crossing From Right To Left" ;
VAL_ 245 SRRLFODPB4P_VOTk8MStsAuth 0 "No Object" 1 "New Object" 2 "Latent Track Not Detected this Cycle" 3 "Measured this Cycle" ;
VAL_ 245 SRRLFODPB4P_VOTk8TypCnfdAuth 0 "Highly Speculative" 1 "Speculative" 2 "Confident" 3 "Highly Confident" ;
VAL_ 245 SRRLFODPB4P_VOTk9DynPrpStsAuth 0 "Stopped" 1 "Not Stopped" ;
VAL_ 245 SRRLFODPB4P_VOTk9DynPrpAuth 0 "Has Never Moved" 1 "Moving In Same Direction As Host" 2 "Moving In Opposite Direction As Host" 3 "Crossing From Left To Right" 4 "Crossing From Right To Left" ;
VAL_ 245 SRRLFODPB4P_VOTk9CnfdStsAuth 0 "Highly Speculative" 1 "Speculative" 2 "Confident" 3 "Highly Confident" ;
VAL_ 245 SRRLFODPB4P_VOTk9MStsAuth 0 "No Object" 1 "New Object" 2 "Latent Track Not Detected this Cycle" 3 "Measured this Cycle" ;
VAL_ 245 SRRLFODPB4P_VOTk9TypCnfdAuth 0 "Highly Speculative" 1 "Speculative" 2 "Confident" 3 "Highly Confident" ;
